VERSION ""

NS_ :

BS_:

BU_: RFA_BLEM TCU GWM _delete GENERIC TSTR

BO_ 1054 BrakeSysFeatures_3_FD2: 16 GWM
 SG_ SelDrvMdeChassis3_D_Rq : 61|5@0+ (1,0) [0|31] "SED"  GENERIC,_delete
 SG_ RbaBrk_D_Stat : 63|2@0+ (1,0) [0|3] "SED"  GENERIC,_delete
 SG_ SelDrvMdeChassis2_D_Rq : 45|5@0+ (1,0) [0|31] "SED"  GENERIC,_delete
 SG_ BrkBstrLoLampOn_B_Rq : 24|1@0+ (1,0) [0|1] "SED"  GENERIC,_delete
 SG_ TrailCtl_D_Stat : 55|3@0+ (1,0) [0|7] "SED"  GENERIC
 SG_ TrailCtlMsgTxt_D_Rq : 52|4@0+ (1,0) [0|15] "SED"  GENERIC
 SG_ BrkPadMsgTxt_D_Rq : 31|2@0+ (1,0) [0|3] "SED"  GENERIC,_delete
 SG_ BrkBstrVac_D_Stat : 18|2@0+ (1,0) [0|3] "SED"  GENERIC,_delete
 SG_ DrvSlipCtlOffLamp_D_Rq : 23|2@0+ (1,0) [0|3] "SED"  GENERIC,TCU,_delete
 SG_ DrvSlipCtlMdeMsg_D_Rq : 13|5@0+ (1,0) [0|31] "SED"  GENERIC,_delete
 SG_ HdcOn_B_Ind : 16|1@0+ (1,0) [0|1] "SED"  GENERIC
 SG_ AutoHoldMsgTxt_D_Rq : 4|4@0+ (1,0) [0|15] "SED"  GENERIC,_delete
 SG_ CtaBrk_D_Stat : 47|2@0+ (1,0) [0|3] "SED"  GENERIC,_delete
 SG_ SelDrvMdeAwd_D_Rq : 29|5@0+ (1,0) [0|31] "SED"  GENERIC
 SG_ AutoHoldSwMde_B_Ind : 0|1@0+ (1,0) [0|1] "SED"  GENERIC,_delete
 SG_ AutoHoldMde_D_Ind : 15|2@0+ (1,0) [0|3] "SED"  GENERIC,_delete
 SG_ BrkMdeInhbt_B_RqDsply : 8|1@0+ (1,0) [0|1] "SED"  GENERIC,_delete
 SG_ BrkLineLck_D_Stat : 21|3@0+ (1,0) [0|7] "SED"  GENERIC,_delete
 SG_ SelDrvMdeChassis_D_Rq : 39|5@0+ (1,0) [0|31] "SED"  GENERIC,_delete
 SG_ ApaBrk_D_Stat : 34|2@0+ (1,0) [0|3] "SED"  GENERIC,_delete,RFA_BLEM
 SG_ FrontDiffElckrOpen_B_Rq : 48|1@0+ (1,0) [0|1] "SED"  GENERIC,_delete
 SG_ OnePdlDrvDeny_B_Stat : 40|1@0+ (1,0) [0|1] "SED"  GENERIC,_delete
 SG_ BrkDrvMde_D_Stat : 7|3@0+ (1,0) [0|7] "SED"  GENERIC,_delete
 SG_ TrailOnePdlTqLm_B_Actl : 56|1@0+ (1,0) [0|1] "SED"  GENERIC,_delete

BO_ 931 Body_Info_9_FD2: 16 GWM
 SG_ VehOnSrc_D_Stat : 19|4@0+ (1,0) [0|15] "SED"  GENERIC,_delete,RFA_BLEM
 SG_ StrtrMtrCtlDStat_No_Cs : 31|8@0+ (1,0) [0|255] "unitless"  GENERIC,_delete
 SG_ EngStrtActv_B_Stat : 39|1@0+ (1,0) [0|1] "SED"  GENERIC,_delete
 SG_ EngStrt_B_Rq : 0|1@0+ (1,0) [0|1] "SED"  GENERIC,_delete
 SG_ DrvInCtl_B_Stat : 1|1@0+ (1,0) [0|1] "SED"  GENERIC,_delete
 SG_ PtWakeReas_D_Stat : 38|4@0+ (1,0) [0|15] "SED"  GENERIC,_delete
 SG_ CrnkInhbt_No_Cs : 15|8@0+ (1,0) [0|255] "unitless"  GENERIC,_delete
 SG_ CrnkInhbt_No_Cnt : 6|4@0+ (1,0) [0|15] "unitless"  GENERIC,_delete
 SG_ CrnkInhbt_B_Stat : 7|1@0+ (1,0) [0|1] "SED"  GENERIC,_delete
 SG_ AdvStrt_No_Stat : 23|4@0+ (1,0) [0|15] "unitless"  GENERIC,_delete
 SG_ IgnPreOffActv_B_Stat : 2|1@0+ (1,0) [0|1] "SED"  GENERIC,_delete

BO_ 130 EPAS_INFO_FD2: 16 GWM
 SG_ TrlrHitchLamp_D_Rqst : 24|1@0+ (1,0) [0|1] "SED"  GENERIC,_delete
 SG_ VehVTrlrAid_B_Rq : 25|1@0+ (1,0) [0|1] "SED"  GENERIC,_delete
 SG_ SteEffort_D_Stat : 52|3@0+ (1,0) [0|7] "SED"  GENERIC,_delete
 SG_ Veh_V_RqMxTrlrAid : 63|8@0+ (0.1,0) [0|25.5] "km/h"  GENERIC,_delete
 SG_ DrvSteActv_B_Stat : 10|1@0+ (1,0) [0|1] "SED"  GENERIC,_delete
 SG_ DrvSte_Tq_Actl : 47|8@0+ (0.0625,-8) [-8|7.8125] "Nm"  GENERIC,_delete
 SG_ SteMdule_D_Stat : 55|3@0+ (1,0) [0|7] "SED"  GENERIC,_delete
 SG_ SteMdule_U_Meas : 39|8@0+ (0.05,6) [6|18.7] "Volts"  GENERIC,_delete
 SG_ SteMdule_I_Est : 21|12@0+ (0.05,-64) [-64|140.7] "Amps"  GENERIC,_delete
 SG_ EPAS_Failure : 9|2@0+ (1,0) [0|3] "SED"  GENERIC,_delete
 SG_ SteeringColumnTorque : 7|8@0+ (0.0625,-8) [-8|7.8125] "Nm"  GENERIC,_delete,RFA_BLEM
 SG_ SAPPAngleControlStat6 : 15|1@0+ (1,0) [0|1] "SED"  GENERIC,_delete
 SG_ SAPPAngleControlStat5 : 14|1@0+ (1,0) [0|1] "SED"  GENERIC,_delete
 SG_ SAPPAngleControlStat4 : 13|1@0+ (1,0) [0|1] "SED"  GENERIC,_delete
 SG_ SAPPAngleControlStat3 : 12|1@0+ (1,0) [0|1] "SED"  GENERIC,_delete
 SG_ SAPPAngleControlStat2 : 11|1@0+ (1,0) [0|1] "SED"  GENERIC,_delete,RFA_BLEM
 SG_ SAPPAngleControlStat1 : 23|2@0+ (1,0) [0|3] "SED"  GENERIC,_delete,RFA_BLEM

BO_ 1046 BrakeSysFeatures_2_FD2: 16 GWM
 SG_ PrkBrkDynmc_D_Allw : 39|2@0+ (1,0) [0|3] "SED"  GENERIC,_delete
 SG_ BrkPrkBrkDynmc_B_Actl : 24|1@0+ (1,0) [0|1] "SED"  GENERIC,_delete
 SG_ ReserveTracCtlPtActv : 28|1@0+ (1,0) [0|1] "SED"  GENERIC,_delete
 SG_ HsaMde_D_Mem : 33|2@0+ (1,0) [0|3] "SED"  GENERIC,_delete
 SG_ BrkBstrVac_B_Rq : 27|1@0+ (1,0) [0|1] "Discrete"  GENERIC,_delete
 SG_ HdcMde_D_Actl : 31|3@0+ (1,0) [0|7] "SED"  GENERIC
 SG_ RearDiffLck_Tq2_RqMx : 51|12@0+ (4,0) [0|16376] "Nm"  GENERIC
 SG_ TRLR_SWAY_EVNT_IN_PROG : 25|1@0+ (1,0) [0|1] "SED"  GENERIC,_delete
 SG_ TRLR_SWAY_CONFIG_STAT : 26|1@0+ (1,0) [0|1] "SED"  GENERIC,_delete
 SG_ TCMode : 15|1@0+ (1,0) [0|1] "SED"  GENERIC,TCU,_delete,RFA_BLEM
 SG_ DrvSlipCtlLamp_D_Rq : 42|2@0+ (1,0) [0|3] "SED"  GENERIC,TCU,_delete
 SG_ Abs_B_Falt : 5|1@0+ (1,0) [0|1] "SED"  GENERIC,TCU,_delete
 SG_ DrvSlipCtlMde_D_Ind : 44|2@0+ (1,0) [0|3] "SED"  GENERIC,_delete
 SG_ DrvAntiLckLamp_D_Rq : 55|2@0+ (1,0) [0|3] "SED"  GENERIC,_delete
 SG_ BpedMove_No_Cnt : 3|4@0+ (1,0) [0|15] "unitless"  GENERIC,_delete
 SG_ StabCtlBrk_B_Avail : 4|1@0+ (1,0) [0|1] "SED"  GENERIC,_delete
 SG_ DrvHdcWarnInfo_D_Rq : 35|2@0+ (1,0) [0|3] "SED"  GENERIC
 SG_ DrvHdcMsg_D_Rq : 10|3@0+ (1,0) [0|7] "SED"  GENERIC
 SG_ DrvHdcLampInfo_D_Rq : 12|2@0+ (1,0) [0|3] "SED"  GENERIC
 SG_ BpedMove_D_Actl : 7|2@0+ (1,0) [0|3] "SED"  GENERIC,_delete
 SG_ ChimeBrk_B_Rq : 14|1@0+ (1,0) [0|1] "SED"  GENERIC,_delete
 SG_ BrkLamp_B_Rq : 13|1@0+ (1,0) [0|1] "SED"  GENERIC,_delete
 SG_ HILL_DESC_MC : 47|3@0+ (1,0) [0|7] "SED"  GENERIC
 SG_ BpedDiffLckTq_No_Cs : 23|8@0+ (1,0) [0|255] "unitless"  GENERIC,_delete
 SG_ RearDiffElckrOpen_B_Rq : 40|1@0+ (1,0) [0|1] "SED"  GENERIC

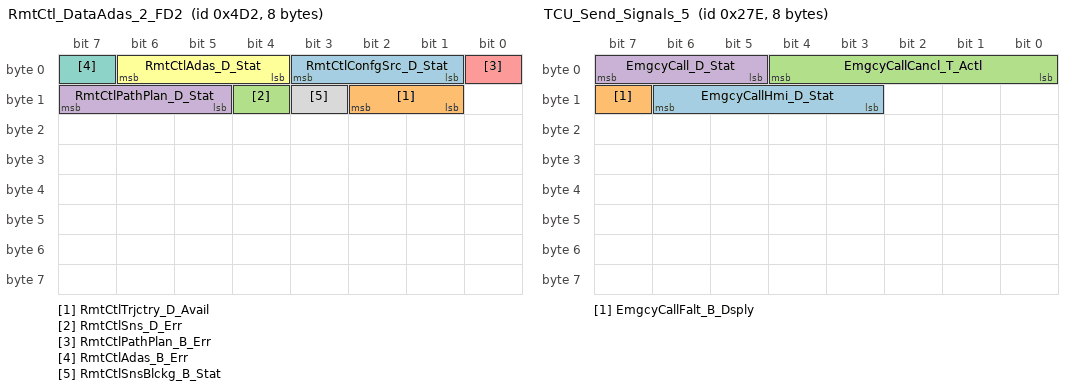
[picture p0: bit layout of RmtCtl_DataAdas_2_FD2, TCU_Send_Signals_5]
BO_ 1234 RmtCtl_DataAdas_2_FD2: 8 GWM
 SG_ RmtCtlConfgSrc_D_Stat : 3|3@0+ (1,0) [0|7] "SED"  GENERIC,_delete,RFA_BLEM
 SG_ RmtCtlTrjctry_D_Avail : 10|2@0+ (1,0) [0|3] "SED"  GENERIC,_delete,RFA_BLEM
 SG_ RmtCtlSns_D_Err : 12|1@0+ (1,0) [0|1] "SED"  GENERIC,_delete,RFA_BLEM
 SG_ RmtCtlPathPlan_D_Stat : 15|3@0+ (1,0) [0|7] "SED"  GENERIC,_delete,RFA_BLEM
 SG_ RmtCtlPathPlan_B_Err : 0|1@0+ (1,0) [0|1] "SED"  GENERIC,_delete,RFA_BLEM
 SG_ RmtCtlAdas_D_Stat : 6|3@0+ (1,0) [0|7] "SED"  GENERIC,_delete,RFA_BLEM
 SG_ RmtCtlAdas_B_Err : 7|1@0+ (1,0) [0|1] "SED"  GENERIC,_delete,RFA_BLEM
 SG_ RmtCtlSnsBlckg_B_Stat : 11|1@0+ (1,0) [0|1] "SED"  GENERIC,_delete,RFA_BLEM

BO_ 1233 RmtCtl_DataAdas_1_FD2: 8 GWM
 SG_ RmtCtlLeft_D_Avail : 3|2@0+ (1,0) [0|3] "SED"  GENERIC,_delete,RFA_BLEM
 SG_ RmtCtlFront_D_Avail : 5|2@0+ (1,0) [0|3] "SED"  GENERIC,_delete,RFA_BLEM
 SG_ FreeDrvRear_D_Avail : 27|2@0+ (1,0) [0|3] "SED"  GENERIC,_delete,RFA_BLEM
 SG_ FreeDrvFwd_D_Avail : 7|2@0+ (1,0) [0|3] "SED"  GENERIC,_delete,RFA_BLEM
 SG_ RmtCtlTrgDist_D_Stat : 63|8@0+ (0.1,0) [0|25.5] "meter"  GENERIC,_delete,RFA_BLEM
 SG_ RmtCtlSnsRrCrnr_D_Stat : 55|2@0+ (1,0) [0|3] "SED"  GENERIC,_delete,RFA_BLEM
 SG_ RmtCtlSnsRlCrnr_D_Stat : 49|2@0+ (1,0) [0|3] "SED"  GENERIC,_delete,RFA_BLEM
 SG_ RmtCtlSnsRear_D_Stat : 51|2@0+ (1,0) [0|3] "SED"  GENERIC,_delete,RFA_BLEM
 SG_ RmtCtlSnsFront_D_Stat : 53|2@0+ (1,0) [0|3] "SED"  GENERIC,_delete,RFA_BLEM
 SG_ RmtCtlSnsFrCrnr_D_Stat : 41|2@0+ (1,0) [0|3] "SED"  GENERIC,_delete,RFA_BLEM
 SG_ RmtCtlSnsFlCrnr_D_Stat : 43|2@0+ (1,0) [0|3] "SED"  GENERIC,_delete,RFA_BLEM
 SG_ RmtCtlSideSnsR4_D_Stat : 45|2@0+ (1,0) [0|3] "SED"  GENERIC,_delete,RFA_BLEM
 SG_ RmtCtlSideSnsR3_D_Stat : 47|2@0+ (1,0) [0|3] "SED"  GENERIC,_delete,RFA_BLEM
 SG_ RmtCtlSideSnsR2_D_Stat : 33|2@0+ (1,0) [0|3] "SED"  GENERIC,_delete,RFA_BLEM
 SG_ RmtCtlSideSnsR1_D_Stat : 35|2@0+ (1,0) [0|3] "SED"  GENERIC,_delete,RFA_BLEM
 SG_ RmtCtlSideSnsL4_D_Stat : 37|2@0+ (1,0) [0|3] "SED"  GENERIC,_delete,RFA_BLEM
 SG_ RmtCtlSideSnsL3_D_Stat : 39|2@0+ (1,0) [0|3] "SED"  GENERIC,_delete,RFA_BLEM
 SG_ RmtCtlSideSnsL2_D_Stat : 25|2@0+ (1,0) [0|3] "SED"  GENERIC,_delete,RFA_BLEM
 SG_ RmtCtlSideSnsL1_D_Stat : 17|2@0+ (1,0) [0|3] "SED"  GENERIC,_delete,RFA_BLEM
 SG_ RmtCtlRightOrnt_D_Avail : 20|3@0+ (1,0) [0|7] "SED"  GENERIC,_delete,RFA_BLEM
 SG_ RmtCtlRight_D_Avail : 31|2@0+ (1,0) [0|3] "SED"  GENERIC,_delete,RFA_BLEM
 SG_ RmtCtlRear_D_Avail : 29|2@0+ (1,0) [0|3] "SED"  GENERIC,_delete,RFA_BLEM
 SG_ RmtCtlPrkMde_D_Stat : 9|2@0+ (1,0) [0|3] "SED"  GENERIC,_delete,RFA_BLEM
 SG_ RmtCtlPrkInSlot_D_Stat : 23|3@0+ (1,0) [0|7] "SED"  GENERIC,_delete,RFA_BLEM
 SG_ RmtCtlObstcl_B_Stat : 10|1@0+ (1,0) [0|1] "SED"  GENERIC,_delete,RFA_BLEM
 SG_ RmtCtlNxtMoveDir_D_Stat : 12|2@0+ (1,0) [0|3] "SED"  GENERIC,_delete,RFA_BLEM
 SG_ RmtCtlMoveDir_D_Stat : 1|2@0+ (1,0) [0|3] "SED"  GENERIC,_delete,RFA_BLEM
 SG_ RmtCtlLeftOrnt_D_Avail : 15|3@0+ (1,0) [0|7] "SED"  GENERIC,_delete,RFA_BLEM

BO_ 125 BrakeSnData_4_FD2: 16 GWM
 SG_ VehRolComp_W_Actl : 51|12@0+ (0.03663,-75) [-75|74.92659] "degrees/sec"  GENERIC,_delete
 SG_ VehVertComp_A_Actl : 45|10@0+ (0.035,-17.9) [-17.9|17.835] "m/s^2"  GENERIC,_delete
 SG_ BrkTotTqRqArb_No_Cs : 23|8@0+ (1,0) [0|255] "unitless"  GENERIC,_delete
 SG_ BrkTotTqRqArb_No_Cnt : 31|4@0+ (1,0) [0|15] "unitless"  GENERIC,_delete
 SG_ BrkTot_Tq_RqArb : 4|13@0+ (4,0) [0|32756] "Nm"  GENERIC,_delete,TCU
 SG_ BrkTot_Tq_Actl : 27|13@0+ (4,0) [0|32756] "Nm"  GENERIC,_delete
 SG_ HsaStat_D_Actl : 7|3@0+ (1,0) [0|7] "SED"  GENERIC,_delete

BO_ 531 DesiredTorqBrk_FD2: 16 GWM
 SG_ VehStop_D_Stat : 28|2@0+ (1,0) [0|3] "SED"  GENERIC,_delete
 SG_ TracCtlPtActv_B_Actl : 31|1@0+ (1,0) [0|1] "SED"  GENERIC,_delete,TCU,RFA_BLEM
 SG_ LscmbbMntr_B_Err : 17|1@0+ (1,0) [0|1] "SED"  GENERIC,_delete
 SG_ LscmbbBrkDis_B_Actl : 19|1@0+ (1,0) [0|1] "SED"  GENERIC,_delete
 SG_ LscmbbDeny_B_ActlBrk : 18|1@0+ (1,0) [0|1] "SED"  GENERIC,_delete
 SG_ PrkBrkYwLamp_D_Rq : 38|2@0+ (1,0) [0|3] "SED"  GENERIC,_delete
 SG_ PrkBrkRedLamp_D_Rq : 30|2@0+ (1,0) [0|3] "SED"  GENERIC,_delete
 SG_ VehicleStationary : 39|1@0+ (1,0) [0|1] "SED"  GENERIC,_delete
 SG_ LscmbbBrkDecel_B_Actl : 20|1@0+ (1,0) [0|1] "SED"  GENERIC,_delete,TCU
 SG_ AbsActv_B_Actl : 45|1@0+ (1,0) [0|1] "SED"  GENERIC,_delete,TCU,RFA_BLEM
 SG_ StabCtlBrkActv_B_Actl : 23|1@0+ (1,0) [0|1] "SED"  GENERIC,_delete,TCU,RFA_BLEM
 SG_ CmbbBrkPrchg_B_Actl : 59|1@0+ (1,0) [0|1] "SED"  GENERIC,_delete
 SG_ CmbbBrkDecel_B_Actl : 58|1@0+ (1,0) [0|1] "SED"  GENERIC,_delete
 SG_ CmbbBaSensInc_B_Actl : 57|1@0+ (1,0) [0|1] "SED"  GENERIC,_delete
 SG_ AccBrkWarm_B_Actl : 63|1@0+ (1,0) [0|1] "SED"  GENERIC,_delete
 SG_ AccBrkTotTqMn_B_Actl : 62|1@0+ (1,0) [0|1] "SED"  GENERIC
 SG_ AccBrkPrchgActv_B_Actl : 61|1@0+ (1,0) [0|1] "SED"  GENERIC,_delete
 SG_ AccBrkDis_B_Actl : 44|1@0+ (1,0) [0|1] "SED"  GENERIC,_delete
 SG_ AccBrkDeny_B_Actl : 42|1@0+ (1,0) [0|1] "SED"  GENERIC,_delete
 SG_ AccBrkActv_B_Actl : 43|1@0+ (1,0) [0|1] "SED"  GENERIC,_delete
 SG_ PrplDrgCtlActv_B_Actl : 46|1@0+ (1,0) [0|1] "SED"  GENERIC,_delete
 SG_ PrplWhlTot_Tq_RqMx : 7|16@0+ (4,-131072) [-131072|131068] "Nm"  GENERIC,_delete
 SG_ LscmbbBaSensInc_B_Actl : 21|1@0+ (1,0) [0|1] "SED"  GENERIC,_delete
 SG_ CmbbBrkDis_B_Actl : 56|1@0+ (1,0) [0|1] "SED"  GENERIC,_delete
 SG_ CmbbDeny_B_ActlBrk : 60|1@0+ (1,0) [0|1] "SED"  GENERIC,_delete
 SG_ CcDis_B_Cmd : 47|1@0+ (1,0) [0|1] "SED"  GENERIC,_delete
 SG_ VehLongOvrGnd_A_Est : 41|10@0+ (0.035,-17.9) [-17.9|17.835] "m/s^2"  GENERIC,_delete
 SG_ LscmbBrkPrchg_B_Actl : 16|1@0+ (1,0) [0|1] "SED"  GENERIC,_delete,TCU
 SG_ AccStopActv_B_ActlBrk : 22|1@0+ (1,0) [0|1] "SED"  GENERIC
 SG_ AccDis_B_ActlEpb : 32|1@0+ (1,0) [0|1] "SED"  GENERIC,_delete
 SG_ PrkBrkMsgTxt_D_Rq : 36|4@0+ (1,0) [0|15] "SED"  GENERIC,_delete
 SG_ PrkBrkStatus : 26|3@0+ (1,0) [0|7] "SED"  GENERIC,TCU,_delete,RFA_BLEM

BO_ 1841 TesterPhysicalReqRFA: 64 TSTR
 SG_ TesterPhysicalReqRFA : 7|64@0+ (1,0) [0|1.84467E+019] "unitless"  GENERIC,RFA_BLEM

BO_ 638 TCU_Send_Signals_5: 8 TCU
 SG_ EmgcyCallHmi_D_Stat : 14|4@0+ (1,0) [0|15] "SED"  GENERIC,GWM
 SG_ EmgcyCallFalt_B_Dsply : 15|1@0+ (1,0) [0|1] "SED"  GENERIC,GWM
 SG_ EmgcyCallCancl_T_Actl : 4|5@0+ (1,0) [0|31] "second"  GENERIC,GWM
 SG_ EmgcyCall_D_Stat : 7|3@0+ (1,0) [0|7] "SED"  GENERIC,GWM

BO_ 1184 APIM_TCU_Word_Rx: 8 TCU
 SG_ APIM_TCU_Word_Rx : 7|64@0+ (1,0) [0|1.84467440737096E+019] "unitless"  GENERIC,GWM

BO_ 894 RemoteParkAssistStat_FD2: 16 GWM
 SG_ RmtCtlTrgtBody_D_Stat : 23|40@0+ (1,0) [0|1099511627775] "unitless"  GENERIC,_delete,RFA_BLEM
 SG_ RmtCtlTrgt_D_Rq : 11|2@0+ (1,0) [0|3] "SED"  GENERIC,_delete,RFA_BLEM
 SG_ RmtCtlRngSet_D_Stat : 13|2@0+ (1,0) [0|3] "SED"  GENERIC,_delete,RFA_BLEM
 SG_ RmtCtlKeySrch_D_Stat : 15|2@0+ (1,0) [0|3] "SED"  GENERIC,_delete,RFA_BLEM
 SG_ RmtCtlBody_D_Stat : 4|4@0+ (1,0) [0|15] "SED"  GENERIC,_delete,RFA_BLEM
 SG_ RmtCtl_D_RqBody : 7|3@0+ (1,0) [0|7] "SED"  GENERIC,_delete,RFA_BLEM

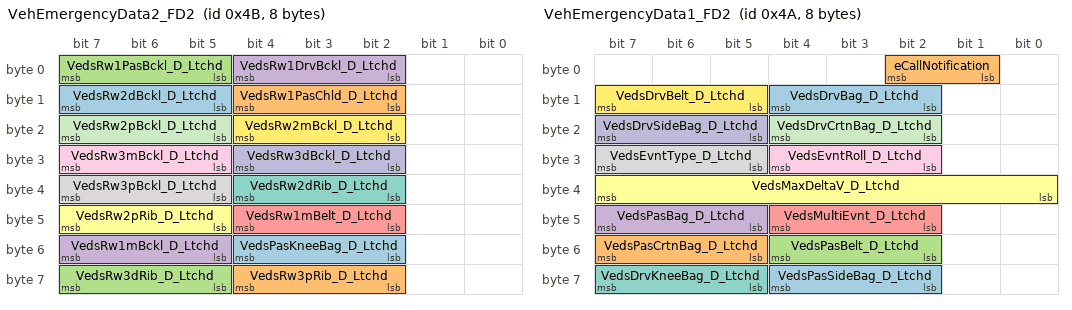
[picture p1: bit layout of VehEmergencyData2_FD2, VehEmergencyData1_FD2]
BO_ 75 VehEmergencyData2_FD2: 8 GWM
 SG_ VedsPasKneeBag_D_Ltchd : 52|3@0+ (1,0) [0|7] "SED"  GENERIC,TCU
 SG_ VedsRw3pRib_D_Ltchd : 60|3@0+ (1,0) [0|7] "SED"  GENERIC,TCU
 SG_ VedsRw3dRib_D_Ltchd : 63|3@0+ (1,0) [0|7] "SED"  GENERIC,TCU
 SG_ VedsRw1mBckl_D_Ltchd : 55|3@0+ (1,0) [0|7] "SED"  GENERIC,TCU
 SG_ VedsRw1mBelt_D_Ltchd : 44|3@0+ (1,0) [0|7] "SED"  GENERIC,TCU
 SG_ VedsRw2pRib_D_Ltchd : 47|3@0+ (1,0) [0|7] "SED"  GENERIC,TCU
 SG_ VedsRw2dRib_D_Ltchd : 36|3@0+ (1,0) [0|7] "SED"  GENERIC,TCU
 SG_ VedsRw3pBckl_D_Ltchd : 39|3@0+ (1,0) [0|7] "SED"  GENERIC,TCU
 SG_ VedsRw3mBckl_D_Ltchd : 31|3@0+ (1,0) [0|7] "SED"  GENERIC,TCU
 SG_ VedsRw3dBckl_D_Ltchd : 28|3@0+ (1,0) [0|7] "SED"  GENERIC,TCU
 SG_ VedsRw2pBckl_D_Ltchd : 23|3@0+ (1,0) [0|7] "SED"  GENERIC,TCU
 SG_ VedsRw2mBckl_D_Ltchd : 20|3@0+ (1,0) [0|7] "SED"  GENERIC,TCU
 SG_ VedsRw2dBckl_D_Ltchd : 15|3@0+ (1,0) [0|7] "SED"  GENERIC,TCU
 SG_ VedsRw1PasChld_D_Ltchd : 12|3@0+ (1,0) [0|7] "SED"  GENERIC,TCU
 SG_ VedsRw1PasBckl_D_Ltchd : 7|3@0+ (1,0) [0|7] "SED"  GENERIC,TCU
 SG_ VedsRw1DrvBckl_D_Ltchd : 4|3@0+ (1,0) [0|7] "SED"  GENERIC,TCU

BO_ 74 VehEmergencyData1_FD2: 8 GWM
 SG_ VedsPasSideBag_D_Ltchd : 60|3@0+ (1,0) [0|7] "SED"  GENERIC,TCU
 SG_ VedsPasCrtnBag_D_Ltchd : 55|3@0+ (1,0) [0|7] "SED"  GENERIC,TCU
 SG_ VedsPasBelt_D_Ltchd : 52|3@0+ (1,0) [0|7] "SED"  GENERIC,TCU
 SG_ VedsPasBag_D_Ltchd : 47|3@0+ (1,0) [0|7] "SED"  GENERIC,TCU
 SG_ VedsMultiEvnt_D_Ltchd : 44|3@0+ (1,0) [0|7] "SED"  GENERIC,TCU
 SG_ VedsMaxDeltaV_D_Ltchd : 39|8@0+ (1,0) [0|255] "kph"  GENERIC,TCU
 SG_ VedsDrvKneeBag_D_Ltchd : 63|3@0+ (1,0) [0|7] "SED"  GENERIC,TCU
 SG_ VedsEvntType_D_Ltchd : 31|3@0+ (1,0) [0|7] "SED"  GENERIC,TCU
 SG_ VedsEvntRoll_D_Ltchd : 28|3@0+ (1,0) [0|7] "SED"  GENERIC,TCU
 SG_ VedsDrvSideBag_D_Ltchd : 23|3@0+ (1,0) [0|7] "SED"  GENERIC,TCU
 SG_ VedsDrvCrtnBag_D_Ltchd : 20|3@0+ (1,0) [0|7] "SED"  GENERIC,TCU
 SG_ VedsDrvBelt_D_Ltchd : 15|3@0+ (1,0) [0|7] "SED"  GENERIC,TCU
 SG_ VedsDrvBag_D_Ltchd : 12|3@0+ (1,0) [0|7] "SED"  GENERIC,TCU
 SG_ eCallNotification : 2|2@0+ (1,0) [0|3] "SED"  GENERIC,TCU

BO_ 382 EngineData_Gas_FD2: 8 GWM
 SG_ DcacOut_E_Tot : 55|16@0+ (20,0) [0|1310700] "watt*hour"  GENERIC,_delete,TCU
 SG_ EngIdlShutDown_D2_Type : 26|2@0+ (1,0) [0|3] "SED"  GENERIC

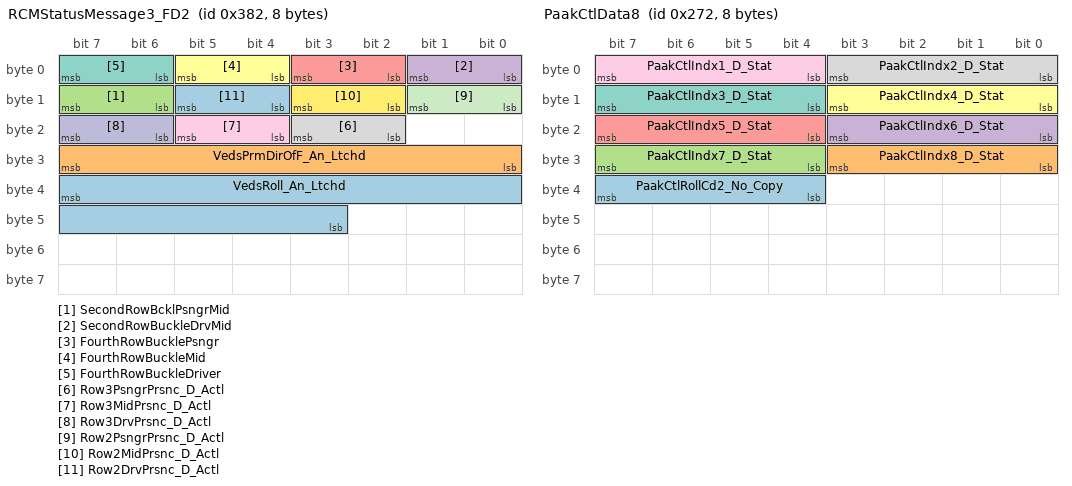
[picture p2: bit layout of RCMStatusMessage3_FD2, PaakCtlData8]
BO_ 898 RCMStatusMessage3_FD2: 8 GWM
 SG_ VedsRoll_An_Ltchd : 39|13@0+ (0.5,-2048) [-2047.5|2046.5] "degree"  GENERIC,_delete,TCU
 SG_ VedsPrmDirOfF_An_Ltchd : 31|8@0+ (2,-180) [-178|326] "degree"  GENERIC,_delete,TCU
 SG_ SecondRowBcklPsngrMid : 15|2@0+ (1,0) [0|3] "SED"  GENERIC
 SG_ SecondRowBuckleDrvMid : 1|2@0+ (1,0) [0|3] "SED"  GENERIC
 SG_ FourthRowBucklePsngr : 3|2@0+ (1,0) [0|3] "SED"  GENERIC
 SG_ FourthRowBuckleMid : 5|2@0+ (1,0) [0|3] "SED"  GENERIC
 SG_ FourthRowBuckleDriver : 7|2@0+ (1,0) [0|3] "SED"  GENERIC
 SG_ Row3PsngrPrsnc_D_Actl : 19|2@0+ (1,0) [0|3] "SED"  GENERIC
 SG_ Row3MidPrsnc_D_Actl : 21|2@0+ (1,0) [0|3] "SED"  GENERIC
 SG_ Row3DrvPrsnc_D_Actl : 23|2@0+ (1,0) [0|3] "SED"  GENERIC
 SG_ Row2PsngrPrsnc_D_Actl : 9|2@0+ (1,0) [0|3] "SED"  GENERIC
 SG_ Row2MidPrsnc_D_Actl : 11|2@0+ (1,0) [0|3] "SED"  GENERIC
 SG_ Row2DrvPrsnc_D_Actl : 13|2@0+ (1,0) [0|3] "SED"  GENERIC

BO_ 536 WheelBrakeTorque_FD2: 16 GWM
 SG_ PrkBrkAppl_D_Stat : 51|3@0+ (1,0) [0|7] "SED"  GENERIC
 SG_ BrkCtlSys_D_Stat : 55|4@0+ (1,0) [0|15] "SED"  GENERIC,_delete,TCU
 SG_ VehStab_D_Cnfm : 43|4@0+ (1,0) [0|15] "SED"  GENERIC
 SG_ BrkWhlFricTq_No_Cs : 39|8@0+ (1,0) [0|255] "Unitless"  GENERIC
 SG_ BrkWhlFricTq_No_Cnt : 47|4@0+ (1,0) [0|15] "Unitless"  GENERIC
 SG_ BrkWhlFricRr_Tq_Actl : 31|8@0+ (20,0) [0|5060] "Nm"  GENERIC
 SG_ BrkWhlFricRl_Tq_Actl : 23|8@0+ (20,0) [0|5060] "Nm"  GENERIC
 SG_ BrkWhlFricFr_Tq_Actl : 15|8@0+ (20,0) [0|5060] "Nm"  GENERIC
 SG_ BrkWhlFricFl_Tq_Actl : 7|8@0+ (20,0) [0|5060] "Nm"  GENERIC

BO_ 626 PaakCtlData8: 8 RFA_BLEM
 SG_ PaakCtlRollCd2_No_Copy : 39|4@0+ (1,0) [0|15] "unitless"  GENERIC,GWM
 SG_ PaakCtlIndx8_D_Stat : 27|4@0+ (1,0) [0|15] "SED"  GENERIC,GWM
 SG_ PaakCtlIndx7_D_Stat : 31|4@0+ (1,0) [0|15] "SED"  GENERIC,GWM
 SG_ PaakCtlIndx6_D_Stat : 19|4@0+ (1,0) [0|15] "SED"  GENERIC,GWM
 SG_ PaakCtlIndx5_D_Stat : 23|4@0+ (1,0) [0|15] "SED"  GENERIC,GWM
 SG_ PaakCtlIndx4_D_Stat : 11|4@0+ (1,0) [0|15] "SED"  GENERIC,GWM
 SG_ PaakCtlIndx3_D_Stat : 15|4@0+ (1,0) [0|15] "SED"  GENERIC,GWM
 SG_ PaakCtlIndx2_D_Stat : 3|4@0+ (1,0) [0|15] "SED"  GENERIC,GWM
 SG_ PaakCtlIndx1_D_Stat : 7|4@0+ (1,0) [0|15] "SED"  GENERIC,GWM

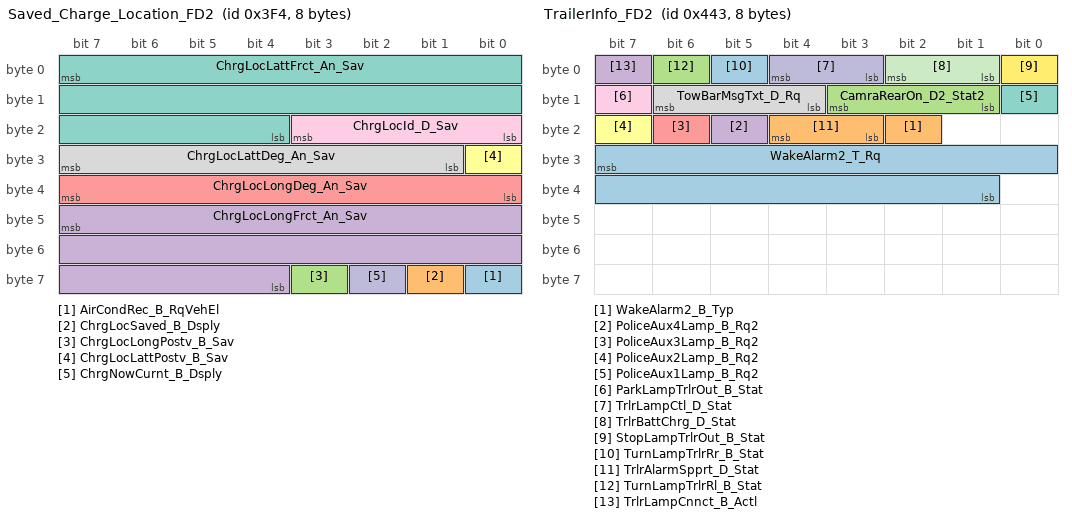
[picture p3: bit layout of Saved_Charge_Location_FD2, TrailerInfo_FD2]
BO_ 1012 Saved_Charge_Location_FD2: 8 GWM
 SG_ AirCondRec_B_RqVehEl : 56|1@0+ (1,0) [0|1] "SED"  GENERIC,_delete
 SG_ ChrgLocSaved_B_Dsply : 57|1@0+ (1,0) [0|1] "SED"  GENERIC,_delete
 SG_ ChrgLocLongPostv_B_Sav : 59|1@0+ (1,0) [0|1] "SED"  GENERIC,_delete
 SG_ ChrgLocLongFrct_An_Sav : 47|20@0+ (1E-006,0) [0|1.048575] "degrees"  GENERIC,_delete
 SG_ ChrgLocLongDeg_An_Sav : 39|8@0+ (1,0) [0|255] "degrees"  GENERIC,_delete
 SG_ ChrgLocLattPostv_B_Sav : 24|1@0+ (1,0) [0|1] "SED"  GENERIC,_delete
 SG_ ChrgLocLattFrct_An_Sav : 7|20@0+ (1E-006,0) [0|1.048575] "degrees"  GENERIC,_delete
 SG_ ChrgLocLattDeg_An_Sav : 31|7@0+ (1,0) [0|127] "unitless"  GENERIC,_delete
 SG_ ChrgLocId_D_Sav : 19|4@0+ (1,0) [0|15] "unitless"  GENERIC,_delete
 SG_ ChrgNowCurnt_B_Dsply : 58|1@0+ (1,0) [0|1] "SED"  GENERIC,_delete

BO_ 2612002008 PARSEDFuncGWM_ECG_FD2: 64 GWM
 SG_ PARSEDFuncGWM_ECG : 7|29@0+ (1,0) [0|536870911] "unitless"  GENERIC,RFA_BLEM,TCU

BO_ 2610953432 OTAFuncGWM_ECG_FD2: 64 GWM
 SG_ OTAFuncGWM_ECG : 7|29@0+ (1,0) [0|536870911] "unitless"  GENERIC,RFA_BLEM,TCU

BO_ 516 EngVehicleSpThrottle_FD2: 16 GWM
 SG_ EngAoutNActl_D_QF : 31|2@0+ (1,0) [0|3] "SED"  GENERIC,_delete
 SG_ EngAout3_N_Actl : 55|16@0+ (0.25,0) [0|16383.5] "RPM"  GENERIC,_delete
 SG_ ApedPos_Pc_ActlArb : 1|10@0+ (0.1,0) [0|102.3] "%"  GENERIC,_delete,RFA_BLEM
 SG_ ApedPosPcActl_D_Qf : 7|2@0+ (1,0) [0|3] "SED"  GENERIC,_delete
 SG_ EngAout_N_Actl : 28|13@0+ (2,0) [0|16382] "rpm"  GENERIC,_delete
 SG_ ApedPosPcActl_No_Cnt : 5|4@0+ (1,0) [0|15] "unitless"  GENERIC,_delete
 SG_ ApedPosPcActl_No_Cs : 47|8@0+ (1,0) [0|255] "unitless"  GENERIC,_delete
 SG_ ApedPos_PcRate_ActlArb : 23|8@0+ (0.04,-5) [-5|5.12] "%/ms"  GENERIC,_delete

BO_ 1091 TrailerInfo_FD2: 8 GWM
 SG_ WakeAlarm2_T_Rq : 31|15@0+ (1,0) [0|32767] "minute"  GENERIC,_delete
 SG_ WakeAlarm2_B_Typ : 18|1@0+ (1,0) [0|1] "SED"  GENERIC,_delete
 SG_ CamraRearOn_D2_Stat2 : 11|3@0+ (1,0) [0|7] "SED"  GENERIC,_delete
 SG_ PoliceAux4Lamp_B_Rq2 : 21|1@0+ (1,0) [0|1] "SED"  GENERIC,_delete
 SG_ PoliceAux3Lamp_B_Rq2 : 22|1@0+ (1,0) [0|1] "SED"  GENERIC,_delete
 SG_ PoliceAux2Lamp_B_Rq2 : 23|1@0+ (1,0) [0|1] "SED"  GENERIC,_delete
 SG_ PoliceAux1Lamp_B_Rq2 : 8|1@0+ (1,0) [0|1] "SED"  GENERIC,_delete
 SG_ TowBarMsgTxt_D_Rq : 14|3@0+ (1,0) [0|7] "SED"  GENERIC,_delete
 SG_ ParkLampTrlrOut_B_Stat : 15|1@0+ (1,0) [0|1] "SED"  GENERIC,_delete
 SG_ TrlrLampCtl_D_Stat : 4|2@0+ (1,0) [0|3] "SED"  GENERIC
 SG_ TrlrBattChrg_D_Stat : 2|2@0+ (1,0) [0|3] "SED"  GENERIC,_delete
 SG_ StopLampTrlrOut_B_Stat : 0|1@0+ (1,0) [0|1] "SED"  GENERIC,_delete
 SG_ TurnLampTrlrRr_B_Stat : 5|1@0+ (1,0) [0|1] "SED"  GENERIC,_delete
 SG_ TrlrAlarmSpprt_D_Stat : 20|2@0+ (1,0) [0|3] "SED"  GENERIC,_delete
 SG_ TurnLampTrlrRl_B_Stat : 6|1@0+ (1,0) [0|1] "SED"  GENERIC,_delete
 SG_ TrlrLampCnnct_B_Actl : 7|1@0+ (1,0) [0|1] "SED"  GENERIC,_delete,RFA_BLEM

BO_ 359 VehicleOperatingModes_FD2: 16 GWM
 SG_ PrplWhlRgenMn_Tq_Actl : 25|13@0+ (4,-16380) [-16380|16380] "Nm"  GENERIC,_delete
 SG_ ElPw_D_StatStrtStop : 31|4@0+ (1,0) [0|15] "SED"  GENERIC,_delete
 SG_ TrnAin_Tq_Actl : 42|11@0+ (1,-500) [-500|1547] "Nm"  GENERIC,_delete
 SG_ PrplWhlTot2_Tq_Actl : 15|16@0+ (4,-131072) [-131072|131060] "Nm"  GENERIC,_delete
 SG_ LscmbbDeny_B_ActlPrpl : 27|1@0+ (1,0) [0|1] "SED"  GENERIC,_delete
 SG_ LscmbbEngTqMn_B_Actl : 26|1@0+ (1,0) [0|1] "SED"  GENERIC,_delete
 SG_ PwPckTq_D_Stat : 5|2@0+ (1,0) [0|3] "SED"  GENERIC,_delete,RFA_BLEM
 SG_ Eng_D_Stat : 7|2@0+ (1,0) [0|3] "SED"  GENERIC,_delete
 SG_ PlgActvArb_B_Actl : 0|1@0+ (1,0) [0|1] "SED"  GENERIC,_delete
 SG_ ElPw_D_Stat : 3|3@0+ (1,0) [0|7] "SED"  GENERIC,_delete
 SG_ TrnAinTq_D_Qf : 44|2@0+ (1,0) [0|3] "SED"  GENERIC,_delete

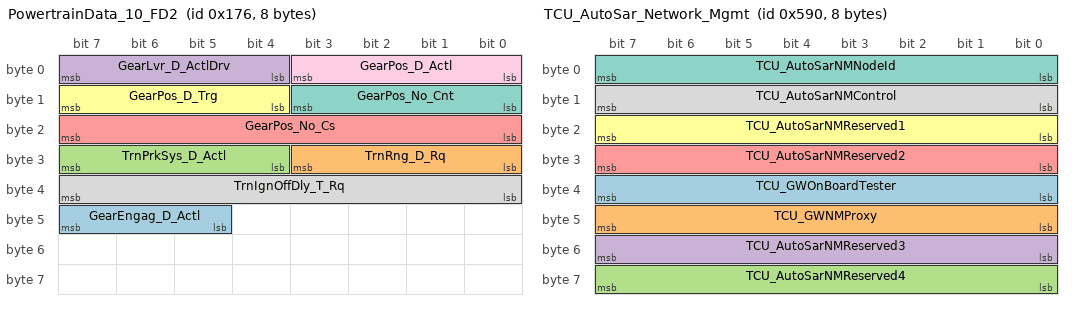
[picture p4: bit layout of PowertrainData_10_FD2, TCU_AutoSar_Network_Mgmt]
BO_ 374 PowertrainData_10_FD2: 8 GWM
 SG_ GearEngag_D_Actl : 47|3@0+ (1,0) [0|7] "SED"  GENERIC,_delete
 SG_ TrnRng_D_Rq : 27|4@0+ (1,0) [0|15] "SED"  GENERIC,TCU,_delete
 SG_ TrnPrkSys_D_Actl : 31|4@0+ (1,0) [0|15] "SED"  GENERIC,_delete,RFA_BLEM
 SG_ GearLvr_D_ActlDrv : 7|4@0+ (1,0) [0|15] "SED"  GENERIC,_delete,RFA_BLEM
 SG_ GearPos_No_Cs : 23|8@0+ (1,0) [0|255] "unitless"  GENERIC,_delete,RFA_BLEM
 SG_ GearPos_D_Trg : 15|4@0+ (1,0) [0|15] "SED"  GENERIC,_delete,RFA_BLEM
 SG_ GearPos_No_Cnt : 11|4@0+ (1,0) [0|15] "unitless"  GENERIC,_delete,RFA_BLEM
 SG_ TrnIgnOffDly_T_Rq : 39|8@0+ (4,0) [0|1020] "ms"  GENERIC,_delete
 SG_ GearPos_D_Actl : 3|4@0+ (1,0) [0|15] "SED"  GENERIC,_delete,RFA_BLEM

BO_ 702 ECG_RFA_BLEM_Word_Tx: 8 GWM
 SG_ ECG_RFA_BLEM_Word_Tx : 7|64@0+ (1,0) [0|1.84467440737096E+019] "unitless"  GENERIC,_delete,RFA_BLEM

BO_ 1876 TesterPhysicalReqTCU: 64 TSTR
 SG_ TesterPhysicalReqTCU : 7|64@0+ (1,0) [0|1.84467E+019] "unitless"  GENERIC,TCU

BO_ 1884 TesterPhysicalResTCU: 64 TCU
 SG_ TesterPhysicalResTCU : 7|64@0+ (1,0) [0|1.84467E+019] "unitless"  GENERIC,TSTR

BO_ 1424 TCU_AutoSar_Network_Mgmt: 8 TCU
 SG_ TCU_GWOnBoardTester : 39|8@0+ (1,0) [0|255] "unitless"  GENERIC
 SG_ TCU_GWNMProxy : 47|8@0+ (1,0) [0|255] "unitless"  GENERIC
 SG_ TCU_AutoSarNMReserved4 : 63|8@0+ (1,0) [0|255] "unitless"  GENERIC
 SG_ TCU_AutoSarNMReserved3 : 55|8@0+ (1,0) [0|255] "unitless"  GENERIC
 SG_ TCU_AutoSarNMReserved2 : 31|8@0+ (1,0) [0|255] "unitless"  GENERIC
 SG_ TCU_AutoSarNMReserved1 : 23|8@0+ (1,0) [0|255] "unitless"  GENERIC
 SG_ TCU_AutoSarNMNodeId : 7|8@0+ (1,0) [0|255] "unitless"  GENERIC
 SG_ TCU_AutoSarNMControl : 15|8@0+ (1,0) [0|255] "unitless"  GENERIC

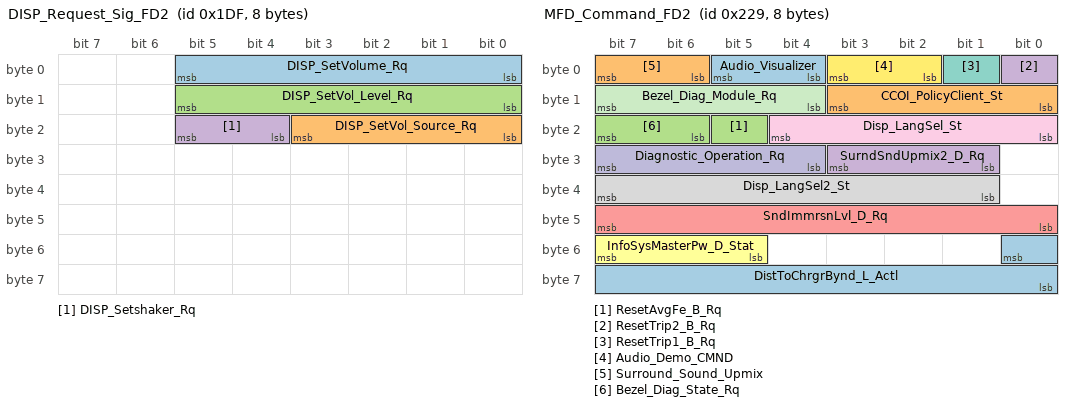
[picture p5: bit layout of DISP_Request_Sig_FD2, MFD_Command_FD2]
BO_ 479 DISP_Request_Sig_FD2: 8 GWM
 SG_ DISP_SetVolume_Rq : 5|6@0+ (1,-30) [-30|33] "steps"  GENERIC,TCU
 SG_ DISP_SetVol_Source_Rq : 19|4@0+ (1,0) [0|15] "SED"  _delete,GENERIC
 SG_ DISP_SetVol_Level_Rq : 13|6@0+ (1,0) [0|63] "unitless"  _delete,GENERIC
 SG_ DISP_Setshaker_Rq : 21|2@0+ (1,0) [0|3] "SED"  _delete,GENERIC

BO_ 765 Mc_Send_Signals_2_FD2: 8 GWM
 SG_ BalrSwtch_D_Stat : 57|2@0+ (1,0) [0|3] "SED"  GENERIC,_delete
 SG_ BalrMde_D_Rq : 59|2@0+ (1,0) [0|3] "SED"  GENERIC,_delete
 SG_ RstrnOnPsngr_D_RqMnu : 63|4@0+ (1,0) [0|15] "SED"  GENERIC,_delete
 SG_ WaitToStartLamp_D_Falt : 50|2@0+ (1,0) [0|3] "SED"  GENERIC,_delete
 SG_ EsaOn_B_Rq : 15|1@0+ (1,0) [0|1] "SED"  GENERIC,_delete
 SG_ BttOn_B_Rq : 26|1@0+ (1,0) [0|1] "SED"  GENERIC,_delete
 SG_ Btt_L_Actl : 39|7@0+ (0.1,0) [0|12.5] "meter"  GENERIC,_delete
 SG_ RearDiffLck_D_RqArb : 25|2@0+ (1,0) [0|3] "SED"  GENERIC,_delete
 SG_ AwdMde_D_RqArb : 47|3@0+ (1,0) [0|7] "SED"  GENERIC,_delete
 SG_ SelDrvMdeTxtReset_B_Rq : 40|1@0+ (1,0) [0|1] "SED"  GENERIC,_delete
 SG_ AutoTowAllw_D_RqMnu : 52|2@0+ (1,0) [0|3] "SED"  GENERIC,_delete
 SG_ DrvInputRequired_B_Rq : 32|1@0+ (1,0) [0|1] "SED"  GENERIC,_delete
 SG_ SelDrvMdeDsply_B_Avail : 41|1@0+ (1,0) [0|1] "SED"  GENERIC,_delete
 SG_ EngExhMdeQuiet_D_Rq : 17|2@0+ (1,0) [0|3] "SED"  GENERIC,_delete
 SG_ AirSusp_D_RqDrv : 31|2@0+ (1,0) [0|3] "SED"  GENERIC,_delete
 SG_ Mc_VehUntTrpCoUsrSel_St : 23|1@0+ (1,0) [0|1] "SED"  GENERIC,_delete
 SG_ Mc_VehUnitTempUsrSel_St : 22|1@0+ (1,0) [0|1] "SED"  GENERIC,_delete
 SG_ Mc_VehDayNightUsrSel_St : 14|3@0+ (1,0) [0|7] "SED"  GENERIC,_delete
 SG_ Mc_VehTimeFrmtUsrSel_St : 1|2@0+ (1,0) [0|3] "SED"  GENERIC,_delete
 SG_ Mc_VehThemeUsrSel_St : 11|4@0+ (1,0) [0|15] "SED"  GENERIC,_delete
 SG_ Mc_VehLangUsrSel_St : 7|6@0+ (1,0) [0|63] "SED"  GENERIC,TCU
 SG_ AwdRnge_D_ActlIpc : 29|3@0+ (1,0) [0|7] "SED"  GENERIC
 SG_ AwdDrvMde_D_Rq : 44|3@0+ (1,0) [0|7] "SED"  GENERIC,_delete
 SG_ EngExhMdeQuiet_D2_Rq : 55|3@0+ (1,0) [0|7] "SED"  GENERIC,_delete
 SG_ BrkLineLck_D_Rq : 19|2@0+ (1,0) [0|3] "SED"  GENERIC,_delete
 SG_ EdmSailMde_B_RqDrv : 48|1@0+ (1,0) [0|1] "SED"  GENERIC,_delete
 SG_ Running_Board_Cmd : 21|2@0+ (1,0) [0|3] "SED"  GENERIC,_delete

BO_ 739 HMI_Send_Signals_7_FD2: 8 GWM
 SG_ SpeedChngChime_D_Rq : 49|2@0+ (1,0) [0|3] "SED"  GENERIC
 SG_ LostPKChirp_D_RqMnu : 42|2@0+ (1,0) [0|3] "SED"  GENERIC
 SG_ VgfSet_D_Stat : 25|2@0+ (1,0) [0|3] "SED"  GENERIC
 SG_ OnbTrgtSocOvrrd_D_Rq : 14|2@0+ (1,0) [0|3] "SED"  GENERIC
 SG_ OnbTrgtSocOvrrd_Pc_Rq : 63|7@0+ (1,0) [0|127] "percent"  GENERIC
 SG_ BptDly_T_RqMnu : 55|6@0+ (0.5,0) [0|30.5] "minute"  GENERIC
 SG_ BptMnSoc_L_RqMnu : 39|13@0+ (0.1,0) [0|818.9] "kilometer"  GENERIC
 SG_ BptStrtStop_D_RqMnu : 4|2@0+ (1,0) [0|3] "SED"  GENERIC
 SG_ BptMde_D_RqMnu : 7|3@0+ (1,0) [0|7] "SED"  GENERIC
 SG_ VehHornOccAlrt_D_Stat : 27|2@0+ (1,0) [0|3] "SED"  GENERIC
 SG_ SeatOccRear_D_Stat : 29|2@0+ (1,0) [0|3] "SED"  GENERIC
 SG_ BabySeatInUse_D_Stat : 31|2@0+ (1,0) [0|3] "SED"  GENERIC
 SG_ SeatOccChime_B_RqCancl : 16|1@0+ (1,0) [0|1] "SED"  GENERIC
 SG_ EngExhMdeHrStrt_D_Rq : 12|5@0+ (1,0) [0|31] "SED"  GENERIC
 SG_ EngExhMdeHrEnd_D_Rq : 23|5@0+ (1,0) [0|31] "SED"  GENERIC
 SG_ EngExhMdeHrEnbl_D_Rq : 18|2@0+ (1,0) [0|3] "SED"  GENERIC
 SG_ Partial_Amp_Shutdown : 15|1@0+ (1,0) [0|1] "SED"  GENERIC
 SG_ HMI_HMIMode_St : 2|3@0+ (1,0) [0|7] "SED"  GENERIC,TCU

BO_ 553 MFD_Command_FD2: 8 GWM
 SG_ DistToChrgrBynd_L_Actl : 48|9@0+ (1,0) [0|509] "kilometer"  GENERIC
 SG_ CCOI_PolicyClient_St : 11|4@0+ (1,0) [0|15] "SED"  GENERIC
 SG_ ResetAvgFe_B_Rq : 21|1@0+ (1,0) [0|1] "SED"  GENERIC
 SG_ ResetTrip2_B_Rq : 0|1@0+ (1,0) [0|1] "SED"  GENERIC
 SG_ SndImmrsnLvl_D_Rq : 47|8@0+ (1,0) [0|255] "SED"  GENERIC
 SG_ InfoSysMasterPw_D_Stat : 55|3@0+ (1,0) [0|7] "SED"  GENERIC
 SG_ ResetTrip1_B_Rq : 1|1@0+ (1,0) [0|1] "SED"  GENERIC
 SG_ Disp_LangSel2_St : 39|7@0+ (1,0) [0|127] "SED"  GENERIC,TCU
 SG_ Disp_LangSel_St : 20|5@0+ (1,0) [0|31] "SED"  GENERIC,TCU
 SG_ Diagnostic_Operation_Rq : 31|4@0+ (1,0) [0|15] "SED"  GENERIC
 SG_ Bezel_Diag_Module_Rq : 15|4@0+ (1,0) [0|15] "SED"  GENERIC
 SG_ Audio_Demo_CMND : 3|2@0+ (1,0) [0|3] "SED"  GENERIC
 SG_ Audio_Visualizer : 5|2@0+ (1,0) [0|3] "SED"  GENERIC
 SG_ Surround_Sound_Upmix : 7|2@0+ (1,0) [0|3] "SED"  GENERIC
 SG_ Bezel_Diag_State_Rq : 23|2@0+ (1,0) [0|3] "SED"  GENERIC
 SG_ SurndSndUpmix2_D_Rq : 27|3@0+ (1,0) [0|7] "SED"  GENERIC

BO_ 1072 Cluster_Info1_FD2: 8 GWM
 SG_ PtDrvMde_D_Rq : 61|4@0+ (1,0) [0|15] "SED"  GENERIC,_delete
 SG_ DrvSlipCtlMde_D_Rq : 33|2@0+ (1,0) [0|3] "SED"  GENERIC,_delete
 SG_ EngIdlShutDown_B_RqDrv : 3|1@0+ (1,0) [0|1] "SED"  GENERIC,_delete
 SG_ DrvPerfMde_D_Rq : 49|2@0+ (1,0) [0|3] "SED"  GENERIC,_delete
 SG_ HsaMde_D_Rq : 54|2@0+ (1,0) [0|3] "SED"  GENERIC,_delete
 SG_ StopStrtDrvMde_D_RqMnu : 47|2@0+ (1,0) [0|3] "SED"  GENERIC,_delete
 SG_ NtrlTowMdeEnbl_B_RqDrv : 1|1@0+ (1,0) [0|1] "SED"  GENERIC
 SG_ LscmbbStat_B_Actl : 2|1@0+ (1,0) [0|1] "SED"  GENERIC,_delete
 SG_ BulbChkActv_B_Stat : 55|1@0+ (1,0) [0|1] "SED"  GENERIC,_delete
 SG_ ParkDetect_Stat : 52|1@0+ (1,0) [0|1] "SED"  GENERIC
 SG_ ReducedGuard_D_Rq : 51|2@0+ (1,0) [0|3] "SED"  GENERIC,_delete
 SG_ FrostWarn_D_Stat : 45|2@0+ (1,0) [0|3] "SED"  GENERIC,_delete
 SG_ TrlrBrkMde_D_Rq : 57|1@0+ (1,0) [0|1] "SED"  GENERIC,_delete
 SG_ TRLR_SWAY_CONFIG_CMD : 56|1@0+ (1,0) [0|1] "SED"  GENERIC,_delete
 SG_ TRAILER_BRAKE_CONFIG : 37|1@0+ (1,0) [0|1] "SED"  GENERIC,_delete
 SG_ Power_Liftgate_Mode_Cmd : 39|1@0+ (1,0) [0|1] "SED"  GENERIC,_delete
 SG_ AccEnbl_B_RqDrv : 35|1@0+ (1,0) [0|1] "SED"  GENERIC,_delete
 SG_ OdometerMasterValue : 15|24@0+ (1,0) [0|16777214] "km"  GENERIC,RFA_BLEM,TCU
 SG_ EngOilLife_B_RqReset : 43|1@0+ (1,0) [0|1] "SED"  GENERIC,_delete
 SG_ MetricActvTe_B_Actl : 38|1@0+ (1,0) [0|1] "SED"  GENERIC,_delete
 SG_ AccDeny_B_RqIpc : 7|1@0+ (1,0) [0|1] "SED"  GENERIC,_delete
 SG_ ePRNDL_MODE : 0|1@0+ (1,0) [0|1] "SED"  GENERIC,_delete
 SG_ PrkLckCtlEnbl_D_RqIpc : 63|2@0+ (1,0) [0|3] "SED"  GENERIC,_delete
 SG_ HaDsplyCpblty_B_Stat : 42|1@0+ (1,0) [0|1] "SED"  GENERIC,_delete
 SG_ DrvSlipCtlMde_B_Rq2 : 34|1@0+ (1,0) [0|1] "SED"  GENERIC,_delete
 SG_ MetricActv_B_Actl : 6|1@0+ (1,0) [0|1] "SED"  GENERIC
 SG_ KeyTypeChngMykey_D_Rq : 41|2@0+ (1,0) [0|3] "SED"  GENERIC,_delete
 SG_ ManRgen_D_Rq : 5|2@0+ (1,0) [0|3] "SED"  GENERIC,_delete
 SG_ Fda_B_Stat : 36|1@0+ (1,0) [0|1] "SED"  GENERIC,_delete

BO_ 534 WheelData_FD2: 16 GWM
 SG_ BrkObdData_No_Actl : 63|8@0+ (1,0) [0|255] "unitless"  GENERIC,_delete
 SG_ BrkObdIndex_No_Actl : 53|6@0+ (1,0) [0|63] "unitless"  GENERIC,_delete
 SG_ WhlRotatRr_No_Cnt : 23|8@0+ (1,0) [0|255] "unitless"  GENERIC,_delete
 SG_ WhlDirRr_D_Actl : 33|2@0+ (1,0) [0|3] "SED"  GENERIC,_delete
 SG_ WhlDirRl_D_Actl : 39|2@0+ (1,0) [0|3] "SED"  GENERIC,_delete
 SG_ WhlDirFr_D_Actl : 37|2@0+ (1,0) [0|3] "SED"  GENERIC
 SG_ WhlDirFl_D_Actl : 35|2@0+ (1,0) [0|3] "SED"  GENERIC,TCU
 SG_ WhlRotatRl_No_Cnt : 31|8@0+ (1,0) [0|255] "unitless"  GENERIC,_delete
 SG_ WhlRotatFr_No_Cnt : 7|8@0+ (1,0) [0|255] "unitless"  GENERIC,_delete
 SG_ WhlRotatFl_No_Cnt : 15|8@0+ (1,0) [0|255] "unitless"  GENERIC,_delete

BO_ 76 RCMStatusMessage2_FD2: 8 GWM
 SG_ AirbagDrv_D_Actv : 63|2@0+ (1,0) [0|3] "SED"  GENERIC,_delete
 SG_ RCMStatusMsg2_No_Cs : 55|8@0+ (1,0) [0|255] "unitless"  GENERIC,_delete
 SG_ RstrnPsngrOn_D_Stat : 39|4@0+ (1,0) [0|15] "SED"  GENERIC,_delete
 SG_ PsngrFmidDetct_D_Actl : 26|2@0+ (1,0) [0|3] "SED"  GENERIC,TCU
 SG_ FirstRowBuckleMid : 28|2@0+ (1,0) [0|3] "SED"  GENERIC,TCU
 SG_ ThirdRowBucklePsngr : 17|2@0+ (1,0) [0|3] "SED"  GENERIC,TCU,_delete
 SG_ ThirdRowBuckleMid : 19|2@0+ (1,0) [0|3] "SED"  GENERIC,TCU,_delete
 SG_ ThirdRowBuckleDriver : 21|2@0+ (1,0) [0|3] "SED"  GENERIC,TCU,_delete
 SG_ SecondRowBucklePsngr : 23|2@0+ (1,0) [0|3] "SED"  GENERIC,TCU
 SG_ SecondRowBuckleMid : 9|2@0+ (1,0) [0|3] "SED"  GENERIC,TCU
 SG_ SecondRowBuckleDriver : 11|2@0+ (1,0) [0|3] "SED"  GENERIC,TCU
 SG_ FirstRowBuckleDriver : 15|2@0+ (1,0) [0|3] "SED"  GENERIC,TCU
 SG_ RILReq : 7|2@0+ (1,0) [0|3] "SED"  GENERIC,_delete
 SG_ FirstRowBucklePsngr : 13|2@0+ (1,0) [0|3] "SED"  GENERIC,TCU
 SG_ RstrnImpactEvntStatus : 3|3@0+ (1,0) [0|7] "SED"  GENERIC,TCU
 SG_ PsngrFrntDetct_D_Actl : 5|2@0+ (1,0) [0|3] "SED"  GENERIC,_delete,TCU
 SG_ EDRTriggerEvntSync : 29|1@0+ (1,0) [0|1] "SED"  GENERIC,TCU
 SG_ PassRstrnInd_Req : 31|2@0+ (1,0) [0|3] "SED"  GENERIC,_delete
 SG_ FirstRowBuckle_No_Cs : 47|8@0+ (1,0) [0|255] "unitless"  GENERIC,TCU,_delete
 SG_ RCMStatusMsg2_No_Cnt : 35|4@0+ (1,0) [0|15] "unitless"  GENERIC,_delete

BO_ 694 RFA_BLEM_ECG_Word_Tx: 8 RFA_BLEM
 SG_ RFA_BLEM_ECG_Word_Tx : 7|64@0+ (1,0) [0|1.84467440737096E+019] "unitless"  GENERIC,GWM

BO_ 1745 TesterPhysicalReqUCIM: 64 TSTR
 SG_ TesterPhysicalReqUCIM : 7|64@0+ (1,0) [0|1.84467E+019] "unitless"  GENERIC

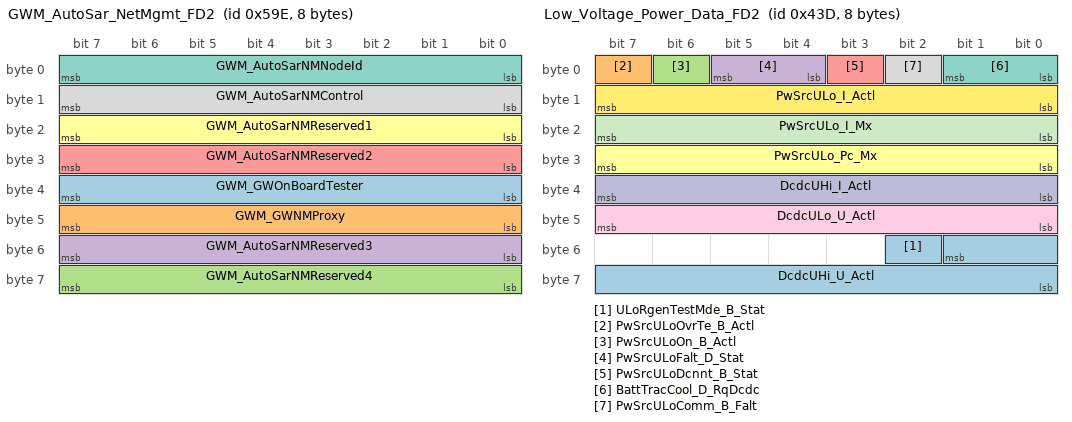
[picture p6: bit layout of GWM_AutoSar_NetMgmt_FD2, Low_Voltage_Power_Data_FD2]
BO_ 1438 GWM_AutoSar_NetMgmt_FD2: 8 GWM
 SG_ GWM_GWOnBoardTester : 39|8@0+ (1,0) [0|255] "unitless"  GENERIC,RFA_BLEM,TCU
 SG_ GWM_GWNMProxy : 47|8@0+ (1,0) [0|255] "unitless"  GENERIC,RFA_BLEM,TCU
 SG_ GWM_AutoSarNMReserved4 : 63|8@0+ (1,0) [0|255] "unitless"  GENERIC,RFA_BLEM,TCU
 SG_ GWM_AutoSarNMReserved3 : 55|8@0+ (1,0) [0|255] "unitless"  GENERIC,RFA_BLEM,TCU
 SG_ GWM_AutoSarNMReserved2 : 31|8@0+ (1,0) [0|255] "unitless"  GENERIC,RFA_BLEM,TCU
 SG_ GWM_AutoSarNMReserved1 : 23|8@0+ (1,0) [0|255] "unitless"  GENERIC,RFA_BLEM,TCU
 SG_ GWM_AutoSarNMNodeId : 7|8@0+ (1,0) [0|255] "unitless"  GENERIC,RFA_BLEM,TCU
 SG_ GWM_AutoSarNMControl : 15|8@0+ (1,0) [0|255] "unitless"  GENERIC,RFA_BLEM,TCU

BO_ 1814 TesterPhysicalReqGWM_FD2: 64 TSTR
 SG_ TesterPhysicalReqGWM_F2 : 7|64@0+ (1,0) [0|1.84467E+019] "unitless"  GENERIC,GWM

BO_ 1822 TesterPhysicalResGWM_FD2: 64 GWM
 SG_ TesterPhysicalResGWM_F2 : 7|64@0+ (1,0) [0|1.84467E+019] "unitless"  GENERIC,TSTR

BO_ 1085 Low_Voltage_Power_Data_FD2: 8 GWM
 SG_ ULoRgenTestMde_B_Stat : 50|1@0+ (1,0) [0|1] "SED"  GENERIC
 SG_ PwSrcULoOvrTe_B_Actl : 7|1@0+ (1,0) [0|1] "SED"  GENERIC
 SG_ PwSrcULoOn_B_Actl : 6|1@0+ (1,0) [0|1] "SED"  GENERIC,_delete
 SG_ PwSrcULoFalt_D_Stat : 5|2@0+ (1,0) [0|3] "SED"  GENERIC,TCU
 SG_ PwSrcULoDcnnt_B_Stat : 3|1@0+ (1,0) [0|1] "SED"  GENERIC
 SG_ PwSrcULo_Pc_Mx : 31|8@0+ (0.4,0) [0|101.6] "%"  GENERIC
 SG_ BattTracCool_D_RqDcdc : 1|2@0+ (1,0) [0|3] "SED"  _delete,GENERIC
 SG_ PwSrcULoComm_B_Falt : 2|1@0+ (1,0) [0|1] "SED"  GENERIC
 SG_ DcdcULo_U_Actl : 47|8@0+ (0.1,0) [0|25.4] "Volts"  GENERIC,_delete
 SG_ DcdcUHi_I_Actl : 39|8@0+ (0.1,0) [0|25.4] "Amps"  GENERIC
 SG_ PwSrcULo_I_Mx : 23|8@0+ (1,0) [0|254] "ampere"  GENERIC
 SG_ PwSrcULo_I_Actl : 15|8@0+ (1,0) [0|254] "ampere"  GENERIC
 SG_ DcdcUHi_U_Actl : 49|10@0+ (0.5,0) [0|510.5] "V"  GENERIC,_delete

BO_ 514 EngVehicleSpThrottle2_FD2: 16 GWM
 SG_ StrtrMtrDlyStrt_B_Stat : 39|1@0+ (1,0) [0|1] "SED"  GENERIC,_delete
 SG_ VehVTrlrAid_B_Avail : 23|1@0+ (1,0) [0|1] "SED"  GENERIC
 SG_ StrtrMtrCtlMsgTxt_D_Rq : 7|3@0+ (1,0) [0|7] "SED"  GENERIC,_delete
 SG_ VehVActlEng_No_Cs : 15|8@0+ (1,0) [0|255] "unitless"  GENERIC,_delete
 SG_ VehVActlEng_No_Cnt : 22|4@0+ (1,0) [0|15] "unitless"  GENERIC,_delete
 SG_ Veh_V_RqCcSet : 32|9@0+ (0.5,0) [0|255.5] "kph"  GENERIC,_delete
 SG_ VehVActlEng_D_Qf : 38|2@0+ (1,0) [0|3] "SED"  GENERIC,TCU
 SG_ Veh_V_ActlEng : 55|16@0+ (0.01,0) [0|655.35] "kph"  GENERIC,RFA_BLEM,TCU
 SG_ EngAout_Tq_VacLimSpcN : 18|11@0+ (1,-500) [-500|1547] "Nm"  GENERIC,_delete
 SG_ EngCylSync_No_Ctr : 36|4@0+ (1,0) [0|15] "unitless"  GENERIC,_delete
 SG_ GearRvrse_D_Actl : 4|3@0+ (1,0) [0|7] "SED"  GENERIC,TCU
 SG_ StrtrMtrCtlMsgTxt_D2_Rq : 1|2@0+ (1,0) [0|3] "SED"  GENERIC,_delete

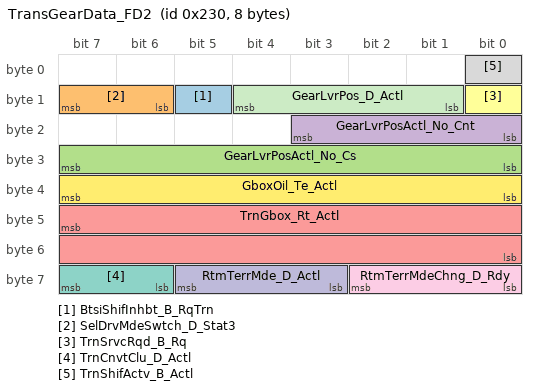
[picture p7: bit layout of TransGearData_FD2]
BO_ 560 TransGearData_FD2: 8 GWM
 SG_ BtsiShifInhbt_B_RqTrn : 13|1@0+ (1,0) [0|1] "SED"  GENERIC
 SG_ SelDrvMdeSwtch_D_Stat3 : 15|2@0+ (1,0) [0|3] "SED"  GENERIC,_delete
 SG_ GearLvrPosActl_No_Cs : 31|8@0+ (1,0) [0|255] "unitless"  GENERIC,_delete
 SG_ GearLvrPosActl_No_Cnt : 19|4@0+ (1,0) [0|15] "unitless"  GENERIC,_delete
 SG_ TrnGbox_Rt_Actl : 47|16@0+ (0.001,0) [0|65.533] "unitless"  GENERIC
 SG_ TrnSrvcRqd_B_Rq : 8|1@0+ (1,0) [0|1] "SED"  GENERIC
 SG_ TrnCnvtClu_D_Actl : 63|2@0+ (1,0) [0|3] "SED"  GENERIC
 SG_ TrnShifActv_B_Actl : 0|1@0+ (1,0) [0|1] "SED"  GENERIC
 SG_ RtmTerrMdeChng_D_Rdy : 58|3@0+ (1,0) [0|7] "SED"  GENERIC,_delete
 SG_ RtmTerrMde_D_Actl : 61|3@0+ (1,0) [0|7] "SED"  GENERIC,_delete
 SG_ GearLvrPos_D_Actl : 12|4@0+ (1,0) [0|15] "SED"  GENERIC,TCU,RFA_BLEM
 SG_ GboxOil_Te_Actl : 39|8@0+ (1,-60) [-60|193] "degC"  GENERIC

BO_ 817 Locking_Systems_2_FD2: 16 GWM
 SG_ ChildLckMde_B_Stat : 56|1@0+ (1,0) [0|1] "SED"  GENERIC,_delete
 SG_ VehLckInd_D_Rq : 58|2@0+ (1,0) [0|3] "SED"  GENERIC,_delete
 SG_ DrTgateOpen_B_Rq : 59|1@0+ (1,0) [0|1] "SED"  GENERIC,_delete
 SG_ DrTgateExtSwMde_B_Stat : 32|1@0+ (1,0) [0|1] "SED"  GENERIC,_delete
 SG_ Remote_Device_Feedback : 50|3@0+ (1,0) [0|7] "SED"  GENERIC,_delete
 SG_ Veh_Lock_Requestor : 55|5@0+ (1,0) [0|31] "SED"  GENERIC,TCU,_delete,RFA_BLEM
 SG_ R_Pwr_Sliding_Dr_Rqst : 36|1@0+ (1,0) [0|1] "SED"  GENERIC,_delete
 SG_ Power_Liftgate_Rqst : 0|1@0+ (1,0) [0|1] "SED"  GENERIC,_delete
 SG_ Veh_Lock_EvNum : 47|8@0+ (1,0) [0|255] "unitless"  GENERIC,_delete,RFA_BLEM
 SG_ Power_Decklid_Rqst : 1|1@0+ (1,0) [0|1] "SED"  GENERIC,_delete
 SG_ L_Pwr_Sliding_Dr_Rqst : 3|1@0+ (1,0) [0|1] "SED"  GENERIC,_delete
 SG_ Keyfob_Pad_Msg_Count : 15|8@0+ (1,0) [0|255] "Counts"  GENERIC,_delete
 SG_ Veh_Lock_Sub_Id : 63|4@0+ (1,0) [0|15] "SED"  GENERIC,_delete
 SG_ Veh_Lock_Status : 34|2@0+ (1,0) [0|3] "SED"  GENERIC,TCU,_delete,RFA_BLEM
 SG_ WindowLockout_B_Stat : 35|1@0+ (1,0) [0|1] "SED"  GENERIC,_delete
 SG_ RollCodeUnlock : 23|16@0+ (1,0) [0|65535] "unitless"  GENERIC,_delete
 SG_ Lockmsgtxt_D_Rq : 39|3@0+ (1,0) [0|7] "SED"  GENERIC,_delete
 SG_ FobComm_D_Stat : 5|2@0+ (1,0) [0|3] "SED"  GENERIC,_delete
 SG_ LockInhibit : 2|1@0+ (1,0) [0|1] "SED"  GENERIC,_delete

BO_ 1084 Battery_Mgmt_3_FD2: 16 GWM
 SG_ BattULoChrg_URate_RqMx : 63|6@0+ (0.1,0) [0|6.3] "volts/second"  GENERIC,_delete
 SG_ BattULoChrg_U_RqMx : 55|6@0+ (0.1,10.6) [10.6|16.9] "volt"  GENERIC,_delete
 SG_ BattULoChrg_U_RqMn : 45|6@0+ (0.1,10.6) [10.6|16.9] "volt"  GENERIC,_delete
 SG_ BattULoState_D_Qlty : 47|2@0+ (1,0) [0|3] "SED"  GENERIC,_delete
 SG_ BSFault : 7|1@0+ (1,0) [0|1] "SED"  GENERIC,_delete
 SG_ BattULo2_Te_Actl : 30|7@0+ (1,-40) [-40|86] "degC"  GENERIC
 SG_ BSBattSOC : 22|7@0+ (1,0) [0|127] "%"  GENERIC,_delete,RFA_BLEM
 SG_ BSBattQDeltaRideAh : 6|15@0+ (0.0078125,-100) [-100|155.9921875] "ampere*hour"  GENERIC,_delete
 SG_ BSBattQCapAh : 38|7@0+ (1,0) [0|127] "ampere*hour"  GENERIC,_delete

BO_ 1068 Battery_Mgmt_2_FD2: 16 GWM
 SG_ EngStrtInhbt_B_RqBatt : 2|1@0+ (1,0) [0|1] "SED"  GENERIC,_delete
 SG_ BattULoChrg_D_Rq : 7|2@0+ (1,0) [0|3] "SED"  GENERIC,_delete
 SG_ PwSysULoFalt_D_Stat : 12|4@0+ (1,0) [0|15] "SED"  GENERIC,_delete
 SG_ Shed_T_Eng_Off_B : 8|1@0+ (1,0) [0|1] "SED"  GENERIC,_delete
 SG_ Shed_Feature_Group_ID : 20|5@0+ (1,0) [0|31] "SED"  GENERIC,_delete
 SG_ Shed_Drain_Eng_Off_B : 0|1@0+ (1,0) [0|1] "SED"  GENERIC,_delete
 SG_ Shed_Level_Req : 23|3@0+ (1,0) [0|7] "SED"  GENERIC,_delete
 SG_ BattULoSrvc_T_Actl : 39|12@0+ (1,0) [0|4095] "day"  GENERIC,_delete
 SG_ ULoRgenTestMde_B_Rq : 31|1@0+ (1,0) [0|1] "SED"  GENERIC,_delete
 SG_ ChargeMode : 15|3@0+ (1,0) [0|7] "SED"  GENERIC,_delete
 SG_ IdleSpeedIncrease_El : 3|1@0+ (1,0) [0|1] "SED"  GENERIC,_delete
 SG_ Batt_Lo_SoC_B : 5|1@0+ (1,0) [0|1] "SED"  GENERIC,_delete,RFA_BLEM
 SG_ PeriodicElLoad_B_Stat : 1|1@0+ (1,0) [0|1] "SED"  GENERIC,_delete
 SG_ Batt_Crit_SoC_B : 4|1@0+ (1,0) [0|1] "SED"  GENERIC,_delete

BO_ 1144 MHT_EV_Wakeup_FD2: 16 GWM
 SG_ AwdLckMde_D_Stat : 59|3@0+ (1,0) [0|7] "SED"  GENERIC,_delete
 SG_ BattTracCool_B_Actl : 60|1@0+ (1,0) [0|1] "SED"  GENERIC,_delete
 SG_ BattChrgInhbt_D2_Rq : 63|3@0+ (1,0) [0|7] "SED"  GENERIC,_delete
 SG_ BattChrgTrgtSoC_D_Rq : 35|3@0+ (1,0) [0|7] "Percent"  GENERIC,_delete
 SG_ CabnEvapSovFront_B_Rq : 38|1@0+ (1,0) [0|1] "SED"  GENERIC,_delete
 SG_ HeatCoreSovRear_B_Rq : 36|1@0+ (1,0) [0|1] "SED"  GENERIC,_delete
 SG_ BattChlrSov_B_Rq : 39|1@0+ (1,0) [0|1] "SED"  GENERIC,_delete
 SG_ CabnEvapSovRear_B_Rq : 37|1@0+ (1,0) [0|1] "SED"  GENERIC,_delete
 SG_ BrkAppl_D_RqPt : 25|2@0+ (1,0) [0|3] "SED"  GENERIC,_delete
 SG_ BattClntVlvOvrrd_D_Rq : 31|2@0+ (1,0) [0|3] "SED"  GENERIC,_delete
 SG_ BattTracChillerOn_B_Rq : 27|1@0+ (1,0) [0|1] "SED"  GENERIC,_delete
 SG_ BattTracChiller_D_Stat : 29|2@0+ (1,0) [0|3] "SED"  GENERIC,_delete
 SG_ HtrnDcdcDis_B_Rq : 26|1@0+ (1,0) [0|1] "SED"  GENERIC,_delete
 SG_ HtrnCnnctPwr_B_Stat : 16|1@0+ (1,0) [0|1] "SED"  GENERIC,_delete
 SG_ PtcHtr_D_Stat : 18|2@0+ (1,0) [0|3] "SED"  GENERIC,_delete
 SG_ WakeAlarm0_B_Typ : 21|1@0+ (1,0) [0|1] "SED"  GENERIC,_delete
 SG_ WakeAlarm0_T_Rq : 7|15@0+ (1,0) [0|32767] "minute"  GENERIC,_delete
 SG_ HtrnClntFlw_D_Rq : 20|2@0+ (1,0) [0|3] "SED"  GENERIC,_delete
 SG_ BattTracDrvSustn_B_Rq : 8|1@0+ (1,0) [0|1] "SED"  GENERIC,_delete
 SG_ CabinDrvSustn_B_Rq : 23|1@0+ (1,0) [0|1] "SED"  GENERIC,_delete
 SG_ ChrgNowEvnt_B_Stat : 22|1@0+ (1,0) [0|1] "SED"  GENERIC,_delete
 SG_ PreCondBatt_B_Actl : 32|1@0+ (1,0) [0|1] "SED"  GENERIC,_delete
 SG_ BattTracClntVlv_B_Rq : 47|1@0+ (1,0) [0|1] "SED"  GENERIC,_delete
 SG_ ULoBattTrnsfrSustn_B_Rq : 43|1@0+ (1,0) [0|1] "SED"  GENERIC,_delete
 SG_ ULoBattTransfer_D_Stat : 46|3@0+ (1,0) [0|7] "SED"  GENERIC,_delete
 SG_ BattTracClimtDis_B_Stat : 42|1@0+ (1,0) [0|1] "SED"  GENERIC,_delete
 SG_ FstChrgCmplt_T_Est : 41|10@0+ (1,0) [0|1023] "minute"  GENERIC,TCU,_delete

BO_ 2015 TesterFunctionalReq_FD2: 64 TSTR
 SG_ TesterFunctionalReq : 7|64@0+ (1,0) [0|1.84467E+019] "unitless"  GENERIC,RFA_BLEM,TCU,GWM

BO_ 1034 GGCC_Config_Mgmt_ID_1_FD2: 16 GWM
 SG_ VehicleGGCCData : 7|64@0+ (1,0) [0|1.84467E+019] "mixed"  GENERIC,RFA_BLEM,TCU

BO_ 1200 ABS_BrkBst_Data_FD2: 16 GWM
 SG_ BrkRearPCorrltn_B_Stat : 35|1@0+ (1,0) [0|1] "SED"  GENERIC,_delete
 SG_ HsaTrnAout_Tq_Rq : 23|16@0+ (4,-131072) [-131072|131060] "Nm"  GENERIC,_delete
 SG_ BrkBstrVac_P_Actl : 7|7@0+ (8,0) [0|1008] "millibar"  GENERIC,_delete
 SG_ YawStabilityIndex : 0|9@0+ (1,-256) [-256|255] "%"  GENERIC,_delete
 SG_ BrkTot_Tq_RqDrv : 47|13@0+ (4,0) [0|32760] "Nm"  GENERIC,_delete,TCU,RFA_BLEM
 SG_ BrkTotTqRqDrv_No_Cnt : 39|4@0+ (1,0) [0|15] "unitless"  GENERIC,_delete,RFA_BLEM
 SG_ BrkTotTqRqDrv_No_Cs : 63|8@0+ (1,0) [0|255] "unitless"  GENERIC,_delete,RFA_BLEM
 SG_ HsaStat_D_Dsply : 50|3@0+ (1,0) [0|7] "SED"  GENERIC,_delete
 SG_ BrkHold_D_Stat : 34|3@0+ (1,0) [0|7] "SED"  GENERIC,_delete,RFA_BLEM

CM_ SG_ 931 CrnkInhbt_No_Cs "Signal not transmitted on gas and HEV variants.";
CM_ SG_ 931 CrnkInhbt_No_Cnt "Signal not transmitted on gas and HEV variants.";
CM_ BO_ 130 "drecker 10/23/09 Need SAPP in sync w/Strg Torque for proper PAM interpretation, else fault msg's displayed FP@20ms IPC needs EPAS_Failure for msg to driver.  Not map w/Lane Assist FP@30s FP), save bandwidth if feature not on vehicle ";
CM_ SG_ 130 VehVTrlrAid_B_Rq "VR session start- req. limit blower speed no more than X volts.  CC restriction on time msg. will be honored.Double Event msg1st event to request limit, 2nd event to release limit, No msg. CC Grammar v7.xls";
CM_ SG_ 130 SteMdule_U_Meas "DCR 1745  to update Tx from GWM to EP100ms. SteMdule_I_Est & SteMdule_U_Meas are used by BMS system & filtered. The filter uses standard periodic rate & changing to EP would adversely affect the filter.(jweinfur)";
CM_ SG_ 130 SteMdule_I_Est "DCR 1745  to update Tx from GWM to EP100ms. SteMdule_I_Est & SteMdule_U_Meas are used by BMS system & filtered. The filter uses standard periodic rate & changing to EP would adversely affect the filter.(jweinfur)";
CM_ SG_ 1046 TCMode "Signal data set to 0x0 for ABS only vehicle option content";
CM_ SG_ 1046 DrvAntiLckLamp_D_Rq "update value table v8.34, not align w/GSDB, need etracker.  ABS & IPC implemented as updated.";
CM_ SG_ 1046 BpedMove_D_Actl "CCMGenSigTimeoutTime=1000";
CM_ BO_ 531 "When PBM is present use 0x41B for PrkMsgTxt_D_Rq, PrkBrkRedLamp_D_Rq, PrkBrkYwLamp_D_Rq source signals otherwise ABS will source from 0x213.";
CM_ SG_ 531 VehLongOvrGnd_A_Est "CCMGenSigTimeoutTime=1000";
CM_ BO_ 1184 "TP message";
CM_ BO_ 74 "Reserve eCallNotification message";
CM_ BO_ 382 "ECM, PCM Gas Only msg";
CM_ SG_ 516 EngAout3_N_Actl "Signal not transmitted on gas and diesel variants.";
CM_ SG_ 516 ApedPos_Pc_ActlArb "ABSGenSigTimeoutTime=1000";
CM_ SG_ 516 ApedPosPcActl_No_Cnt "Signal not transmitted on gas and diesel variants.";
CM_ SG_ 516 ApedPosPcActl_No_Cs "Signal not transmitted on gas and diesel variants.";
CM_ SG_ 1091 PoliceAux4Lamp_B_Rq2 "Signal not transmitted on programs that do not have AWD.";
CM_ SG_ 1091 PoliceAux3Lamp_B_Rq2 "Signal not transmitted on programs that do not have AWD.";
CM_ SG_ 1091 PoliceAux2Lamp_B_Rq2 "Signal not transmitted on programs that do not have AWD.";
CM_ SG_ 1091 PoliceAux1Lamp_B_Rq2 "Signal not transmitted on programs that do not have AWD.";
CM_ SG_ 359 TrnAin_Tq_Actl "Signal not transmitted on HEV variances.";
CM_ SG_ 359 PlgActvArb_B_Actl "Only supported on PHEV programs.  PlgActvArb_B_Actl HPCM will Tx on Powersplit PHEV’s,  On MHT PHEVs the PCM_HEV will Tx and HPCM will Rx. 
";
CM_ SG_ 359 TrnAinTq_D_Qf "Signal not transmitted on HEV variances.";
CM_ BO_ 374 "Programs w/o HS1 0x172 will need HS1 0x176 for GearPos_D_Actl.  Future MY Programs that choose c/o still require HS1 0x172. ";
CM_ SG_ 374 TrnRng_D_Rq "Powersplit HEVs with HF45, HPCM will Tx  this message.  For all other programs it will be Tx by PCM or TCM. ";
CM_ SG_ 374 TrnPrkSys_D_Actl "Powersplit HEVs with HF45, HPCM will Tx  this message.  For all other programs it will be Tx by PCM or TCM. ";
CM_ SG_ 374 GearLvr_D_ActlDrv "Powersplit HEVs with HF45, HPCM will Tx  this message.  For all other programs it will be Tx by PCM or TCM. ";
CM_ SG_ 374 GearPos_No_Cs "Powersplit HEVs with HF45, HPCM will Tx  this message.  For all other programs it will be Tx by PCM or TCM. ";
CM_ SG_ 374 GearPos_D_Trg "Powersplit HEVs with HF45, HPCM will Tx  this message.  For all other programs it will be Tx by PCM or TCM. ";
CM_ SG_ 374 GearPos_No_Cnt "Powersplit HEVs with HF45, HPCM will Tx  this message.  For all other programs it will be Tx by PCM or TCM. ";
CM_ SG_ 374 GearPos_D_Actl "Powersplit HEVs with HF45, HPCM will Tx  this message.  For all other programs it will be Tx by PCM or TCM. ";
CM_ SG_ 702 ECG_RFA_BLEM_Word_Tx "Tx by HS3 APIM";
CM_ SG_ 479 DISP_SetVol_Source_Rq "Object.VolumeControl.MFD_SetVol_Source.Rq

SetVol_Source.Rq";
CM_ SG_ 479 DISP_SetVol_Level_Rq "Object.VolumeControl.MFD_SetVol_Level.Rq 

0x0 Inactive/NoChange
0x1 No Volume
0x2 Vol_Step1
0x3 Vol_Step2
0x4 Vol_Step3
Cont.
0x1F Vol_Step30

Object.VolumeControl.SetPointVolume

Object.VolumeControl.SetVol_Level.Rq";
CM_ SG_ 479 DISP_Setshaker_Rq "Object.AudioSettings.SetShaker.Rq
";
CM_ SG_ 765 Mc_VehUntTrpCoUsrSel_St "Object.VehicleSettings.Disp_Miles_Kilometers.Rq";
CM_ SG_ 765 Mc_VehUnitTempUsrSel_St "Object.VehicleSettings.Disp_Temperature.Rq";
CM_ SG_ 765 Mc_VehDayNightUsrSel_St "Object.BodyInterface.Settings.VehicleDayNightUserSelection
Object.BodyInterface.Status.AMDayNightSensitivity";
CM_ SG_ 765 Mc_VehTimeFrmtUsrSel_St "Object.BodyInterface.Settings.VehicleTimeFormatUserSelection";
CM_ SG_ 765 Mc_VehThemeUsrSel_St "Object.BodyInterface.Settings.VehicleThemeUserSelection";
CM_ SG_ 765 Mc_VehLangUsrSel_St "Object.BodyInterface.Settings.VehicleLanguageUserSelection
Object Vehicle Settings.Disp_LangSel
";
CM_ BO_ 739 "FCDIM Tx";
CM_ SG_ 739 Partial_Amp_Shutdown "Method Partial_Amp_Shutdown";
CM_ SG_ 739 HMI_HMIMode_St "Object ACU System Master.HMIMode
OR
Object NAV System Master.HMIMode

Refer Method HMIAudioMode in the SPSS";
CM_ BO_ 553 "FCDIM, APIM Tx";
CM_ SG_ 553 SndImmrsnLvl_D_Rq "ImmersionLevel_D_Rq";
CM_ SG_ 553 Disp_LangSel2_St "Reference GSDB for encoding: 009522/B;2-ZZ_LangSel";
CM_ SG_ 553 Disp_LangSel_St "Object.VehicleSettings.Disp_LangSel.St.Language";
CM_ SG_ 553 Diagnostic_Operation_Rq "Object:BezelDiagnostics.MFD_Bezel_Diagnostic.St";
CM_ SG_ 553 Bezel_Diag_Module_Rq "Object:BezelDiagnostics.MFD_Bezel_Diagnostic.St";
CM_ SG_ 553 Audio_Demo_CMND "Object. AudioSettings.Audio Demo_CMND";
CM_ SG_ 553 Audio_Visualizer "Object.AudioSettings.Audio_Visualizer
";
CM_ SG_ 553 Surround_Sound_Upmix "Object.AudioSettings.Surround_Sound_Upmix

";
CM_ SG_ 553 Bezel_Diag_State_Rq "Object:BezelDiagnostics.MFD_Bezel_Diagnostic.Rq";
CM_ SG_ 553 SurndSndUpmix2_D_Rq "Object:Surround_Sound_Upmix2_Rq";
CM_ SG_ 1072 MetricActv_B_Actl "0 =Inactive(English), 1=Active(Metric)";
CM_ SG_ 534 BrkObdData_No_Actl "Signal not transmitted on gas, diesel and HEV.  Only supported on PHEV.";
CM_ SG_ 534 BrkObdIndex_No_Actl "Signal not transmitted on gas, diesel and HEV.  Only supported on PHEV.";
CM_ SG_ 534 WhlRotatRr_No_Cnt "DCR 1833 to update Tx from GWM to EP100ms. Wheel Count signals are used by complex algorithm to determine Tire Pressure by Location & can't change from 20msec. (jweinfur)";
CM_ SG_ 534 WhlRotatRl_No_Cnt "DCR 1833 to update Tx from GWM to EP100ms. Wheel Count signals are used by complex algorithm to determine Tire Pressure by Location & can't change from 20msec. (jweinfur)";
CM_ SG_ 534 WhlRotatFr_No_Cnt "DCR 1833 to update Tx from GWM to EP100ms. Wheel Count signals are used by complex algorithm to determine Tire Pressure by Location & can't change from 20msec. (jweinfur)";
CM_ SG_ 534 WhlRotatFl_No_Cnt "DCR 1833 to update Tx from GWM to EP100ms. Wheel Count signals are used by complex algorithm to determine Tire Pressure by Location & can't change from 20msec. (jweinfur)";
CM_ SG_ 1085 ULoRgenTestMde_B_Stat "Signal not transmitted on HEV variants.";
CM_ SG_ 1085 BattTracCool_D_RqDcdc "Signal not transmitted on gas and diesel variants.";
CM_ SG_ 1085 PwSrcULoComm_B_Falt "Signal not transmitted on HEV variants.";
CM_ SG_ 1085 DcdcULo_U_Actl "Signal not transmitted on gas and diesel variants.";
CM_ SG_ 1085 DcdcUHi_I_Actl "Signal not transmitted on gas and diesel variants.";
CM_ SG_ 1085 DcdcUHi_U_Actl "Signal not transmitted on gas and diesel variants.";
CM_ SG_ 514 EngAout_Tq_VacLimSpcN "Signal not transmitted on gas and diesel variances.";
CM_ SG_ 514 EngCylSync_No_Ctr "Signal not transmitted on gas and diesel variances.";
CM_ SG_ 514 GearRvrse_D_Actl "Do not implement GearRvrse_D_Actl  until eTracker 8804151 is approved, 11/24/09";
CM_ BO_ 560 "MHT (U611/625) the HPCM will Rx 0x230 from the PCM_HEV
Powersplit FWD HEV’s (Cx482/3 430) the HPCM will Tx 0x230";
CM_ SG_ 560 SelDrvMdeSwtch_D_Stat3 "ECM_HEV does not support or Transmit signal.";
CM_ SG_ 560 GearLvrPosActl_No_Cs "Signal not transmitted on Gas & HEV variants. MHT(U611/625) HPCM Rx 0x230 from PCM_HEV. Powersplit FWD HEV’s(Cx482/3 430) HPCM Tx 0x230.";
CM_ SG_ 560 GearLvrPosActl_No_Cnt "Signal not transmitted on Gas & HEV variants. MHT(U611/625) HPCM Rx 0x230 from PCM_HEV. Powersplit FWD HEV’s(Cx482/3 430) HPCM Tx 0x230.";
CM_ SG_ 560 TrnGbox_Rt_Actl "Signal not transmitted on Gas & HEV variants. MHT(U611/625) HPCM Rx 0x230 from PCM_HEV. Powersplit FWD HEV’s(Cx482/3 430) HPCM Tx 0x230.";
CM_ SG_ 560 TrnSrvcRqd_B_Rq "Signal not transmitted on Diesel & HEV variants. MHT(U611/625) HPCM Rx 0x230 from PCM_HEV. Powersplit FWD HEV’s(Cx482/3 430) HPCM Tx 0x230.";
CM_ SG_ 560 TrnCnvtClu_D_Actl "Signal not transmitted on Gas & HEV variants. MHT(U611/625) HPCM Rx 0x230 from PCM_HEV. Powersplit FWD HEV’s(Cx482/3 430) HPCM Tx 0x230.";
CM_ SG_ 560 TrnShifActv_B_Actl "Signal not transmitted on HEV variants. MHT(U611/625) HPCM Rx 0x230 from PCM_HEV. Powersplit FWD HEV’s(Cx482/3 430) HPCM Tx 0x230.";
CM_ SG_ 560 GboxOil_Te_Actl "Signal not transmitted on HEV variants. MHT(U611/625) HPCM Rx 0x230 from PCM_HEV. Powersplit FWD HEV’s(Cx482/3 430) HPCM Tx 0x230.";
CM_ BO_ 2015 "OBDII Request ($7DF) messages are for FNOS 1.0.1 only.
Diagnostic Functional Addressing ($7DF) and Dual Rate Periodic messages are for FNOS I3 only.";
CM_ SG_ 1034 VehicleGGCCData "RCMGenSigTimeout=6000";
CM_ SG_ 1200 BrkTot_Tq_RqDrv "DCR 1836 to update Tx from GWM to EP100ms rejected due MPS6 TCM requires BrkTot_Tq_RqDrv at 20ms (bshu1).";
BA_DEF_ BO_  "VFrameFormat" ENUM  "StandardCAN","ExtendedCAN","reserved","reserved","reserved","reserved","reserved","reserved","reserved","reserved","reserved","reserved","reserved","reserved","StandardCAN_FD","ExtendedCAN_FD";
BA_DEF_ BO_  "FrameRouting" STRING ;
BA_DEF_ BO_  "NetworkInitialization" ENUM  "No","Yes";
BA_DEF_ BO_  "GenMsgStartDelayTime" INT 0 10000;
BA_DEF_ BO_  "GenMsgNrOfRepetition" INT 0 100;
BA_DEF_ BO_  "GenMsgDelayTime" INT 0 1000;
BA_DEF_ BO_  "GenMsgCycleTime" INT 0 100000;
BA_DEF_ BO_  "GenMsgSendType" ENUM  "FixedPeriodic","Event","EnabledPeriodic","NotUsed","NotUsed","EventPeriodic","NotUsed","NotUsed","NoMsgSendType";
BA_DEF_ SG_  "U_P702_MY2024_Tx" ENUM  "No","Yes";
BA_DEF_ SG_  "U_V710_MY2023_Tx" ENUM  "No","Yes";
BA_DEF_ SG_  "U_CDX74X_MY2024_Tx" ENUM  "No","Yes";
BA_DEF_ SG_  "U_CDX707_MY2023_Tx" ENUM  "No","Yes";
BA_DEF_ SG_  "U_P708_MY2023_Tx" ENUM  "No","Yes";
BA_DEF_ SG_  "U_V713AV_MY2022_Tx" ENUM  "No","Yes";
BA_DEF_ SG_  "U_V713N_MY2022_Tx" ENUM  "No","Yes";
BA_DEF_ SG_  "ECGUsedTxSignal" ENUM  "No","Yes";
BA_DEF_ SG_  "U_P702_MY2024_Rx" ENUM  "No","Yes";
BA_DEF_ SG_  "U_V710_MY2023_Rx" ENUM  "No","Yes";
BA_DEF_ SG_  "U_CDX74X_MY2024_Rx" ENUM  "No","Yes";
BA_DEF_ SG_  "U_CDX707_MY2023_Rx" ENUM  "No","Yes";
BA_DEF_ SG_  "U_P708_MY2023_Rx" ENUM  "No","Yes";
BA_DEF_ SG_  "U_V713AV_MY2022_Rx" ENUM  "No","Yes";
BA_DEF_ SG_  "U_V713N_MY2022_Rx" ENUM  "No","Yes";
BA_DEF_ SG_  "ECGUsedRxSignal" ENUM  "No","Yes";
BA_DEF_ SG_  "UsedOnPgmDBC" ENUM  "No","Yes";
BA_DEF_ SG_  "ContentDependant" ENUM  "No","Yes";
BA_DEF_ SG_  "GenSigStartValue" HEX 0 268435455;
BA_DEF_ SG_  "MetaData" ENUM  "No","Yes";
BA_DEF_ SG_  "WakeupSignal" ENUM  "No","Yes";
BA_DEF_ SG_  "GenSigInactiveValue" INT 0 100000;
BA_DEF_ SG_  "GenSigSendType" ENUM  "Cyclic","OnWrite","vector_leerstring","OnChange","vector_leerstring","IfActive","vector_leerstring","NoSigSendType";
BA_DEF_ BO_  "TpTxIndex" INT 0 536870911;
BA_DEF_ BO_  "OvtpPushApplication" ENUM  "FALSE","TRUE";
BA_DEF_ BO_  "SCP_FreshnessValueLength" INT 0 512;
BA_DEF_ BO_  "SCP_DataId" INT 0 17663;
BA_DEF_ BO_  "SCP_FreshnessValueTxLength" INT 0 512;
BA_DEF_ BO_  "SCP_AuthInfoTxLength" INT 0 512;
BA_DEF_ BO_  "SC_Message" ENUM  "No","Yes";
BA_DEF_ BO_  "GenMsgRoutingTimeoutTime" INT 0 5000;
BA_DEF_ BO_  "NmAsrMessage" ENUM  "No","Yes";
BA_DEF_ BO_  "DiagState" ENUM  "No","Yes";
BA_DEF_ BO_  "DiagRequest" ENUM  "No","Yes";
BA_DEF_ BO_  "DiagResponse" ENUM  "No","Yes";
BA_DEF_ BO_  "GenMsgILSupport" ENUM  "No","Yes";
BA_DEF_REL_ BU_SG_REL_  "SC_Verification" ENUM  "No","Yes";
BA_DEF_DEF_  "VFrameFormat" "ExtendedCAN_FD";
BA_DEF_DEF_  "FrameRouting" "";
BA_DEF_DEF_  "NetworkInitialization" "Yes";
BA_DEF_DEF_  "GenMsgStartDelayTime" 0;
BA_DEF_DEF_  "GenMsgNrOfRepetition" 1;
BA_DEF_DEF_  "GenMsgDelayTime" 20;
BA_DEF_DEF_  "GenMsgCycleTime" 0;
BA_DEF_DEF_  "GenMsgSendType" "NoMsgSendType";
BA_DEF_DEF_  "U_P702_MY2024_Tx" "No";
BA_DEF_DEF_  "U_V710_MY2023_Tx" "No";
BA_DEF_DEF_  "U_CDX74X_MY2024_Tx" "No";
BA_DEF_DEF_  "U_CDX707_MY2023_Tx" "No";
BA_DEF_DEF_  "U_P708_MY2023_Tx" "No";
BA_DEF_DEF_  "U_V713AV_MY2022_Tx" "No";
BA_DEF_DEF_  "U_V713N_MY2022_Tx" "No";
BA_DEF_DEF_  "ECGUsedTxSignal" "No";
BA_DEF_DEF_  "U_P702_MY2024_Rx" "No";
BA_DEF_DEF_  "U_V710_MY2023_Rx" "No";
BA_DEF_DEF_  "U_CDX74X_MY2024_Rx" "No";
BA_DEF_DEF_  "U_CDX707_MY2023_Rx" "No";
BA_DEF_DEF_  "U_P708_MY2023_Rx" "No";
BA_DEF_DEF_  "U_V713AV_MY2022_Rx" "No";
BA_DEF_DEF_  "U_V713N_MY2022_Rx" "No";
BA_DEF_DEF_  "ECGUsedRxSignal" "No";
BA_DEF_DEF_  "UsedOnPgmDBC" "Yes";
BA_DEF_DEF_  "ContentDependant" "No";
BA_DEF_DEF_  "GenSigStartValue" 0;
BA_DEF_DEF_  "MetaData" "No";
BA_DEF_DEF_  "WakeupSignal" "No";
BA_DEF_DEF_  "GenSigInactiveValue" 0;
BA_DEF_DEF_  "GenSigSendType" "NoSigSendType";
BA_DEF_DEF_  "TpTxIndex" 0;
BA_DEF_DEF_  "OvtpPushApplication" "FALSE";
BA_DEF_DEF_  "SCP_FreshnessValueLength" 64;
BA_DEF_DEF_  "SCP_DataId" 0;
BA_DEF_DEF_  "SCP_FreshnessValueTxLength" 11;
BA_DEF_DEF_  "SCP_AuthInfoTxLength" 53;
BA_DEF_DEF_  "SC_Message" "No";
BA_DEF_DEF_  "GenMsgRoutingTimeoutTime" 0;
BA_DEF_DEF_  "NmAsrMessage" "No";
BA_DEF_DEF_  "DiagState" "No";
BA_DEF_DEF_  "DiagRequest" "No";
BA_DEF_DEF_  "DiagResponse" "No";
BA_DEF_DEF_  "GenMsgILSupport" "Yes";
BA_DEF_DEF_REL_ "SC_Verification" "No";
BA_ "FrameRouting" BO_ 1054 "FD1_CAN,0x41E;";
BA_ "VFrameFormat" BO_ 1054 14;
BA_ "SC_Message" BO_ 931 1;
BA_ "SCP_DataId" BO_ 931 5027;
BA_ "FrameRouting" BO_ 931 "FD1_CAN,0x3A3;";
BA_ "VFrameFormat" BO_ 931 14;
BA_ "SC_Message" BO_ 130 1;
BA_ "SCP_DataId" BO_ 130 4226;
BA_ "FrameRouting" BO_ 130 "FD3_CAN,0x82";
BA_ "VFrameFormat" BO_ 130 14;
BA_ "SC_Message" BO_ 1046 1;
BA_ "SCP_DataId" BO_ 1046 5142;
BA_ "FrameRouting" BO_ 1046 "FD1_CAN,0x416;";
BA_ "VFrameFormat" BO_ 1046 14;
BA_ "FrameRouting" BO_ 1234 "FD3_CAN,0x4D2";
BA_ "VFrameFormat" BO_ 1234 14;
BA_ "FrameRouting" BO_ 1233 "FD3_CAN,0x4D1";
BA_ "VFrameFormat" BO_ 1233 14;
BA_ "SC_Message" BO_ 125 1;
BA_ "SCP_DataId" BO_ 125 4221;
BA_ "FrameRouting" BO_ 125 "FD1_CAN,0x7D;";
BA_ "VFrameFormat" BO_ 125 14;
BA_ "SC_Message" BO_ 531 1;
BA_ "SCP_DataId" BO_ 531 4627;
BA_ "FrameRouting" BO_ 531 "FD1_CAN,0x213;";
BA_ "VFrameFormat" BO_ 531 14;
BA_ "GenMsgILSupport" BO_ 1841 0;
BA_ "DiagRequest" BO_ 1841 1;
BA_ "GenMsgSendType" BO_ 1841 1;
BA_ "GenMsgDelayTime" BO_ 1841 0;
BA_ "NetworkInitialization" BO_ 1841 0;
BA_ "VFrameFormat" BO_ 1841 14;
BA_ "GenMsgSendType" BO_ 638 5;
BA_ "GenMsgCycleTime" BO_ 638 1000;
BA_ "VFrameFormat" BO_ 638 14;
BA_ "TpTxIndex" BO_ 1184 20;
BA_ "VFrameFormat" BO_ 1184 14;
BA_ "SC_Message" BO_ 894 1;
BA_ "SCP_DataId" BO_ 894 9086;
BA_ "FrameRouting" BO_ 894 "FD1_CAN,0x37E;";
BA_ "VFrameFormat" BO_ 894 14;
BA_ "FrameRouting" BO_ 75 "HS2_CAN,0x4B;FD1_CAN,0x4B";
BA_ "VFrameFormat" BO_ 75 14;
BA_ "FrameRouting" BO_ 74 "HS2_CAN,0x4A;FD1_CAN,0x4A";
BA_ "VFrameFormat" BO_ 74 14;
BA_ "FrameRouting" BO_ 382 "FD1_CAN,0x17E;";
BA_ "VFrameFormat" BO_ 382 14;
BA_ "FrameRouting" BO_ 898 "HS2_CAN,0x382;FD1_CAN,0x382";
BA_ "VFrameFormat" BO_ 898 14;
BA_ "SC_Message" BO_ 536 1;
BA_ "SCP_DataId" BO_ 536 4632;
BA_ "FrameRouting" BO_ 536 "FD1_CAN,0x218;";
BA_ "VFrameFormat" BO_ 536 14;
BA_ "GenMsgSendType" BO_ 626 5;
BA_ "GenMsgCycleTime" BO_ 626 200;
BA_ "VFrameFormat" BO_ 626 14;
BA_ "FrameRouting" BO_ 1012 "FD1_CAN,0x3F4;";
BA_ "VFrameFormat" BO_ 1012 14;
BA_ "TpTxIndex" BO_ 2612002008 464518360;
BA_ "GenMsgSendType" BO_ 2612002008 1;
BA_ "GenMsgDelayTime" BO_ 2612002008 0;
BA_ "NetworkInitialization" BO_ 2612002008 0;
BA_ "TpTxIndex" BO_ 2610953432 463469784;
BA_ "GenMsgSendType" BO_ 2610953432 1;
BA_ "GenMsgDelayTime" BO_ 2610953432 0;
BA_ "NetworkInitialization" BO_ 2610953432 0;
BA_ "SC_Message" BO_ 516 1;
BA_ "SCP_DataId" BO_ 516 4612;
BA_ "FrameRouting" BO_ 516 "FD1_CAN,0x204;";
BA_ "VFrameFormat" BO_ 516 14;
BA_ "FrameRouting" BO_ 1091 "HS3_CAN,0x443;";
BA_ "VFrameFormat" BO_ 1091 14;
BA_ "SC_Message" BO_ 359 1;
BA_ "SCP_DataId" BO_ 359 4455;
BA_ "FrameRouting" BO_ 359 "FD1_CAN,0x167;";
BA_ "VFrameFormat" BO_ 359 14;
BA_ "FrameRouting" BO_ 374 "FD1_CAN,0x176;";
BA_ "VFrameFormat" BO_ 374 14;
BA_ "TpTxIndex" BO_ 702 54;
BA_ "VFrameFormat" BO_ 702 14;
BA_ "GenMsgILSupport" BO_ 1876 0;
BA_ "DiagRequest" BO_ 1876 1;
BA_ "GenMsgSendType" BO_ 1876 1;
BA_ "GenMsgDelayTime" BO_ 1876 0;
BA_ "NetworkInitialization" BO_ 1876 0;
BA_ "VFrameFormat" BO_ 1876 14;
BA_ "GenMsgILSupport" BO_ 1884 0;
BA_ "DiagResponse" BO_ 1884 1;
BA_ "GenMsgSendType" BO_ 1884 1;
BA_ "GenMsgDelayTime" BO_ 1884 0;
BA_ "NetworkInitialization" BO_ 1884 0;
BA_ "VFrameFormat" BO_ 1884 14;
BA_ "GenMsgILSupport" BO_ 1424 0;
BA_ "NmAsrMessage" BO_ 1424 1;
BA_ "GenMsgSendType" BO_ 1424 0;
BA_ "GenMsgCycleTime" BO_ 1424 1000;
BA_ "NetworkInitialization" BO_ 1424 0;
BA_ "VFrameFormat" BO_ 1424 14;
BA_ "FrameRouting" BO_ 479 "HS3_CAN,0x1DF;";
BA_ "VFrameFormat" BO_ 479 14;
BA_ "FrameRouting" BO_ 765 "HS3_CAN,0x2FD;";
BA_ "VFrameFormat" BO_ 765 14;
BA_ "FrameRouting" BO_ 739 "HS3_CAN,0x2E3;";
BA_ "VFrameFormat" BO_ 739 14;
BA_ "FrameRouting" BO_ 553 "HS3_CAN,0x229;";
BA_ "VFrameFormat" BO_ 553 14;
BA_ "FrameRouting" BO_ 1072 "HS3_CAN,0x430;";
BA_ "VFrameFormat" BO_ 1072 14;
BA_ "SC_Message" BO_ 534 1;
BA_ "SCP_DataId" BO_ 534 4630;
BA_ "FrameRouting" BO_ 534 "FD1_CAN,0x216;";
BA_ "VFrameFormat" BO_ 534 14;
BA_ "FrameRouting" BO_ 76 "HS2_CAN,0x4C";
BA_ "VFrameFormat" BO_ 76 14;
BA_ "TpTxIndex" BO_ 694 54;
BA_ "VFrameFormat" BO_ 694 14;
BA_ "GenMsgILSupport" BO_ 1745 0;
BA_ "DiagRequest" BO_ 1745 1;
BA_ "GenMsgSendType" BO_ 1745 1;
BA_ "GenMsgDelayTime" BO_ 1745 0;
BA_ "NetworkInitialization" BO_ 1745 0;
BA_ "VFrameFormat" BO_ 1745 14;
BA_ "GenMsgILSupport" BO_ 1438 0;
BA_ "NmAsrMessage" BO_ 1438 1;
BA_ "GenMsgSendType" BO_ 1438 0;
BA_ "GenMsgCycleTime" BO_ 1438 1000;
BA_ "NetworkInitialization" BO_ 1438 0;
BA_ "VFrameFormat" BO_ 1438 14;
BA_ "GenMsgILSupport" BO_ 1814 0;
BA_ "DiagRequest" BO_ 1814 1;
BA_ "GenMsgSendType" BO_ 1814 1;
BA_ "GenMsgDelayTime" BO_ 1814 0;
BA_ "NetworkInitialization" BO_ 1814 0;
BA_ "VFrameFormat" BO_ 1814 14;
BA_ "GenMsgILSupport" BO_ 1822 0;
BA_ "DiagResponse" BO_ 1822 1;
BA_ "GenMsgSendType" BO_ 1822 1;
BA_ "GenMsgDelayTime" BO_ 1822 0;
BA_ "NetworkInitialization" BO_ 1822 0;
BA_ "VFrameFormat" BO_ 1822 14;
BA_ "FrameRouting" BO_ 1085 "HS2_CAN,0x43D;FD1_CAN,0x43D";
BA_ "VFrameFormat" BO_ 1085 14;
BA_ "SC_Message" BO_ 514 1;
BA_ "SCP_DataId" BO_ 514 4610;
BA_ "FrameRouting" BO_ 514 "FD1_CAN,0x202;";
BA_ "VFrameFormat" BO_ 514 14;
BA_ "FrameRouting" BO_ 560 "FD1_CAN,0x230;";
BA_ "VFrameFormat" BO_ 560 14;
BA_ "SC_Message" BO_ 817 1;
BA_ "SCP_DataId" BO_ 817 9009;
BA_ "FrameRouting" BO_ 817 "FD1_CAN,0x331;";
BA_ "VFrameFormat" BO_ 817 14;
BA_ "SC_Message" BO_ 1084 1;
BA_ "SCP_DataId" BO_ 1084 13372;
BA_ "FrameRouting" BO_ 1084 "FD1_CAN,0x43C;";
BA_ "VFrameFormat" BO_ 1084 14;
BA_ "SC_Message" BO_ 1068 1;
BA_ "SCP_DataId" BO_ 1068 5164;
BA_ "FrameRouting" BO_ 1068 "FD1_CAN,0x42C;";
BA_ "VFrameFormat" BO_ 1068 14;
BA_ "SC_Message" BO_ 1144 1;
BA_ "SCP_DataId" BO_ 1144 5240;
BA_ "FrameRouting" BO_ 1144 "FD1_CAN,0x478;";
BA_ "VFrameFormat" BO_ 1144 14;
BA_ "GenMsgILSupport" BO_ 2015 0;
BA_ "DiagState" BO_ 2015 1;
BA_ "GenMsgSendType" BO_ 2015 1;
BA_ "GenMsgDelayTime" BO_ 2015 0;
BA_ "NetworkInitialization" BO_ 2015 0;
BA_ "VFrameFormat" BO_ 2015 14;
BA_ "SC_Message" BO_ 1034 1;
BA_ "SCP_DataId" BO_ 1034 5130;
BA_ "FrameRouting" BO_ 1034 "FD1_CAN,0x40A;";
BA_ "VFrameFormat" BO_ 1034 14;
BA_ "SC_Message" BO_ 1200 1;
BA_ "SCP_DataId" BO_ 1200 5296;
BA_ "FrameRouting" BO_ 1200 "FD1_CAN,0x4B0;";
BA_ "VFrameFormat" BO_ 1200 14;
BA_ "U_P708_MY2023_Rx" SG_ 1054 DrvSlipCtlOffLamp_D_Rq 1;
BA_ "U_CDX74X_MY2024_Rx" SG_ 1054 DrvSlipCtlOffLamp_D_Rq 1;
BA_ "GenSigStartValue" SG_ 1054 SelDrvMdeAwd_D_Rq 31;
BA_ "WakeupSignal" SG_ 1054 BrkMdeInhbt_B_RqDsply 1;
BA_ "GenSigStartValue" SG_ 1054 BrkLineLck_D_Stat 4;
BA_ "MetaData" SG_ 931 StrtrMtrCtlDStat_No_Cs 1;
BA_ "MetaData" SG_ 931 CrnkInhbt_No_Cs 1;
BA_ "MetaData" SG_ 931 CrnkInhbt_No_Cnt 1;
BA_ "GenSigStartValue" SG_ 931 CrnkInhbt_B_Stat 1;
BA_ "GenSigStartValue" SG_ 130 Veh_V_RqMxTrlrAid 255;
BA_ "GenSigStartValue" SG_ 130 SteMdule_U_Meas 255;
BA_ "GenSigStartValue" SG_ 130 SteMdule_I_Est 4095;
BA_ "GenSigStartValue" SG_ 130 SteeringColumnTorque 254;
BA_ "GenSigStartValue" SG_ 1046 HsaMde_D_Mem 1;
BA_ "GenSigStartValue" SG_ 1046 RearDiffLck_Tq2_RqMx 4094;
BA_ "U_P708_MY2023_Rx" SG_ 1046 TCMode 1;
BA_ "U_CDX74X_MY2024_Rx" SG_ 1046 TCMode 1;
BA_ "U_P708_MY2023_Rx" SG_ 1046 Abs_B_Falt 1;
BA_ "U_CDX74X_MY2024_Rx" SG_ 1046 Abs_B_Falt 1;
BA_ "MetaData" SG_ 1046 BpedMove_No_Cnt 1;
BA_ "GenSigStartValue" SG_ 1046 StabCtlBrk_B_Avail 1;
BA_ "GenSigStartValue" SG_ 1046 BpedMove_D_Actl 3;
BA_ "MetaData" SG_ 1046 BpedDiffLckTq_No_Cs 1;
BA_ "GenSigStartValue" SG_ 1234 RmtCtlConfgSrc_D_Stat 1;
BA_ "GenSigStartValue" SG_ 125 VehRolComp_W_Actl 4094;
BA_ "GenSigStartValue" SG_ 125 VehVertComp_A_Actl 1022;
BA_ "MetaData" SG_ 125 BrkTotTqRqArb_No_Cs 1;
BA_ "MetaData" SG_ 125 BrkTotTqRqArb_No_Cnt 1;
BA_ "U_V713AV_MY2022_Rx" SG_ 125 BrkTot_Tq_RqArb 1;
BA_ "U_P708_MY2023_Rx" SG_ 125 BrkTot_Tq_RqArb 1;
BA_ "U_CDX74X_MY2024_Rx" SG_ 125 BrkTot_Tq_RqArb 1;
BA_ "U_V710_MY2023_Rx" SG_ 125 BrkTot_Tq_RqArb 1;
BA_ "GenSigStartValue" SG_ 531 VehStop_D_Stat 2;
BA_ "U_V713AV_MY2022_Rx" SG_ 531 TracCtlPtActv_B_Actl 1;
BA_ "WakeupSignal" SG_ 531 PrkBrkYwLamp_D_Rq 1;
BA_ "WakeupSignal" SG_ 531 PrkBrkRedLamp_D_Rq 1;
BA_ "U_P708_MY2023_Rx" SG_ 531 LscmbbBrkDecel_B_Actl 1;
BA_ "U_CDX74X_MY2024_Rx" SG_ 531 LscmbbBrkDecel_B_Actl 1;
BA_ "U_V713AV_MY2022_Rx" SG_ 531 AbsActv_B_Actl 1;
BA_ "U_P708_MY2023_Rx" SG_ 531 AbsActv_B_Actl 1;
BA_ "U_CDX74X_MY2024_Rx" SG_ 531 AbsActv_B_Actl 1;
BA_ "U_V710_MY2023_Rx" SG_ 531 AbsActv_B_Actl 1;
BA_ "U_P708_MY2023_Rx" SG_ 531 StabCtlBrkActv_B_Actl 1;
BA_ "U_CDX74X_MY2024_Rx" SG_ 531 StabCtlBrkActv_B_Actl 1;
BA_ "U_P708_MY2023_Rx" SG_ 531 LscmbBrkPrchg_B_Actl 1;
BA_ "U_CDX74X_MY2024_Rx" SG_ 531 LscmbBrkPrchg_B_Actl 1;
BA_ "WakeupSignal" SG_ 531 PrkBrkMsgTxt_D_Rq 1;
BA_ "GenSigStartValue" SG_ 531 PrkBrkStatus 7;
BA_ "U_P708_MY2023_Rx" SG_ 531 PrkBrkStatus 1;
BA_ "U_CDX74X_MY2024_Rx" SG_ 531 PrkBrkStatus 1;
BA_ "GenSigSendType" SG_ 1841 TesterPhysicalReqRFA 3;
BA_ "GenSigSendType" SG_ 638 EmgcyCallHmi_D_Stat 3;
BA_ "U_V713AV_MY2022_Tx" SG_ 638 EmgcyCallHmi_D_Stat 1;
BA_ "U_P708_MY2023_Tx" SG_ 638 EmgcyCallHmi_D_Stat 1;
BA_ "U_CDX74X_MY2024_Tx" SG_ 638 EmgcyCallHmi_D_Stat 1;
BA_ "U_V710_MY2023_Tx" SG_ 638 EmgcyCallHmi_D_Stat 1;
BA_ "GenSigSendType" SG_ 638 EmgcyCallFalt_B_Dsply 3;
BA_ "U_V713AV_MY2022_Tx" SG_ 638 EmgcyCallFalt_B_Dsply 1;
BA_ "U_P708_MY2023_Tx" SG_ 638 EmgcyCallFalt_B_Dsply 1;
BA_ "U_CDX74X_MY2024_Tx" SG_ 638 EmgcyCallFalt_B_Dsply 1;
BA_ "U_V710_MY2023_Tx" SG_ 638 EmgcyCallFalt_B_Dsply 1;
BA_ "U_V713AV_MY2022_Tx" SG_ 638 EmgcyCallCancl_T_Actl 1;
BA_ "U_P708_MY2023_Tx" SG_ 638 EmgcyCallCancl_T_Actl 1;
BA_ "U_CDX74X_MY2024_Tx" SG_ 638 EmgcyCallCancl_T_Actl 1;
BA_ "U_V710_MY2023_Tx" SG_ 638 EmgcyCallCancl_T_Actl 1;
BA_ "GenSigSendType" SG_ 638 EmgcyCall_D_Stat 3;
BA_ "U_V713AV_MY2022_Tx" SG_ 638 EmgcyCall_D_Stat 1;
BA_ "U_P708_MY2023_Tx" SG_ 638 EmgcyCall_D_Stat 1;
BA_ "U_CDX74X_MY2024_Tx" SG_ 638 EmgcyCall_D_Stat 1;
BA_ "U_V710_MY2023_Tx" SG_ 638 EmgcyCall_D_Stat 1;
BA_ "U_V713N_MY2022_Tx" SG_ 1184 APIM_TCU_Word_Rx 1;
BA_ "U_V713AV_MY2022_Tx" SG_ 1184 APIM_TCU_Word_Rx 1;
BA_ "U_P708_MY2023_Tx" SG_ 1184 APIM_TCU_Word_Rx 1;
BA_ "U_CDX74X_MY2024_Tx" SG_ 1184 APIM_TCU_Word_Rx 1;
BA_ "U_V710_MY2023_Tx" SG_ 1184 APIM_TCU_Word_Rx 1;
BA_ "U_V713AV_MY2022_Rx" SG_ 894 RmtCtlTrgtBody_D_Stat 1;
BA_ "U_V713AV_MY2022_Rx" SG_ 894 RmtCtlTrgt_D_Rq 1;
BA_ "U_V713AV_MY2022_Rx" SG_ 894 RmtCtlRngSet_D_Stat 1;
BA_ "U_V713AV_MY2022_Rx" SG_ 894 RmtCtlKeySrch_D_Stat 1;
BA_ "U_V713AV_MY2022_Rx" SG_ 894 RmtCtlBody_D_Stat 1;
BA_ "U_V713AV_MY2022_Rx" SG_ 894 RmtCtl_D_RqBody 1;
BA_ "U_V713AV_MY2022_Rx" SG_ 75 VedsPasKneeBag_D_Ltchd 1;
BA_ "U_P708_MY2023_Rx" SG_ 75 VedsPasKneeBag_D_Ltchd 1;
BA_ "U_CDX74X_MY2024_Rx" SG_ 75 VedsPasKneeBag_D_Ltchd 1;
BA_ "U_V710_MY2023_Rx" SG_ 75 VedsPasKneeBag_D_Ltchd 1;
BA_ "U_V713AV_MY2022_Rx" SG_ 75 VedsRw3pRib_D_Ltchd 1;
BA_ "U_P708_MY2023_Rx" SG_ 75 VedsRw3pRib_D_Ltchd 1;
BA_ "U_CDX74X_MY2024_Rx" SG_ 75 VedsRw3pRib_D_Ltchd 1;
BA_ "U_V710_MY2023_Rx" SG_ 75 VedsRw3pRib_D_Ltchd 1;
BA_ "U_V713AV_MY2022_Rx" SG_ 75 VedsRw3dRib_D_Ltchd 1;
BA_ "U_P708_MY2023_Rx" SG_ 75 VedsRw3dRib_D_Ltchd 1;
BA_ "U_CDX74X_MY2024_Rx" SG_ 75 VedsRw3dRib_D_Ltchd 1;
BA_ "U_V710_MY2023_Rx" SG_ 75 VedsRw3dRib_D_Ltchd 1;
BA_ "U_V713AV_MY2022_Rx" SG_ 75 VedsRw1mBckl_D_Ltchd 1;
BA_ "U_P708_MY2023_Rx" SG_ 75 VedsRw1mBckl_D_Ltchd 1;
BA_ "U_CDX74X_MY2024_Rx" SG_ 75 VedsRw1mBckl_D_Ltchd 1;
BA_ "U_V710_MY2023_Rx" SG_ 75 VedsRw1mBckl_D_Ltchd 1;
BA_ "U_V713AV_MY2022_Rx" SG_ 75 VedsRw1mBelt_D_Ltchd 1;
BA_ "U_P708_MY2023_Rx" SG_ 75 VedsRw1mBelt_D_Ltchd 1;
BA_ "U_CDX74X_MY2024_Rx" SG_ 75 VedsRw1mBelt_D_Ltchd 1;
BA_ "U_V710_MY2023_Rx" SG_ 75 VedsRw1mBelt_D_Ltchd 1;
BA_ "U_V713AV_MY2022_Rx" SG_ 75 VedsRw2pRib_D_Ltchd 1;
BA_ "U_P708_MY2023_Rx" SG_ 75 VedsRw2pRib_D_Ltchd 1;
BA_ "U_CDX74X_MY2024_Rx" SG_ 75 VedsRw2pRib_D_Ltchd 1;
BA_ "U_V710_MY2023_Rx" SG_ 75 VedsRw2pRib_D_Ltchd 1;
BA_ "U_V713AV_MY2022_Rx" SG_ 75 VedsRw2dRib_D_Ltchd 1;
BA_ "U_P708_MY2023_Rx" SG_ 75 VedsRw2dRib_D_Ltchd 1;
BA_ "U_CDX74X_MY2024_Rx" SG_ 75 VedsRw2dRib_D_Ltchd 1;
BA_ "U_V710_MY2023_Rx" SG_ 75 VedsRw2dRib_D_Ltchd 1;
BA_ "U_V713AV_MY2022_Rx" SG_ 75 VedsRw3pBckl_D_Ltchd 1;
BA_ "U_P708_MY2023_Rx" SG_ 75 VedsRw3pBckl_D_Ltchd 1;
BA_ "U_CDX74X_MY2024_Rx" SG_ 75 VedsRw3pBckl_D_Ltchd 1;
BA_ "U_V710_MY2023_Rx" SG_ 75 VedsRw3pBckl_D_Ltchd 1;
BA_ "U_V713AV_MY2022_Rx" SG_ 75 VedsRw3mBckl_D_Ltchd 1;
BA_ "U_P708_MY2023_Rx" SG_ 75 VedsRw3mBckl_D_Ltchd 1;
BA_ "U_CDX74X_MY2024_Rx" SG_ 75 VedsRw3mBckl_D_Ltchd 1;
BA_ "U_V710_MY2023_Rx" SG_ 75 VedsRw3mBckl_D_Ltchd 1;
BA_ "U_V713AV_MY2022_Rx" SG_ 75 VedsRw3dBckl_D_Ltchd 1;
BA_ "U_P708_MY2023_Rx" SG_ 75 VedsRw3dBckl_D_Ltchd 1;
BA_ "U_CDX74X_MY2024_Rx" SG_ 75 VedsRw3dBckl_D_Ltchd 1;
BA_ "U_V710_MY2023_Rx" SG_ 75 VedsRw3dBckl_D_Ltchd 1;
BA_ "U_V713AV_MY2022_Rx" SG_ 75 VedsRw2pBckl_D_Ltchd 1;
BA_ "U_P708_MY2023_Rx" SG_ 75 VedsRw2pBckl_D_Ltchd 1;
BA_ "U_CDX74X_MY2024_Rx" SG_ 75 VedsRw2pBckl_D_Ltchd 1;
BA_ "U_V710_MY2023_Rx" SG_ 75 VedsRw2pBckl_D_Ltchd 1;
BA_ "U_V713AV_MY2022_Rx" SG_ 75 VedsRw2mBckl_D_Ltchd 1;
BA_ "U_P708_MY2023_Rx" SG_ 75 VedsRw2mBckl_D_Ltchd 1;
BA_ "U_CDX74X_MY2024_Rx" SG_ 75 VedsRw2mBckl_D_Ltchd 1;
BA_ "U_V710_MY2023_Rx" SG_ 75 VedsRw2mBckl_D_Ltchd 1;
BA_ "U_V713AV_MY2022_Rx" SG_ 75 VedsRw2dBckl_D_Ltchd 1;
BA_ "U_P708_MY2023_Rx" SG_ 75 VedsRw2dBckl_D_Ltchd 1;
BA_ "U_CDX74X_MY2024_Rx" SG_ 75 VedsRw2dBckl_D_Ltchd 1;
BA_ "U_V710_MY2023_Rx" SG_ 75 VedsRw2dBckl_D_Ltchd 1;
BA_ "U_V713AV_MY2022_Rx" SG_ 75 VedsRw1PasChld_D_Ltchd 1;
BA_ "U_P708_MY2023_Rx" SG_ 75 VedsRw1PasChld_D_Ltchd 1;
BA_ "U_CDX74X_MY2024_Rx" SG_ 75 VedsRw1PasChld_D_Ltchd 1;
BA_ "U_V710_MY2023_Rx" SG_ 75 VedsRw1PasChld_D_Ltchd 1;
BA_ "U_V713AV_MY2022_Rx" SG_ 75 VedsRw1PasBckl_D_Ltchd 1;
BA_ "U_P708_MY2023_Rx" SG_ 75 VedsRw1PasBckl_D_Ltchd 1;
BA_ "U_CDX74X_MY2024_Rx" SG_ 75 VedsRw1PasBckl_D_Ltchd 1;
BA_ "U_V710_MY2023_Rx" SG_ 75 VedsRw1PasBckl_D_Ltchd 1;
BA_ "U_V713AV_MY2022_Rx" SG_ 75 VedsRw1DrvBckl_D_Ltchd 1;
BA_ "U_P708_MY2023_Rx" SG_ 75 VedsRw1DrvBckl_D_Ltchd 1;
BA_ "U_CDX74X_MY2024_Rx" SG_ 75 VedsRw1DrvBckl_D_Ltchd 1;
BA_ "U_V710_MY2023_Rx" SG_ 75 VedsRw1DrvBckl_D_Ltchd 1;
BA_ "U_V713AV_MY2022_Rx" SG_ 74 VedsPasSideBag_D_Ltchd 1;
BA_ "U_P708_MY2023_Rx" SG_ 74 VedsPasSideBag_D_Ltchd 1;
BA_ "U_CDX74X_MY2024_Rx" SG_ 74 VedsPasSideBag_D_Ltchd 1;
BA_ "U_V710_MY2023_Rx" SG_ 74 VedsPasSideBag_D_Ltchd 1;
BA_ "U_V713AV_MY2022_Rx" SG_ 74 VedsPasCrtnBag_D_Ltchd 1;
BA_ "U_P708_MY2023_Rx" SG_ 74 VedsPasCrtnBag_D_Ltchd 1;
BA_ "U_CDX74X_MY2024_Rx" SG_ 74 VedsPasCrtnBag_D_Ltchd 1;
BA_ "U_V710_MY2023_Rx" SG_ 74 VedsPasCrtnBag_D_Ltchd 1;
BA_ "U_V713AV_MY2022_Rx" SG_ 74 VedsPasBelt_D_Ltchd 1;
BA_ "U_P708_MY2023_Rx" SG_ 74 VedsPasBelt_D_Ltchd 1;
BA_ "U_CDX74X_MY2024_Rx" SG_ 74 VedsPasBelt_D_Ltchd 1;
BA_ "U_V710_MY2023_Rx" SG_ 74 VedsPasBelt_D_Ltchd 1;
BA_ "U_V713AV_MY2022_Rx" SG_ 74 VedsPasBag_D_Ltchd 1;
BA_ "U_P708_MY2023_Rx" SG_ 74 VedsPasBag_D_Ltchd 1;
BA_ "U_CDX74X_MY2024_Rx" SG_ 74 VedsPasBag_D_Ltchd 1;
BA_ "U_V710_MY2023_Rx" SG_ 74 VedsPasBag_D_Ltchd 1;
BA_ "U_V713AV_MY2022_Rx" SG_ 74 VedsMultiEvnt_D_Ltchd 1;
BA_ "U_P708_MY2023_Rx" SG_ 74 VedsMultiEvnt_D_Ltchd 1;
BA_ "U_CDX74X_MY2024_Rx" SG_ 74 VedsMultiEvnt_D_Ltchd 1;
BA_ "U_V710_MY2023_Rx" SG_ 74 VedsMultiEvnt_D_Ltchd 1;
BA_ "U_V713AV_MY2022_Rx" SG_ 74 VedsMaxDeltaV_D_Ltchd 1;
BA_ "U_P708_MY2023_Rx" SG_ 74 VedsMaxDeltaV_D_Ltchd 1;
BA_ "U_CDX74X_MY2024_Rx" SG_ 74 VedsMaxDeltaV_D_Ltchd 1;
BA_ "U_V710_MY2023_Rx" SG_ 74 VedsMaxDeltaV_D_Ltchd 1;
BA_ "U_V713AV_MY2022_Rx" SG_ 74 VedsDrvKneeBag_D_Ltchd 1;
BA_ "U_P708_MY2023_Rx" SG_ 74 VedsDrvKneeBag_D_Ltchd 1;
BA_ "U_CDX74X_MY2024_Rx" SG_ 74 VedsDrvKneeBag_D_Ltchd 1;
BA_ "U_V710_MY2023_Rx" SG_ 74 VedsDrvKneeBag_D_Ltchd 1;
BA_ "U_V713AV_MY2022_Rx" SG_ 74 VedsEvntType_D_Ltchd 1;
BA_ "U_P708_MY2023_Rx" SG_ 74 VedsEvntType_D_Ltchd 1;
BA_ "U_CDX74X_MY2024_Rx" SG_ 74 VedsEvntType_D_Ltchd 1;
BA_ "U_V710_MY2023_Rx" SG_ 74 VedsEvntType_D_Ltchd 1;
BA_ "U_V713AV_MY2022_Rx" SG_ 74 VedsEvntRoll_D_Ltchd 1;
BA_ "U_P708_MY2023_Rx" SG_ 74 VedsEvntRoll_D_Ltchd 1;
BA_ "U_CDX74X_MY2024_Rx" SG_ 74 VedsEvntRoll_D_Ltchd 1;
BA_ "U_V710_MY2023_Rx" SG_ 74 VedsEvntRoll_D_Ltchd 1;
BA_ "U_V713AV_MY2022_Rx" SG_ 74 VedsDrvSideBag_D_Ltchd 1;
BA_ "U_P708_MY2023_Rx" SG_ 74 VedsDrvSideBag_D_Ltchd 1;
BA_ "U_CDX74X_MY2024_Rx" SG_ 74 VedsDrvSideBag_D_Ltchd 1;
BA_ "U_V710_MY2023_Rx" SG_ 74 VedsDrvSideBag_D_Ltchd 1;
BA_ "U_V713AV_MY2022_Rx" SG_ 74 VedsDrvCrtnBag_D_Ltchd 1;
BA_ "U_P708_MY2023_Rx" SG_ 74 VedsDrvCrtnBag_D_Ltchd 1;
BA_ "U_CDX74X_MY2024_Rx" SG_ 74 VedsDrvCrtnBag_D_Ltchd 1;
BA_ "U_V710_MY2023_Rx" SG_ 74 VedsDrvCrtnBag_D_Ltchd 1;
BA_ "U_V713AV_MY2022_Rx" SG_ 74 VedsDrvBelt_D_Ltchd 1;
BA_ "U_P708_MY2023_Rx" SG_ 74 VedsDrvBelt_D_Ltchd 1;
BA_ "U_CDX74X_MY2024_Rx" SG_ 74 VedsDrvBelt_D_Ltchd 1;
BA_ "U_V710_MY2023_Rx" SG_ 74 VedsDrvBelt_D_Ltchd 1;
BA_ "U_V713AV_MY2022_Rx" SG_ 74 VedsDrvBag_D_Ltchd 1;
BA_ "U_P708_MY2023_Rx" SG_ 74 VedsDrvBag_D_Ltchd 1;
BA_ "U_CDX74X_MY2024_Rx" SG_ 74 VedsDrvBag_D_Ltchd 1;
BA_ "U_V710_MY2023_Rx" SG_ 74 VedsDrvBag_D_Ltchd 1;
BA_ "GenSigStartValue" SG_ 74 eCallNotification 1;
BA_ "U_V713AV_MY2022_Rx" SG_ 74 eCallNotification 1;
BA_ "U_P708_MY2023_Rx" SG_ 74 eCallNotification 1;
BA_ "U_CDX74X_MY2024_Rx" SG_ 74 eCallNotification 1;
BA_ "U_V710_MY2023_Rx" SG_ 74 eCallNotification 1;
BA_ "GenSigStartValue" SG_ 898 VedsRoll_An_Ltchd 4096;
BA_ "U_P708_MY2023_Rx" SG_ 898 VedsRoll_An_Ltchd 1;
BA_ "U_CDX74X_MY2024_Rx" SG_ 898 VedsRoll_An_Ltchd 1;
BA_ "GenSigStartValue" SG_ 898 VedsPrmDirOfF_An_Ltchd 90;
BA_ "U_P708_MY2023_Rx" SG_ 898 VedsPrmDirOfF_An_Ltchd 1;
BA_ "U_CDX74X_MY2024_Rx" SG_ 898 VedsPrmDirOfF_An_Ltchd 1;
BA_ "GenSigStartValue" SG_ 898 SecondRowBcklPsngrMid 3;
BA_ "GenSigStartValue" SG_ 898 SecondRowBuckleDrvMid 3;
BA_ "GenSigStartValue" SG_ 898 FourthRowBucklePsngr 3;
BA_ "GenSigStartValue" SG_ 898 FourthRowBuckleMid 3;
BA_ "GenSigStartValue" SG_ 898 FourthRowBuckleDriver 3;
BA_ "GenSigStartValue" SG_ 898 Row3PsngrPrsnc_D_Actl 3;
BA_ "GenSigStartValue" SG_ 898 Row3MidPrsnc_D_Actl 3;
BA_ "GenSigStartValue" SG_ 898 Row3DrvPrsnc_D_Actl 3;
BA_ "GenSigStartValue" SG_ 898 Row2PsngrPrsnc_D_Actl 3;
BA_ "GenSigStartValue" SG_ 898 Row2MidPrsnc_D_Actl 3;
BA_ "GenSigStartValue" SG_ 898 Row2DrvPrsnc_D_Actl 3;
BA_ "U_P708_MY2023_Rx" SG_ 536 BrkCtlSys_D_Stat 1;
BA_ "U_CDX74X_MY2024_Rx" SG_ 536 BrkCtlSys_D_Stat 1;
BA_ "GenSigStartValue" SG_ 536 VehStab_D_Cnfm 14;
BA_ "MetaData" SG_ 536 BrkWhlFricTq_No_Cs 1;
BA_ "MetaData" SG_ 536 BrkWhlFricTq_No_Cnt 1;
BA_ "GenSigStartValue" SG_ 536 BrkWhlFricRr_Tq_Actl 254;
BA_ "GenSigStartValue" SG_ 536 BrkWhlFricRl_Tq_Actl 254;
BA_ "GenSigStartValue" SG_ 536 BrkWhlFricFr_Tq_Actl 254;
BA_ "GenSigStartValue" SG_ 536 BrkWhlFricFl_Tq_Actl 254;
BA_ "WakeupSignal" SG_ 626 PaakCtlRollCd2_No_Copy 1;
BA_ "GenSigSendType" SG_ 626 PaakCtlRollCd2_No_Copy 3;
BA_ "U_V713AV_MY2022_Tx" SG_ 626 PaakCtlRollCd2_No_Copy 1;
BA_ "WakeupSignal" SG_ 626 PaakCtlIndx8_D_Stat 1;
BA_ "GenSigSendType" SG_ 626 PaakCtlIndx8_D_Stat 3;
BA_ "U_V713AV_MY2022_Tx" SG_ 626 PaakCtlIndx8_D_Stat 1;
BA_ "WakeupSignal" SG_ 626 PaakCtlIndx7_D_Stat 1;
BA_ "GenSigSendType" SG_ 626 PaakCtlIndx7_D_Stat 3;
BA_ "U_V713AV_MY2022_Tx" SG_ 626 PaakCtlIndx7_D_Stat 1;
BA_ "WakeupSignal" SG_ 626 PaakCtlIndx6_D_Stat 1;
BA_ "GenSigSendType" SG_ 626 PaakCtlIndx6_D_Stat 3;
BA_ "U_V713AV_MY2022_Tx" SG_ 626 PaakCtlIndx6_D_Stat 1;
BA_ "WakeupSignal" SG_ 626 PaakCtlIndx5_D_Stat 1;
BA_ "GenSigSendType" SG_ 626 PaakCtlIndx5_D_Stat 3;
BA_ "U_V713AV_MY2022_Tx" SG_ 626 PaakCtlIndx5_D_Stat 1;
BA_ "WakeupSignal" SG_ 626 PaakCtlIndx4_D_Stat 1;
BA_ "GenSigSendType" SG_ 626 PaakCtlIndx4_D_Stat 3;
BA_ "U_V713AV_MY2022_Tx" SG_ 626 PaakCtlIndx4_D_Stat 1;
BA_ "WakeupSignal" SG_ 626 PaakCtlIndx3_D_Stat 1;
BA_ "GenSigSendType" SG_ 626 PaakCtlIndx3_D_Stat 3;
BA_ "U_V713AV_MY2022_Tx" SG_ 626 PaakCtlIndx3_D_Stat 1;
BA_ "WakeupSignal" SG_ 626 PaakCtlIndx2_D_Stat 1;
BA_ "GenSigSendType" SG_ 626 PaakCtlIndx2_D_Stat 3;
BA_ "U_V713AV_MY2022_Tx" SG_ 626 PaakCtlIndx2_D_Stat 1;
BA_ "WakeupSignal" SG_ 626 PaakCtlIndx1_D_Stat 1;
BA_ "GenSigSendType" SG_ 626 PaakCtlIndx1_D_Stat 3;
BA_ "U_V713AV_MY2022_Tx" SG_ 626 PaakCtlIndx1_D_Stat 1;
BA_ "GenSigStartValue" SG_ 1012 ChrgLocLongFrct_An_Sav 1048575;
BA_ "GenSigStartValue" SG_ 1012 ChrgLocLattFrct_An_Sav 1048575;
BA_ "GenSigSendType" SG_ 2612002008 PARSEDFuncGWM_ECG 3;
BA_ "ECGUsedTxSignal" SG_ 2612002008 PARSEDFuncGWM_ECG 1;
BA_ "U_V713N_MY2022_Tx" SG_ 2612002008 PARSEDFuncGWM_ECG 1;
BA_ "U_V713AV_MY2022_Tx" SG_ 2612002008 PARSEDFuncGWM_ECG 1;
BA_ "U_P708_MY2023_Tx" SG_ 2612002008 PARSEDFuncGWM_ECG 1;
BA_ "U_CDX74X_MY2024_Tx" SG_ 2612002008 PARSEDFuncGWM_ECG 1;
BA_ "U_V710_MY2023_Tx" SG_ 2612002008 PARSEDFuncGWM_ECG 1;
BA_ "GenSigSendType" SG_ 2610953432 OTAFuncGWM_ECG 3;
BA_ "ECGUsedTxSignal" SG_ 2610953432 OTAFuncGWM_ECG 1;
BA_ "U_V713N_MY2022_Tx" SG_ 2610953432 OTAFuncGWM_ECG 1;
BA_ "U_V713AV_MY2022_Tx" SG_ 2610953432 OTAFuncGWM_ECG 1;
BA_ "U_P708_MY2023_Tx" SG_ 2610953432 OTAFuncGWM_ECG 1;
BA_ "U_CDX74X_MY2024_Tx" SG_ 2610953432 OTAFuncGWM_ECG 1;
BA_ "U_V710_MY2023_Tx" SG_ 2610953432 OTAFuncGWM_ECG 1;
BA_ "MetaData" SG_ 516 EngAoutNActl_D_QF 1;
BA_ "GenSigStartValue" SG_ 516 EngAoutNActl_D_QF 1;
BA_ "U_V713AV_MY2022_Rx" SG_ 516 ApedPos_Pc_ActlArb 1;
BA_ "MetaData" SG_ 516 ApedPosPcActl_D_Qf 1;
BA_ "GenSigStartValue" SG_ 516 ApedPosPcActl_D_Qf 1;
BA_ "MetaData" SG_ 516 ApedPosPcActl_No_Cnt 1;
BA_ "MetaData" SG_ 516 ApedPosPcActl_No_Cs 1;
BA_ "GenSigStartValue" SG_ 1091 WakeAlarm2_T_Rq 32767;
BA_ "U_V713AV_MY2022_Rx" SG_ 1091 TrlrLampCnnct_B_Actl 1;
BA_ "U_V713AV_MY2022_Rx" SG_ 359 PwPckTq_D_Stat 1;
BA_ "GenSigStartValue" SG_ 359 PlgActvArb_B_Actl 1;
BA_ "MetaData" SG_ 359 TrnAinTq_D_Qf 1;
BA_ "GenSigStartValue" SG_ 374 TrnRng_D_Rq 14;
BA_ "MetaData" SG_ 374 GearPos_No_Cs 1;
BA_ "GenSigStartValue" SG_ 374 GearPos_D_Trg 15;
BA_ "U_V713AV_MY2022_Rx" SG_ 374 GearPos_D_Trg 1;
BA_ "MetaData" SG_ 374 GearPos_No_Cnt 1;
BA_ "GenSigStartValue" SG_ 374 GearPos_D_Actl 15;
BA_ "U_V713AV_MY2022_Rx" SG_ 702 ECG_RFA_BLEM_Word_Tx 1;
BA_ "ECGUsedTxSignal" SG_ 702 ECG_RFA_BLEM_Word_Tx 1;
BA_ "U_V713N_MY2022_Tx" SG_ 702 ECG_RFA_BLEM_Word_Tx 1;
BA_ "U_V713AV_MY2022_Tx" SG_ 702 ECG_RFA_BLEM_Word_Tx 1;
BA_ "U_CDX74X_MY2024_Tx" SG_ 702 ECG_RFA_BLEM_Word_Tx 1;
BA_ "GenSigSendType" SG_ 1876 TesterPhysicalReqTCU 3;
BA_ "U_V713N_MY2022_Rx" SG_ 1876 TesterPhysicalReqTCU 1;
BA_ "U_V713AV_MY2022_Rx" SG_ 1876 TesterPhysicalReqTCU 1;
BA_ "U_P708_MY2023_Rx" SG_ 1876 TesterPhysicalReqTCU 1;
BA_ "U_CDX74X_MY2024_Rx" SG_ 1876 TesterPhysicalReqTCU 1;
BA_ "U_V710_MY2023_Rx" SG_ 1876 TesterPhysicalReqTCU 1;
BA_ "GenSigSendType" SG_ 1884 TesterPhysicalResTCU 3;
BA_ "U_V713N_MY2022_Tx" SG_ 1884 TesterPhysicalResTCU 1;
BA_ "U_V713AV_MY2022_Tx" SG_ 1884 TesterPhysicalResTCU 1;
BA_ "U_P708_MY2023_Tx" SG_ 1884 TesterPhysicalResTCU 1;
BA_ "U_CDX74X_MY2024_Tx" SG_ 1884 TesterPhysicalResTCU 1;
BA_ "U_V710_MY2023_Tx" SG_ 1884 TesterPhysicalResTCU 1;
BA_ "GenSigStartValue" SG_ 1424 TCU_GWOnBoardTester 255;
BA_ "U_V713N_MY2022_Tx" SG_ 1424 TCU_GWOnBoardTester 1;
BA_ "U_V713AV_MY2022_Tx" SG_ 1424 TCU_GWOnBoardTester 1;
BA_ "U_P708_MY2023_Tx" SG_ 1424 TCU_GWOnBoardTester 1;
BA_ "U_CDX74X_MY2024_Tx" SG_ 1424 TCU_GWOnBoardTester 1;
BA_ "U_V710_MY2023_Tx" SG_ 1424 TCU_GWOnBoardTester 1;
BA_ "GenSigStartValue" SG_ 1424 TCU_GWNMProxy 255;
BA_ "U_V713N_MY2022_Tx" SG_ 1424 TCU_GWNMProxy 1;
BA_ "U_V713AV_MY2022_Tx" SG_ 1424 TCU_GWNMProxy 1;
BA_ "U_P708_MY2023_Tx" SG_ 1424 TCU_GWNMProxy 1;
BA_ "U_CDX74X_MY2024_Tx" SG_ 1424 TCU_GWNMProxy 1;
BA_ "U_V710_MY2023_Tx" SG_ 1424 TCU_GWNMProxy 1;
BA_ "GenSigStartValue" SG_ 1424 TCU_AutoSarNMReserved4 255;
BA_ "U_V713N_MY2022_Tx" SG_ 1424 TCU_AutoSarNMReserved4 1;
BA_ "U_V713AV_MY2022_Tx" SG_ 1424 TCU_AutoSarNMReserved4 1;
BA_ "U_P708_MY2023_Tx" SG_ 1424 TCU_AutoSarNMReserved4 1;
BA_ "U_CDX74X_MY2024_Tx" SG_ 1424 TCU_AutoSarNMReserved4 1;
BA_ "U_V710_MY2023_Tx" SG_ 1424 TCU_AutoSarNMReserved4 1;
BA_ "GenSigStartValue" SG_ 1424 TCU_AutoSarNMReserved3 255;
BA_ "U_V713N_MY2022_Tx" SG_ 1424 TCU_AutoSarNMReserved3 1;
BA_ "U_V713AV_MY2022_Tx" SG_ 1424 TCU_AutoSarNMReserved3 1;
BA_ "U_P708_MY2023_Tx" SG_ 1424 TCU_AutoSarNMReserved3 1;
BA_ "U_CDX74X_MY2024_Tx" SG_ 1424 TCU_AutoSarNMReserved3 1;
BA_ "U_V710_MY2023_Tx" SG_ 1424 TCU_AutoSarNMReserved3 1;
BA_ "GenSigStartValue" SG_ 1424 TCU_AutoSarNMReserved2 255;
BA_ "U_V713N_MY2022_Tx" SG_ 1424 TCU_AutoSarNMReserved2 1;
BA_ "U_V713AV_MY2022_Tx" SG_ 1424 TCU_AutoSarNMReserved2 1;
BA_ "U_P708_MY2023_Tx" SG_ 1424 TCU_AutoSarNMReserved2 1;
BA_ "U_CDX74X_MY2024_Tx" SG_ 1424 TCU_AutoSarNMReserved2 1;
BA_ "U_V710_MY2023_Tx" SG_ 1424 TCU_AutoSarNMReserved2 1;
BA_ "GenSigStartValue" SG_ 1424 TCU_AutoSarNMReserved1 255;
BA_ "U_V713N_MY2022_Tx" SG_ 1424 TCU_AutoSarNMReserved1 1;
BA_ "U_V713AV_MY2022_Tx" SG_ 1424 TCU_AutoSarNMReserved1 1;
BA_ "U_P708_MY2023_Tx" SG_ 1424 TCU_AutoSarNMReserved1 1;
BA_ "U_CDX74X_MY2024_Tx" SG_ 1424 TCU_AutoSarNMReserved1 1;
BA_ "U_V710_MY2023_Tx" SG_ 1424 TCU_AutoSarNMReserved1 1;
BA_ "GenSigStartValue" SG_ 1424 TCU_AutoSarNMNodeId 144;
BA_ "U_V713N_MY2022_Tx" SG_ 1424 TCU_AutoSarNMNodeId 1;
BA_ "U_V713AV_MY2022_Tx" SG_ 1424 TCU_AutoSarNMNodeId 1;
BA_ "U_P708_MY2023_Tx" SG_ 1424 TCU_AutoSarNMNodeId 1;
BA_ "U_CDX74X_MY2024_Tx" SG_ 1424 TCU_AutoSarNMNodeId 1;
BA_ "U_V710_MY2023_Tx" SG_ 1424 TCU_AutoSarNMNodeId 1;
BA_ "U_V713N_MY2022_Tx" SG_ 1424 TCU_AutoSarNMControl 1;
BA_ "U_V713AV_MY2022_Tx" SG_ 1424 TCU_AutoSarNMControl 1;
BA_ "U_P708_MY2023_Tx" SG_ 1424 TCU_AutoSarNMControl 1;
BA_ "U_CDX74X_MY2024_Tx" SG_ 1424 TCU_AutoSarNMControl 1;
BA_ "U_V710_MY2023_Tx" SG_ 1424 TCU_AutoSarNMControl 1;
BA_ "GenSigStartValue" SG_ 479 DISP_SetVolume_Rq 30;
BA_ "U_V713AV_MY2022_Rx" SG_ 479 DISP_SetVolume_Rq 1;
BA_ "U_P708_MY2023_Rx" SG_ 479 DISP_SetVolume_Rq 1;
BA_ "U_CDX74X_MY2024_Rx" SG_ 479 DISP_SetVolume_Rq 1;
BA_ "U_V710_MY2023_Rx" SG_ 479 DISP_SetVolume_Rq 1;
BA_ "GenSigStartValue" SG_ 765 BalrSwtch_D_Stat 1;
BA_ "GenSigStartValue" SG_ 765 WaitToStartLamp_D_Falt 1;
BA_ "GenSigStartValue" SG_ 765 EsaOn_B_Rq 1;
BA_ "GenSigStartValue" SG_ 765 Btt_L_Actl 126;
BA_ "GenSigStartValue" SG_ 765 RearDiffLck_D_RqArb 3;
BA_ "GenSigStartValue" SG_ 765 AwdMde_D_RqArb 5;
BA_ "WakeupSignal" SG_ 765 DrvInputRequired_B_Rq 1;
BA_ "GenSigStartValue" SG_ 765 EngExhMdeQuiet_D_Rq 2;
BA_ "U_V713N_MY2022_Rx" SG_ 765 Mc_VehLangUsrSel_St 1;
BA_ "U_V713AV_MY2022_Rx" SG_ 765 Mc_VehLangUsrSel_St 1;
BA_ "U_P708_MY2023_Rx" SG_ 765 Mc_VehLangUsrSel_St 1;
BA_ "U_CDX74X_MY2024_Rx" SG_ 765 Mc_VehLangUsrSel_St 1;
BA_ "U_V710_MY2023_Rx" SG_ 765 Mc_VehLangUsrSel_St 1;
BA_ "GenSigStartValue" SG_ 765 AwdRnge_D_ActlIpc 7;
BA_ "GenSigSendType" SG_ 739 SpeedChngChime_D_Rq 3;
BA_ "GenSigSendType" SG_ 739 LostPKChirp_D_RqMnu 3;
BA_ "ECGUsedRxSignal" SG_ 739 VgfSet_D_Stat 1;
BA_ "GenSigSendType" SG_ 739 VgfSet_D_Stat 3;
BA_ "GenSigStartValue" SG_ 739 OnbTrgtSocOvrrd_Pc_Rq 100;
BA_ "GenSigStartValue" SG_ 739 BptDly_T_RqMnu 62;
BA_ "GenSigStartValue" SG_ 739 BptMnSoc_L_RqMnu 8190;
BA_ "WakeupSignal" SG_ 739 HMI_HMIMode_St 1;
BA_ "U_V713N_MY2022_Rx" SG_ 739 HMI_HMIMode_St 1;
BA_ "U_V713AV_MY2022_Rx" SG_ 739 HMI_HMIMode_St 1;
BA_ "U_P708_MY2023_Rx" SG_ 739 HMI_HMIMode_St 1;
BA_ "U_CDX74X_MY2024_Rx" SG_ 739 HMI_HMIMode_St 1;
BA_ "U_V710_MY2023_Rx" SG_ 739 HMI_HMIMode_St 1;
BA_ "GenSigStartValue" SG_ 553 DistToChrgrBynd_L_Actl 510;
BA_ "U_V713N_MY2022_Rx" SG_ 553 Disp_LangSel2_St 1;
BA_ "U_V713AV_MY2022_Rx" SG_ 553 Disp_LangSel2_St 1;
BA_ "U_P708_MY2023_Rx" SG_ 553 Disp_LangSel2_St 1;
BA_ "U_CDX74X_MY2024_Rx" SG_ 553 Disp_LangSel2_St 1;
BA_ "U_V710_MY2023_Rx" SG_ 553 Disp_LangSel2_St 1;
BA_ "U_V713N_MY2022_Rx" SG_ 553 Disp_LangSel_St 1;
BA_ "U_V713AV_MY2022_Rx" SG_ 553 Disp_LangSel_St 1;
BA_ "U_P708_MY2023_Rx" SG_ 553 Disp_LangSel_St 1;
BA_ "U_CDX74X_MY2024_Rx" SG_ 553 Disp_LangSel_St 1;
BA_ "U_V710_MY2023_Rx" SG_ 553 Disp_LangSel_St 1;
BA_ "GenSigStartValue" SG_ 1072 HsaMde_D_Rq 1;
BA_ "WakeupSignal" SG_ 1072 Power_Liftgate_Mode_Cmd 1;
BA_ "GenSigStartValue" SG_ 1072 AccEnbl_B_RqDrv 1;
BA_ "U_V713N_MY2022_Rx" SG_ 1072 OdometerMasterValue 1;
BA_ "U_V713AV_MY2022_Rx" SG_ 1072 OdometerMasterValue 1;
BA_ "U_P708_MY2023_Rx" SG_ 1072 OdometerMasterValue 1;
BA_ "U_CDX74X_MY2024_Rx" SG_ 1072 OdometerMasterValue 1;
BA_ "U_V710_MY2023_Rx" SG_ 1072 OdometerMasterValue 1;
BA_ "WakeupSignal" SG_ 1072 ePRNDL_MODE 1;
BA_ "MetaData" SG_ 534 WhlRotatRr_No_Cnt 1;
BA_ "U_V713AV_MY2022_Rx" SG_ 534 WhlDirFl_D_Actl 1;
BA_ "U_P708_MY2023_Rx" SG_ 534 WhlDirFl_D_Actl 1;
BA_ "U_CDX74X_MY2024_Rx" SG_ 534 WhlDirFl_D_Actl 1;
BA_ "MetaData" SG_ 534 WhlRotatRl_No_Cnt 1;
BA_ "MetaData" SG_ 534 WhlRotatFr_No_Cnt 1;
BA_ "MetaData" SG_ 534 WhlRotatFl_No_Cnt 1;
BA_ "GenSigStartValue" SG_ 76 PsngrFmidDetct_D_Actl 3;
BA_ "U_P708_MY2023_Rx" SG_ 76 PsngrFmidDetct_D_Actl 1;
BA_ "U_CDX74X_MY2024_Rx" SG_ 76 PsngrFmidDetct_D_Actl 1;
BA_ "U_V710_MY2023_Rx" SG_ 76 PsngrFmidDetct_D_Actl 1;
BA_ "GenSigStartValue" SG_ 76 FirstRowBuckleMid 3;
BA_ "U_P708_MY2023_Rx" SG_ 76 FirstRowBuckleMid 1;
BA_ "U_CDX74X_MY2024_Rx" SG_ 76 FirstRowBuckleMid 1;
BA_ "U_V710_MY2023_Rx" SG_ 76 FirstRowBuckleMid 1;
BA_ "GenSigStartValue" SG_ 76 ThirdRowBucklePsngr 3;
BA_ "U_CDX74X_MY2024_Rx" SG_ 76 ThirdRowBucklePsngr 1;
BA_ "U_V710_MY2023_Rx" SG_ 76 ThirdRowBucklePsngr 1;
BA_ "GenSigStartValue" SG_ 76 ThirdRowBuckleMid 3;
BA_ "U_CDX74X_MY2024_Rx" SG_ 76 ThirdRowBuckleMid 1;
BA_ "U_V710_MY2023_Rx" SG_ 76 ThirdRowBuckleMid 1;
BA_ "GenSigStartValue" SG_ 76 ThirdRowBuckleDriver 3;
BA_ "U_CDX74X_MY2024_Rx" SG_ 76 ThirdRowBuckleDriver 1;
BA_ "U_V710_MY2023_Rx" SG_ 76 ThirdRowBuckleDriver 1;
BA_ "GenSigStartValue" SG_ 76 SecondRowBucklePsngr 3;
BA_ "U_P708_MY2023_Rx" SG_ 76 SecondRowBucklePsngr 1;
BA_ "U_CDX74X_MY2024_Rx" SG_ 76 SecondRowBucklePsngr 1;
BA_ "U_V710_MY2023_Rx" SG_ 76 SecondRowBucklePsngr 1;
BA_ "GenSigStartValue" SG_ 76 SecondRowBuckleMid 3;
BA_ "U_P708_MY2023_Rx" SG_ 76 SecondRowBuckleMid 1;
BA_ "U_CDX74X_MY2024_Rx" SG_ 76 SecondRowBuckleMid 1;
BA_ "U_V710_MY2023_Rx" SG_ 76 SecondRowBuckleMid 1;
BA_ "GenSigStartValue" SG_ 76 SecondRowBuckleDriver 3;
BA_ "U_P708_MY2023_Rx" SG_ 76 SecondRowBuckleDriver 1;
BA_ "U_CDX74X_MY2024_Rx" SG_ 76 SecondRowBuckleDriver 1;
BA_ "U_V710_MY2023_Rx" SG_ 76 SecondRowBuckleDriver 1;
BA_ "GenSigStartValue" SG_ 76 FirstRowBuckleDriver 3;
BA_ "U_P708_MY2023_Rx" SG_ 76 FirstRowBuckleDriver 1;
BA_ "U_CDX74X_MY2024_Rx" SG_ 76 FirstRowBuckleDriver 1;
BA_ "U_V710_MY2023_Rx" SG_ 76 FirstRowBuckleDriver 1;
BA_ "GenSigStartValue" SG_ 76 FirstRowBucklePsngr 3;
BA_ "U_P708_MY2023_Rx" SG_ 76 FirstRowBucklePsngr 1;
BA_ "U_CDX74X_MY2024_Rx" SG_ 76 FirstRowBucklePsngr 1;
BA_ "U_V710_MY2023_Rx" SG_ 76 FirstRowBucklePsngr 1;
BA_ "WakeupSignal" SG_ 76 RstrnImpactEvntStatus 1;
BA_ "U_V713AV_MY2022_Rx" SG_ 76 RstrnImpactEvntStatus 1;
BA_ "U_P708_MY2023_Rx" SG_ 76 RstrnImpactEvntStatus 1;
BA_ "U_CDX74X_MY2024_Rx" SG_ 76 RstrnImpactEvntStatus 1;
BA_ "U_V710_MY2023_Rx" SG_ 76 RstrnImpactEvntStatus 1;
BA_ "GenSigStartValue" SG_ 76 PsngrFrntDetct_D_Actl 3;
BA_ "U_P708_MY2023_Rx" SG_ 76 PsngrFrntDetct_D_Actl 1;
BA_ "U_CDX74X_MY2024_Rx" SG_ 76 PsngrFrntDetct_D_Actl 1;
BA_ "U_V710_MY2023_Rx" SG_ 76 PsngrFrntDetct_D_Actl 1;
BA_ "U_V713AV_MY2022_Rx" SG_ 76 EDRTriggerEvntSync 1;
BA_ "U_P708_MY2023_Rx" SG_ 76 EDRTriggerEvntSync 1;
BA_ "U_CDX74X_MY2024_Rx" SG_ 76 EDRTriggerEvntSync 1;
BA_ "U_V710_MY2023_Rx" SG_ 76 EDRTriggerEvntSync 1;
BA_ "GenSigStartValue" SG_ 76 PassRstrnInd_Req 3;
BA_ "MetaData" SG_ 76 FirstRowBuckle_No_Cs 1;
BA_ "MetaData" SG_ 76 RCMStatusMsg2_No_Cnt 1;
BA_ "ECGUsedRxSignal" SG_ 694 RFA_BLEM_ECG_Word_Tx 1;
BA_ "U_V713N_MY2022_Rx" SG_ 694 RFA_BLEM_ECG_Word_Tx 1;
BA_ "U_V713AV_MY2022_Rx" SG_ 694 RFA_BLEM_ECG_Word_Tx 1;
BA_ "U_CDX74X_MY2024_Rx" SG_ 694 RFA_BLEM_ECG_Word_Tx 1;
BA_ "U_V713AV_MY2022_Tx" SG_ 694 RFA_BLEM_ECG_Word_Tx 1;
BA_ "GenSigSendType" SG_ 1745 TesterPhysicalReqUCIM 3;
BA_ "GenSigStartValue" SG_ 1438 GWM_GWOnBoardTester 255;
BA_ "U_V713N_MY2022_Rx" SG_ 1438 GWM_GWOnBoardTester 1;
BA_ "U_V713AV_MY2022_Rx" SG_ 1438 GWM_GWOnBoardTester 1;
BA_ "U_P708_MY2023_Rx" SG_ 1438 GWM_GWOnBoardTester 1;
BA_ "U_CDX74X_MY2024_Rx" SG_ 1438 GWM_GWOnBoardTester 1;
BA_ "U_V710_MY2023_Rx" SG_ 1438 GWM_GWOnBoardTester 1;
BA_ "ECGUsedTxSignal" SG_ 1438 GWM_GWOnBoardTester 1;
BA_ "U_V713N_MY2022_Tx" SG_ 1438 GWM_GWOnBoardTester 1;
BA_ "U_V713AV_MY2022_Tx" SG_ 1438 GWM_GWOnBoardTester 1;
BA_ "U_P708_MY2023_Tx" SG_ 1438 GWM_GWOnBoardTester 1;
BA_ "U_CDX74X_MY2024_Tx" SG_ 1438 GWM_GWOnBoardTester 1;
BA_ "U_V710_MY2023_Tx" SG_ 1438 GWM_GWOnBoardTester 1;
BA_ "GenSigStartValue" SG_ 1438 GWM_GWNMProxy 255;
BA_ "U_V713N_MY2022_Rx" SG_ 1438 GWM_GWNMProxy 1;
BA_ "U_V713AV_MY2022_Rx" SG_ 1438 GWM_GWNMProxy 1;
BA_ "U_P708_MY2023_Rx" SG_ 1438 GWM_GWNMProxy 1;
BA_ "U_CDX74X_MY2024_Rx" SG_ 1438 GWM_GWNMProxy 1;
BA_ "U_V710_MY2023_Rx" SG_ 1438 GWM_GWNMProxy 1;
BA_ "ECGUsedTxSignal" SG_ 1438 GWM_GWNMProxy 1;
BA_ "U_V713N_MY2022_Tx" SG_ 1438 GWM_GWNMProxy 1;
BA_ "U_V713AV_MY2022_Tx" SG_ 1438 GWM_GWNMProxy 1;
BA_ "U_P708_MY2023_Tx" SG_ 1438 GWM_GWNMProxy 1;
BA_ "U_CDX74X_MY2024_Tx" SG_ 1438 GWM_GWNMProxy 1;
BA_ "U_V710_MY2023_Tx" SG_ 1438 GWM_GWNMProxy 1;
BA_ "GenSigStartValue" SG_ 1438 GWM_AutoSarNMReserved4 255;
BA_ "U_V713N_MY2022_Rx" SG_ 1438 GWM_AutoSarNMReserved4 1;
BA_ "U_V713AV_MY2022_Rx" SG_ 1438 GWM_AutoSarNMReserved4 1;
BA_ "U_P708_MY2023_Rx" SG_ 1438 GWM_AutoSarNMReserved4 1;
BA_ "U_CDX74X_MY2024_Rx" SG_ 1438 GWM_AutoSarNMReserved4 1;
BA_ "U_V710_MY2023_Rx" SG_ 1438 GWM_AutoSarNMReserved4 1;
BA_ "ECGUsedTxSignal" SG_ 1438 GWM_AutoSarNMReserved4 1;
BA_ "U_V713N_MY2022_Tx" SG_ 1438 GWM_AutoSarNMReserved4 1;
BA_ "U_V713AV_MY2022_Tx" SG_ 1438 GWM_AutoSarNMReserved4 1;
BA_ "U_P708_MY2023_Tx" SG_ 1438 GWM_AutoSarNMReserved4 1;
BA_ "U_CDX74X_MY2024_Tx" SG_ 1438 GWM_AutoSarNMReserved4 1;
BA_ "U_V710_MY2023_Tx" SG_ 1438 GWM_AutoSarNMReserved4 1;
BA_ "GenSigStartValue" SG_ 1438 GWM_AutoSarNMReserved3 255;
BA_ "U_V713N_MY2022_Rx" SG_ 1438 GWM_AutoSarNMReserved3 1;
BA_ "U_V713AV_MY2022_Rx" SG_ 1438 GWM_AutoSarNMReserved3 1;
BA_ "U_P708_MY2023_Rx" SG_ 1438 GWM_AutoSarNMReserved3 1;
BA_ "U_CDX74X_MY2024_Rx" SG_ 1438 GWM_AutoSarNMReserved3 1;
BA_ "U_V710_MY2023_Rx" SG_ 1438 GWM_AutoSarNMReserved3 1;
BA_ "ECGUsedTxSignal" SG_ 1438 GWM_AutoSarNMReserved3 1;
BA_ "U_V713N_MY2022_Tx" SG_ 1438 GWM_AutoSarNMReserved3 1;
BA_ "U_V713AV_MY2022_Tx" SG_ 1438 GWM_AutoSarNMReserved3 1;
BA_ "U_P708_MY2023_Tx" SG_ 1438 GWM_AutoSarNMReserved3 1;
BA_ "U_CDX74X_MY2024_Tx" SG_ 1438 GWM_AutoSarNMReserved3 1;
BA_ "U_V710_MY2023_Tx" SG_ 1438 GWM_AutoSarNMReserved3 1;
BA_ "GenSigStartValue" SG_ 1438 GWM_AutoSarNMReserved2 255;
BA_ "U_V713N_MY2022_Rx" SG_ 1438 GWM_AutoSarNMReserved2 1;
BA_ "U_V713AV_MY2022_Rx" SG_ 1438 GWM_AutoSarNMReserved2 1;
BA_ "U_P708_MY2023_Rx" SG_ 1438 GWM_AutoSarNMReserved2 1;
BA_ "U_CDX74X_MY2024_Rx" SG_ 1438 GWM_AutoSarNMReserved2 1;
BA_ "U_V710_MY2023_Rx" SG_ 1438 GWM_AutoSarNMReserved2 1;
BA_ "ECGUsedTxSignal" SG_ 1438 GWM_AutoSarNMReserved2 1;
BA_ "U_V713N_MY2022_Tx" SG_ 1438 GWM_AutoSarNMReserved2 1;
BA_ "U_V713AV_MY2022_Tx" SG_ 1438 GWM_AutoSarNMReserved2 1;
BA_ "U_P708_MY2023_Tx" SG_ 1438 GWM_AutoSarNMReserved2 1;
BA_ "U_CDX74X_MY2024_Tx" SG_ 1438 GWM_AutoSarNMReserved2 1;
BA_ "U_V710_MY2023_Tx" SG_ 1438 GWM_AutoSarNMReserved2 1;
BA_ "GenSigStartValue" SG_ 1438 GWM_AutoSarNMReserved1 255;
BA_ "U_V713N_MY2022_Rx" SG_ 1438 GWM_AutoSarNMReserved1 1;
BA_ "U_V713AV_MY2022_Rx" SG_ 1438 GWM_AutoSarNMReserved1 1;
BA_ "U_P708_MY2023_Rx" SG_ 1438 GWM_AutoSarNMReserved1 1;
BA_ "U_CDX74X_MY2024_Rx" SG_ 1438 GWM_AutoSarNMReserved1 1;
BA_ "U_V710_MY2023_Rx" SG_ 1438 GWM_AutoSarNMReserved1 1;
BA_ "ECGUsedTxSignal" SG_ 1438 GWM_AutoSarNMReserved1 1;
BA_ "U_V713N_MY2022_Tx" SG_ 1438 GWM_AutoSarNMReserved1 1;
BA_ "U_V713AV_MY2022_Tx" SG_ 1438 GWM_AutoSarNMReserved1 1;
BA_ "U_P708_MY2023_Tx" SG_ 1438 GWM_AutoSarNMReserved1 1;
BA_ "U_CDX74X_MY2024_Tx" SG_ 1438 GWM_AutoSarNMReserved1 1;
BA_ "U_V710_MY2023_Tx" SG_ 1438 GWM_AutoSarNMReserved1 1;
BA_ "GenSigStartValue" SG_ 1438 GWM_AutoSarNMNodeId 158;
BA_ "U_V713N_MY2022_Rx" SG_ 1438 GWM_AutoSarNMNodeId 1;
BA_ "U_V713AV_MY2022_Rx" SG_ 1438 GWM_AutoSarNMNodeId 1;
BA_ "U_P708_MY2023_Rx" SG_ 1438 GWM_AutoSarNMNodeId 1;
BA_ "U_CDX74X_MY2024_Rx" SG_ 1438 GWM_AutoSarNMNodeId 1;
BA_ "U_V710_MY2023_Rx" SG_ 1438 GWM_AutoSarNMNodeId 1;
BA_ "ECGUsedTxSignal" SG_ 1438 GWM_AutoSarNMNodeId 1;
BA_ "U_V713N_MY2022_Tx" SG_ 1438 GWM_AutoSarNMNodeId 1;
BA_ "U_V713AV_MY2022_Tx" SG_ 1438 GWM_AutoSarNMNodeId 1;
BA_ "U_P708_MY2023_Tx" SG_ 1438 GWM_AutoSarNMNodeId 1;
BA_ "U_CDX74X_MY2024_Tx" SG_ 1438 GWM_AutoSarNMNodeId 1;
BA_ "U_V710_MY2023_Tx" SG_ 1438 GWM_AutoSarNMNodeId 1;
BA_ "U_V713N_MY2022_Rx" SG_ 1438 GWM_AutoSarNMControl 1;
BA_ "U_V713AV_MY2022_Rx" SG_ 1438 GWM_AutoSarNMControl 1;
BA_ "U_P708_MY2023_Rx" SG_ 1438 GWM_AutoSarNMControl 1;
BA_ "U_CDX74X_MY2024_Rx" SG_ 1438 GWM_AutoSarNMControl 1;
BA_ "U_V710_MY2023_Rx" SG_ 1438 GWM_AutoSarNMControl 1;
BA_ "ECGUsedTxSignal" SG_ 1438 GWM_AutoSarNMControl 1;
BA_ "U_V713N_MY2022_Tx" SG_ 1438 GWM_AutoSarNMControl 1;
BA_ "U_V713AV_MY2022_Tx" SG_ 1438 GWM_AutoSarNMControl 1;
BA_ "U_P708_MY2023_Tx" SG_ 1438 GWM_AutoSarNMControl 1;
BA_ "U_CDX74X_MY2024_Tx" SG_ 1438 GWM_AutoSarNMControl 1;
BA_ "U_V710_MY2023_Tx" SG_ 1438 GWM_AutoSarNMControl 1;
BA_ "GenSigSendType" SG_ 1814 TesterPhysicalReqGWM_F2 3;
BA_ "ECGUsedRxSignal" SG_ 1814 TesterPhysicalReqGWM_F2 1;
BA_ "U_V713N_MY2022_Rx" SG_ 1814 TesterPhysicalReqGWM_F2 1;
BA_ "U_V713AV_MY2022_Rx" SG_ 1814 TesterPhysicalReqGWM_F2 1;
BA_ "U_P708_MY2023_Rx" SG_ 1814 TesterPhysicalReqGWM_F2 1;
BA_ "U_CDX74X_MY2024_Rx" SG_ 1814 TesterPhysicalReqGWM_F2 1;
BA_ "U_V710_MY2023_Rx" SG_ 1814 TesterPhysicalReqGWM_F2 1;
BA_ "GenSigSendType" SG_ 1822 TesterPhysicalResGWM_F2 3;
BA_ "ECGUsedTxSignal" SG_ 1822 TesterPhysicalResGWM_F2 1;
BA_ "U_V713N_MY2022_Tx" SG_ 1822 TesterPhysicalResGWM_F2 1;
BA_ "U_V713AV_MY2022_Tx" SG_ 1822 TesterPhysicalResGWM_F2 1;
BA_ "U_P708_MY2023_Tx" SG_ 1822 TesterPhysicalResGWM_F2 1;
BA_ "U_CDX74X_MY2024_Tx" SG_ 1822 TesterPhysicalResGWM_F2 1;
BA_ "U_V710_MY2023_Tx" SG_ 1822 TesterPhysicalResGWM_F2 1;
BA_ "U_V713N_MY2022_Rx" SG_ 1085 PwSrcULoFalt_D_Stat 1;
BA_ "U_V713AV_MY2022_Rx" SG_ 1085 PwSrcULoFalt_D_Stat 1;
BA_ "U_P708_MY2023_Rx" SG_ 1085 PwSrcULoFalt_D_Stat 1;
BA_ "U_CDX74X_MY2024_Rx" SG_ 1085 PwSrcULoFalt_D_Stat 1;
BA_ "U_V710_MY2023_Rx" SG_ 1085 PwSrcULoFalt_D_Stat 1;
BA_ "MetaData" SG_ 514 VehVActlEng_No_Cs 1;
BA_ "MetaData" SG_ 514 VehVActlEng_No_Cnt 1;
BA_ "MetaData" SG_ 514 VehVActlEng_D_Qf 1;
BA_ "U_P708_MY2023_Rx" SG_ 514 VehVActlEng_D_Qf 1;
BA_ "U_CDX74X_MY2024_Rx" SG_ 514 VehVActlEng_D_Qf 1;
BA_ "U_V713N_MY2022_Rx" SG_ 514 Veh_V_ActlEng 1;
BA_ "U_V713AV_MY2022_Rx" SG_ 514 Veh_V_ActlEng 1;
BA_ "U_P708_MY2023_Rx" SG_ 514 Veh_V_ActlEng 1;
BA_ "U_CDX74X_MY2024_Rx" SG_ 514 Veh_V_ActlEng 1;
BA_ "U_V710_MY2023_Rx" SG_ 514 Veh_V_ActlEng 1;
BA_ "GenSigStartValue" SG_ 514 GearRvrse_D_Actl 7;
BA_ "U_V713N_MY2022_Rx" SG_ 514 GearRvrse_D_Actl 1;
BA_ "U_V713AV_MY2022_Rx" SG_ 514 GearRvrse_D_Actl 1;
BA_ "U_P708_MY2023_Rx" SG_ 514 GearRvrse_D_Actl 1;
BA_ "U_CDX74X_MY2024_Rx" SG_ 514 GearRvrse_D_Actl 1;
BA_ "U_V710_MY2023_Rx" SG_ 514 GearRvrse_D_Actl 1;
BA_ "MetaData" SG_ 560 GearLvrPosActl_No_Cs 1;
BA_ "MetaData" SG_ 560 GearLvrPosActl_No_Cnt 1;
BA_ "GenSigStartValue" SG_ 560 GearLvrPos_D_Actl 14;
BA_ "U_V713N_MY2022_Rx" SG_ 560 GearLvrPos_D_Actl 1;
BA_ "U_V713AV_MY2022_Rx" SG_ 560 GearLvrPos_D_Actl 1;
BA_ "U_V710_MY2023_Rx" SG_ 560 GearLvrPos_D_Actl 1;
BA_ "GenSigStartValue" SG_ 560 GboxOil_Te_Actl 254;
BA_ "WakeupSignal" SG_ 817 DrTgateOpen_B_Rq 1;
BA_ "WakeupSignal" SG_ 817 DrTgateExtSwMde_B_Stat 1;
BA_ "WakeupSignal" SG_ 817 Remote_Device_Feedback 1;
BA_ "WakeupSignal" SG_ 817 Veh_Lock_Requestor 1;
BA_ "U_V713AV_MY2022_Rx" SG_ 817 Veh_Lock_Requestor 1;
BA_ "U_CDX74X_MY2024_Rx" SG_ 817 Veh_Lock_Requestor 1;
BA_ "WakeupSignal" SG_ 817 R_Pwr_Sliding_Dr_Rqst 1;
BA_ "WakeupSignal" SG_ 817 Power_Liftgate_Rqst 1;
BA_ "WakeupSignal" SG_ 817 Veh_Lock_EvNum 1;
BA_ "U_V713AV_MY2022_Rx" SG_ 817 Veh_Lock_EvNum 1;
BA_ "WakeupSignal" SG_ 817 Power_Decklid_Rqst 1;
BA_ "WakeupSignal" SG_ 817 L_Pwr_Sliding_Dr_Rqst 1;
BA_ "WakeupSignal" SG_ 817 Keyfob_Pad_Msg_Count 1;
BA_ "MetaData" SG_ 817 Keyfob_Pad_Msg_Count 1;
BA_ "WakeupSignal" SG_ 817 Veh_Lock_Status 1;
BA_ "GenSigStartValue" SG_ 817 Veh_Lock_Status 1;
BA_ "U_V713AV_MY2022_Rx" SG_ 817 Veh_Lock_Status 1;
BA_ "U_CDX74X_MY2024_Rx" SG_ 817 Veh_Lock_Status 1;
BA_ "WakeupSignal" SG_ 817 Lockmsgtxt_D_Rq 1;
BA_ "WakeupSignal" SG_ 817 LockInhibit 1;
BA_ "GenSigStartValue" SG_ 1084 BattULoChrg_URate_RqMx 5;
BA_ "GenSigStartValue" SG_ 1084 BattULoChrg_U_RqMx 34;
BA_ "GenSigStartValue" SG_ 1084 BattULo2_Te_Actl 127;
BA_ "U_V713AV_MY2022_Rx" SG_ 1084 BSBattSOC 1;
BA_ "WakeupSignal" SG_ 1068 PwSysULoFalt_D_Stat 1;
BA_ "WakeupSignal" SG_ 1068 Shed_Feature_Group_ID 1;
BA_ "WakeupSignal" SG_ 1068 Shed_Level_Req 1;
BA_ "U_V713AV_MY2022_Rx" SG_ 1068 Batt_Lo_SoC_B 1;
BA_ "GenSigStartValue" SG_ 1144 BattChrgInhbt_D2_Rq 1;
BA_ "WakeupSignal" SG_ 1144 CabnEvapSovFront_B_Rq 1;
BA_ "WakeupSignal" SG_ 1144 HeatCoreSovRear_B_Rq 1;
BA_ "WakeupSignal" SG_ 1144 BattChlrSov_B_Rq 1;
BA_ "WakeupSignal" SG_ 1144 CabnEvapSovRear_B_Rq 1;
BA_ "GenSigStartValue" SG_ 1144 WakeAlarm0_T_Rq 32767;
BA_ "U_V713AV_MY2022_Rx" SG_ 1144 FstChrgCmplt_T_Est 1;
BA_ "GenSigSendType" SG_ 2015 TesterFunctionalReq 3;
BA_ "ECGUsedRxSignal" SG_ 2015 TesterFunctionalReq 1;
BA_ "U_V713N_MY2022_Rx" SG_ 2015 TesterFunctionalReq 1;
BA_ "U_V713AV_MY2022_Rx" SG_ 2015 TesterFunctionalReq 1;
BA_ "U_P708_MY2023_Rx" SG_ 2015 TesterFunctionalReq 1;
BA_ "U_CDX74X_MY2024_Rx" SG_ 2015 TesterFunctionalReq 1;
BA_ "U_V710_MY2023_Rx" SG_ 2015 TesterFunctionalReq 1;
BA_ "U_V713N_MY2022_Rx" SG_ 1034 VehicleGGCCData 1;
BA_ "U_V713AV_MY2022_Rx" SG_ 1034 VehicleGGCCData 1;
BA_ "U_P708_MY2023_Rx" SG_ 1034 VehicleGGCCData 1;
BA_ "U_CDX74X_MY2024_Rx" SG_ 1034 VehicleGGCCData 1;
BA_ "U_V710_MY2023_Rx" SG_ 1034 VehicleGGCCData 1;
BA_ "GenSigStartValue" SG_ 1200 BrkBstrVac_P_Actl 127;
BA_ "U_P708_MY2023_Rx" SG_ 1200 BrkTot_Tq_RqDrv 1;
BA_ "U_CDX74X_MY2024_Rx" SG_ 1200 BrkTot_Tq_RqDrv 1;
BA_ "MetaData" SG_ 1200 BrkTotTqRqDrv_No_Cnt 1;
BA_ "MetaData" SG_ 1200 BrkTotTqRqDrv_No_Cs 1;
BA_ "U_V713AV_MY2022_Rx" SG_ 1200 BrkHold_D_Stat 1;
BA_REL_ "SC_Verification" BU_SG_REL_ RFA_BLEM SG_ 531 TracCtlPtActv_B_Actl 1;
BA_REL_ "SC_Verification" BU_SG_REL_ RFA_BLEM SG_ 531 StabCtlBrkActv_B_Actl 1;
BA_REL_ "SC_Verification" BU_SG_REL_ RFA_BLEM SG_ 894 RmtCtlTrgtBody_D_Stat 1;
BA_REL_ "SC_Verification" BU_SG_REL_ RFA_BLEM SG_ 894 RmtCtlTrgt_D_Rq 1;
BA_REL_ "SC_Verification" BU_SG_REL_ RFA_BLEM SG_ 894 RmtCtlRngSet_D_Stat 1;
BA_REL_ "SC_Verification" BU_SG_REL_ RFA_BLEM SG_ 894 RmtCtlKeySrch_D_Stat 1;
BA_REL_ "SC_Verification" BU_SG_REL_ RFA_BLEM SG_ 894 RmtCtlBody_D_Stat 1;
BA_REL_ "SC_Verification" BU_SG_REL_ RFA_BLEM SG_ 894 RmtCtl_D_RqBody 1;
BA_REL_ "SC_Verification" BU_SG_REL_ RFA_BLEM SG_ 359 PwPckTq_D_Stat 1;
BA_REL_ "SC_Verification" BU_SG_REL_ RFA_BLEM SG_ 514 Veh_V_ActlEng 1;
BA_REL_ "SC_Verification" BU_SG_REL_ RFA_BLEM SG_ 817 Veh_Lock_Requestor 1;
BA_REL_ "SC_Verification" BU_SG_REL_ RFA_BLEM SG_ 817 Veh_Lock_EvNum 1;
BA_REL_ "SC_Verification" BU_SG_REL_ RFA_BLEM SG_ 817 Veh_Lock_Status 1;
BA_REL_ "SC_Verification" BU_SG_REL_ RFA_BLEM SG_ 1200 BrkTotTqRqDrv_No_Cnt 1;
BA_REL_ "SC_Verification" BU_SG_REL_ RFA_BLEM SG_ 1200 BrkHold_D_Stat 1;
VAL_ 1054 SelDrvMdeChassis3_D_Rq 31 "Faulty" 30 "NotUsed17" 29 "NotUsed16" 28 "NotUsed15" 27 "NotUsed14" 26 "NotUsed13" 25 "NotUsed12" 24 "NotUsed11" 23 "NotUsed10" 22 "NotUsed9" 21 "NotUsed8" 20 "NotUsed7" 19 "NotUsed6" 18 "NotUsed5" 17 "NotUsed4" 16 "OnePedalDrive" 15 "DragMode" 14 "RoughRoadMode" 13 "TrackMode" 12 "HighSpeedDesertMode" 11 "TowHaulMode" 10 "RockCrawlMode" 9 "SandMode" 8 "MudAndRutsMode" 7 "LowMuMode" 6 "ComfortAdaptiveMode" 5 "ComfortMode" 4 "SportAdaptiveMode" 3 "SportMode" 2 "EconomyMode" 1 "NormalAdaptiveMode" 0 "NormalMode" ;
VAL_ 1054 RbaBrk_D_Stat 3 "Denied" 2 "Active" 1 "Open" 0 "Closed" ;
VAL_ 1054 SelDrvMdeChassis2_D_Rq 31 "Faulty" 30 "NotUsed17" 29 "NotUsed16" 28 "NotUsed15" 27 "NotUsed14" 26 "NotUsed13" 25 "NotUsed12" 24 "NotUsed11" 23 "NotUsed10" 22 "NotUsed9" 21 "NotUsed8" 20 "NotUsed7" 19 "NotUsed6" 18 "NotUsed5" 17 "NotUsed4" 16 "OnePedalDrive" 15 "DragMode" 14 "RoughRoadMode" 13 "TrackMode" 12 "HighSpeedDesertMode" 11 "TowHaulMode" 10 "RockCrawlMode" 9 "SandMode" 8 "MudAndRutsMode" 7 "LowMuMode" 6 "ComfortAdaptiveMode" 5 "ComfortMode" 4 "SportAdaptiveMode" 3 "SportMode" 2 "EconomyMode" 1 "NormalAdaptiveMode" 0 "NormalMode" ;
VAL_ 1054 BrkBstrLoLampOn_B_Rq 1 "On" 0 "Off" ;
VAL_ 1054 TrailCtl_D_Stat 7 "Faulty" 6 "DescentOnly" 5 "EnabledDeny" 4 "StandbyOverThreshold" 3 "StandbyOverride" 2 "Active" 1 "EnabledDescent" 0 "Off" ;
VAL_ 1054 TrailCtlMsgTxt_D_Rq 15 "Message15" 14 "Message14" 13 "Message13" 12 "Message12" 11 "Message11" 10 "Message10" 9 "Message9" 8 "Message8" 7 "Message7" 6 "Message6" 5 "Message5" 4 "Message4" 3 "Message3" 2 "Message2" 1 "Message1" 0 "NoMessage" ;
VAL_ 1054 BrkPadMsgTxt_D_Rq 3 "Faulty" 2 "PadsOk" 1 "ReplacePads" 0 "Null" ;
VAL_ 1054 BrkBstrVac_D_Stat 3 "NotUsed" 2 "BoosterVacEstimator" 1 "BoosterVacSensor" 0 "NoBoosterVacuumMonitor" ;
VAL_ 1054 DrvSlipCtlOffLamp_D_Rq 3 "Fast_Flash" 2 "Slow_Flash" 1 "On" 0 "Off" ;
VAL_ 1054 DrvSlipCtlMdeMsg_D_Rq 31 "Message31" 30 "Message30" 29 "Message29" 28 "Message28" 27 "Message27" 26 "Message26" 25 "Message25" 24 "Message24" 23 "Message23" 22 "Message22" 21 "Message21" 20 "Message20" 19 "Message19" 18 "Message18" 17 "Message17" 16 "Message16" 15 "Message15" 14 "Message14" 13 "Message13" 12 "Message12" 11 "Message11" 10 "Message10" 9 "Message9" 8 "Message8" 7 "Message7" 6 "Message6" 5 "Message5" 4 "Message4" 3 "Message3" 2 "Message2" 1 "Message1" 0 "NoMessage" ;
VAL_ 1054 HdcOn_B_Ind 1 "On" 0 "Off" ;
VAL_ 1054 AutoHoldMsgTxt_D_Rq 15 "Message15" 14 "Message14" 13 "Message13" 12 "Message12" 11 "Message11" 10 "Message10" 9 "Message9" 8 "Message8" 7 "Message7" 6 "Message6" 5 "Message5" 4 "Message4" 3 "Message3" 2 "Message2" 1 "Message1" 0 "NoMessage" ;
VAL_ 1054 CtaBrk_D_Stat 3 "Denied" 2 "Active" 1 "Open" 0 "Closed" ;
VAL_ 1054 SelDrvMdeAwd_D_Rq 31 "Faulty" 30 "NotUsed_17" 29 "NotUsed_16" 28 "NotUsed_15" 27 "NotUsed_14" 26 "NotUsed_13" 25 "NotUsed_12" 24 "NotUsed_11" 23 "NotUsed_10" 22 "NotUsed_9" 21 "NotUsed_8" 20 "CustomMode" 19 "OnePedalDrive" 18 "DragMode" 17 "EvLaterChargeMode" 16 "EvNowMode" 15 "TrackMode" 14 "RoughRoadMode" 13 "NotAvailable" 12 "HighSpeedDesertMode_Baja" 11 "SportAdaptiveMode" 10 "RockCrawlMode" 9 "MudRutsMode" 8 "SandMode" 7 "EconomyMode" 6 "GrassGravelSnow" 5 "TowHaulMode" 4 "SportMode" 3 "Normal_4L" 2 "Normal_4A" 1 "Normal_2H" 0 "NormalMode" ;
VAL_ 1054 AutoHoldSwMde_B_Ind 1 "On" 0 "Off" ;
VAL_ 1054 AutoHoldMde_D_Ind 3 "Indication_3" 2 "Indication_2" 1 "Indication_1" 0 "Off" ;
VAL_ 1054 BrkMdeInhbt_B_RqDsply 1 "Yes" 0 "No" ;
VAL_ 1054 BrkLineLck_D_Stat 7 "NotUsed_3" 6 "NotUsed_2" 5 "NotUsed_1" 4 "NotAvailable" 3 "Off" 2 "Engaged" 1 "Initiated" 0 "Available" ;
VAL_ 1054 SelDrvMdeChassis_D_Rq 31 "Faulty" 30 "NotUsed17" 29 "NotUsed16" 28 "NotUsed15" 27 "NotUsed14" 26 "NotUsed13" 25 "NotUsed12" 24 "NotUsed11" 23 "NotUsed10" 22 "NotUsed9" 21 "NotUsed8" 20 "NotUsed7" 19 "NotUsed6" 18 "NotUsed5" 17 "NotUsed4" 16 "OnePedalDrive" 15 "DragMode" 14 "RoughRoadMode" 13 "TrackMode" 12 "HighSpeedDesertMode" 11 "TowHaulMode" 10 "RockCrawlMode" 9 "SandMode" 8 "MudAndRutsMode" 7 "LowMuMode" 6 "ComfortAdaptiveMode" 5 "ComfortMode" 4 "SportAdaptiveMode" 3 "SportMode" 2 "EconomyMode" 1 "NormalAdaptiveMode" 0 "NormalMode" ;
VAL_ 1054 ApaBrk_D_Stat 3 "Denied" 2 "Active" 1 "Open" 0 "Closed" ;
VAL_ 1054 FrontDiffElckrOpen_B_Rq 1 "Yes" 0 "No" ;
VAL_ 1054 OnePdlDrvDeny_B_Stat 1 "Yes" 0 "No" ;
VAL_ 1054 BrkDrvMde_D_Stat 7 "Faulty" 6 "RockCrawl" 5 "Baja" 4 "DragOrMudAndSand" 3 "Track" 2 "Snow_Wet" 1 "Sport" 0 "Normal" ;
VAL_ 1054 TrailOnePdlTqLm_B_Actl 1 "Yes" 0 "No" ;
VAL_ 931 VehOnSrc_D_Stat 15 "NotUsed_11" 14 "NotUsed_10" 13 "NotUsed_9" 12 "NotUsed_8" 11 "NotUsed_7" 10 "NotUsed_6" 9 "EsclRssd" 8 "AutonomousVehicle" 7 "SecureIdle" 6 "FleetVehicleInhibit" 5 "StolenVehicleInhibit" 4 "OverTheAir" 3 "RemoteParkAssist" 2 "RemoteStart" 1 "Manual" 0 "Off" ;
VAL_ 931 EngStrtActv_B_Stat 1 "Active" 0 "Inactive" ;
VAL_ 931 EngStrt_B_Rq 1 "Request" 0 "NoRequest" ;
VAL_ 931 DrvInCtl_B_Stat 1 "Yes" 0 "No" ;
VAL_ 931 PtWakeReas_D_Stat 15 "NotUsed_9" 14 "NotUsed_8" 13 "NotUsed_7" 12 "NotUsed_6" 11 "NotUsed_5" 10 "NotUsed_4" 9 "NotUsed_3" 8 "NotUsed_2" 7 "NotUsed_1" 6 "ElapsedTime" 5 "ThirdPartyWakeup" 4 "DoorAjar" 3 "EarlyWake" 2 "NonMotiveStart" 1 "MotiveStart" 0 "Null" ;
VAL_ 931 CrnkInhbt_B_Stat 1 "Inhibit" 0 "NoInhibit" ;
VAL_ 931 IgnPreOffActv_B_Stat 1 "Active" 0 "Inactive" ;
VAL_ 130 TrlrHitchLamp_D_Rqst 1 "On" 0 "Off" ;
VAL_ 130 VehVTrlrAid_B_Rq 1 "Request" 0 "NoRequest" ;
VAL_ 130 SteEffort_D_Stat 7 "NotUsed_3" 6 "NotUsed_2" 5 "NotUsed_1" 4 "SpecialMode_2" 3 "SpecialMode_1" 2 "Comfort" 1 "Sport" 0 "Normal" ;
VAL_ 130 DrvSteActv_B_Stat 1 "Active" 0 "Inactive" ;
VAL_ 130 DrvSte_Tq_Actl 255 "Invalid" 254 "Unknown" ;
VAL_ 130 SteMdule_D_Stat 7 "NotUsed" 6 "EPAS_Failure3" 5 "EPAS_Failure2" 4 "System_Failure" 3 "EPAS_Shutdown" 2 "Normal_Op_Full_Assist" 1 "Normal_Op_Limited_Assist" 0 "EPAS_Initialization" ;
VAL_ 130 SteMdule_U_Meas 255 "Invalid" ;
VAL_ 130 SteMdule_I_Est 4095 "Invalid" ;
VAL_ 130 EPAS_Failure 3 "SERVICE_POWER_STEERING_NOW" 2 "SERVICE_POWER_STEERING" 1 "POWER_STRG_ASSIST_FAULT" 0 "EPAS_OK_NO_MESSAGE" ;
VAL_ 130 SteeringColumnTorque 255 "Invalid" 254 "Unknown" ;
VAL_ 130 SAPPAngleControlStat6 1 "RequestedAngleNotReached" 0 "RequestedAngleCanBeReached" ;
VAL_ 130 SAPPAngleControlStat5 1 "StrgColTorqueExceed_EAROn" 0 "ExternalSigContentOKforEAC" ;
VAL_ 130 SAPPAngleControlStat4 1 "SpeedLimitExceededEAROn" 0 "ExternalSigContentOKforEAC" ;
VAL_ 130 SAPPAngleControlStat3 1 "EARactiveNoReverseEngage" 0 "ExternalSigContentOKforEAC" ;
VAL_ 130 SAPPAngleControlStat2 1 "Rel_ExtSteeringAngleReqx" 0 "NoRel_ExtSteeringAngleReqx" ;
VAL_ 130 SAPPAngleControlStat1 3 "Fault" 2 "Active" 1 "Open" 0 "Closed" ;
VAL_ 1046 PrkBrkDynmc_D_Allw 3 "NotUsed" 2 "EPB_ECD_NotPossible" 1 "EPB_ECD_Possible" 0 "Used_at_Start_Up" ;
VAL_ 1046 BrkPrkBrkDynmc_B_Actl 1 "Active" 0 "Inactive" ;
VAL_ 1046 HsaMde_D_Mem 3 "Undefined" 2 "Manual" 1 "Automatic" 0 "Off" ;
VAL_ 1046 BrkBstrVac_B_Rq 1 "Yes" 0 "No" ;
VAL_ 1046 HdcMde_D_Actl 7 "Fault" 6 "Temporarily_Unavailable" 5 "NotEnabled_WrongGearSel" 4 "NotEnabled_SpdLimitExceed" 3 "Active_Braking" 2 "Not_Active_Braking" 1 "Off" 0 "Undefined" ;
VAL_ 1046 RearDiffLck_Tq2_RqMx 4095 "Faulty" ;
VAL_ 1046 TRLR_SWAY_EVNT_IN_PROG 1 "Yes" 0 "No" ;
VAL_ 1046 TRLR_SWAY_CONFIG_STAT 1 "On" 0 "Off" ;
VAL_ 1046 TCMode 1 "Active" 0 "Inactive" ;
VAL_ 1046 DrvSlipCtlLamp_D_Rq 3 "Fast_Flash" 2 "Slow_Flash" 1 "On" 0 "Off" ;
VAL_ 1046 Abs_B_Falt 1 "Yes" 0 "No" ;
VAL_ 1046 DrvSlipCtlMde_D_Ind 3 "App_Specific_Off_Mode_3" 2 "App_Specific_Off_Mode_2" 1 "App_Specific_Off_Mode_1" 0 "Default_Mode" ;
VAL_ 1046 DrvAntiLckLamp_D_Rq 3 "Fast_Flash" 2 "Slow_Flash" 1 "On" 0 "Off" ;
VAL_ 1046 StabCtlBrk_B_Avail 1 "Yes" 0 "No" ;
VAL_ 1046 DrvHdcWarnInfo_D_Rq 3 "Undefined" 2 "Lamp_On_Continuously" 1 "Lamp_Flashing" 0 "Lamp_Off_Continuously" ;
VAL_ 1046 DrvHdcMsg_D_Rq 7 "Undefined" 6 "Speed_too_High" 5 "Temporarily_Unavailable" 4 "System_Fault" 3 "Select_Gear" 2 "Off" 1 "On" 0 "No_Message" ;
VAL_ 1046 DrvHdcLampInfo_D_Rq 3 "Fast_Flash" 2 "Slow_Flash" 1 "On" 0 "Off" ;
VAL_ 1046 BpedMove_D_Actl 3 "Unknown" 2 "DriverApplyingBrakePedal" 1 "NoAutonomousBrkPdlMovement" 0 "AutonomousBrkPedalMove" ;
VAL_ 1046 ChimeBrk_B_Rq 1 "Yes" 0 "No" ;
VAL_ 1046 BrkLamp_B_Rq 1 "Yes" 0 "No" ;
VAL_ 1046 HILL_DESC_MC 7 "Fault_Detected" 6 "Cooling_Down" 5 "Abort_Apply_Brakes" 4 "Active" 3 "Disabled" 2 "Enabled" 1 "Off_Road" 0 "Normal" ;
VAL_ 1046 RearDiffElckrOpen_B_Rq 1 "Yes" 0 "No" ;
VAL_ 1234 RmtCtlConfgSrc_D_Stat 7 "NotUsed_2" 6 "NotUsed_1" 5 "BPO" 4 "ApaHmi" 3 "FAP_Handover" 2 "User" 1 "None" 0 "NotDetermined" ;
VAL_ 1234 RmtCtlTrjctry_D_Avail 1 "Available" 0 "NotAvailable" ;
VAL_ 1234 RmtCtlSns_D_Err 1 "Yes" 0 "No" ;
VAL_ 1234 RmtCtlPathPlan_D_Stat 7 "NotUsed_3" 6 "NotUsed_2" 5 "NotUsed_1" 4 "FinishedMovesExceeded" 3 "FinishedDistanceExceeded" 2 "Finished" 1 "Ongoing" 0 "None" ;
VAL_ 1234 RmtCtlPathPlan_B_Err 1 "Yes" 0 "No" ;
VAL_ 1234 RmtCtlAdas_D_Stat 7 "Paused" 6 "Abort" 5 "ManeuverFinished" 4 "EndPositionReached" 3 "Backward" 2 "Forward" 1 "ManeuverBegin" 0 "Inactive" ;
VAL_ 1234 RmtCtlAdas_B_Err 1 "Yes" 0 "No" ;
VAL_ 1234 RmtCtlSnsBlckg_B_Stat 1 "Yes" 0 "No" ;
VAL_ 1233 RmtCtlLeft_D_Avail 3 "NotUsed" 2 "Available" 1 "NotAvailable" 0 "Null" ;
VAL_ 1233 RmtCtlFront_D_Avail 3 "NotUsed" 2 "Available" 1 "NotAvailable" 0 "Null" ;
VAL_ 1233 FreeDrvRear_D_Avail 3 "NotUsed" 2 "Available" 1 "NotAvailable" 0 "Null" ;
VAL_ 1233 FreeDrvFwd_D_Avail 3 "NotUsed" 2 "Available" 1 "NotAvailable" 0 "Null" ;
VAL_ 1233 RmtCtlSnsRrCrnr_D_Stat 3 "Zone3" 2 "Zone2" 1 "Zone1" 0 "Off" ;
VAL_ 1233 RmtCtlSnsRlCrnr_D_Stat 3 "Zone3" 2 "Zone2" 1 "Zone1" 0 "Off" ;
VAL_ 1233 RmtCtlSnsRear_D_Stat 3 "Zone3" 2 "Zone2" 1 "Zone1" 0 "Off" ;
VAL_ 1233 RmtCtlSnsFront_D_Stat 3 "Zone3" 2 "Zone2" 1 "Zone1" 0 "Off" ;
VAL_ 1233 RmtCtlSnsFrCrnr_D_Stat 3 "Zone3" 2 "Zone2" 1 "Zone1" 0 "Off" ;
VAL_ 1233 RmtCtlSnsFlCrnr_D_Stat 3 "Zone3" 2 "Zone2" 1 "Zone1" 0 "Off" ;
VAL_ 1233 RmtCtlSideSnsR4_D_Stat 3 "Zone3" 2 "Zone2" 1 "Zone1" 0 "Off" ;
VAL_ 1233 RmtCtlSideSnsR3_D_Stat 3 "Zone3" 2 "Zone2" 1 "Zone1" 0 "Off" ;
VAL_ 1233 RmtCtlSideSnsR2_D_Stat 3 "Zone3" 2 "Zone2" 1 "Zone1" 0 "Off" ;
VAL_ 1233 RmtCtlSideSnsR1_D_Stat 3 "Zone3" 2 "Zone2" 1 "Zone1" 0 "Off" ;
VAL_ 1233 RmtCtlSideSnsL4_D_Stat 3 "Zone3" 2 "Zone2" 1 "Zone1" 0 "Off" ;
VAL_ 1233 RmtCtlSideSnsL3_D_Stat 3 "Zone3" 2 "Zone2" 1 "Zone1" 0 "Off" ;
VAL_ 1233 RmtCtlSideSnsL2_D_Stat 3 "Zone3" 2 "Zone2" 1 "Zone1" 0 "Off" ;
VAL_ 1233 RmtCtlSideSnsL1_D_Stat 3 "Zone3" 2 "Zone2" 1 "Zone1" 0 "Off" ;
VAL_ 1233 RmtCtlRightOrnt_D_Avail 7 "NotUsed_3" 6 "NotUsed_2" 5 "NotUsed_1" 4 "Both" 3 "Backward" 2 "Forward" 1 "None" 0 "NotDetermined" ;
VAL_ 1233 RmtCtlRight_D_Avail 3 "NotUsed" 2 "Available" 1 "NotAvailable" 0 "Null" ;
VAL_ 1233 RmtCtlRear_D_Avail 3 "NotUsed" 2 "Available" 1 "NotAvailable" 0 "Null" ;
VAL_ 1233 RmtCtlPrkMde_D_Stat 3 "NotUsed" 2 "FreeDrive" 1 "ParkIn" 0 "None" ;
VAL_ 1233 RmtCtlPrkInSlot_D_Stat 7 "NotUsed_3" 6 "NotUsed_2" 5 "NotUsed_1" 4 "Right" 3 "Left" 2 "Rear" 1 "Front" 0 "None" ;
VAL_ 1233 RmtCtlObstcl_B_Stat 1 "Yes" 0 "No" ;
VAL_ 1233 RmtCtlNxtMoveDir_D_Stat 3 "NotUsed" 2 "Backward" 1 "Forward" 0 "Null" ;
VAL_ 1233 RmtCtlMoveDir_D_Stat 3 "NotUsed" 2 "Backward" 1 "Forward" 0 "None" ;
VAL_ 1233 RmtCtlLeftOrnt_D_Avail 7 "NotUsed_3" 6 "NotUsed_2" 5 "NotUsed_1" 4 "Both" 3 "Backward" 2 "Forward" 1 "None" 0 "NotDetermined" ;
VAL_ 125 VehRolComp_W_Actl 4094 "NoDataExists" 4095 "Fault" ;
VAL_ 125 VehVertComp_A_Actl 1022 "NoDataExists" 1023 "Fault" ;
VAL_ 125 BrkTot_Tq_RqArb 8191 "Fault" 8190 "Unknown" ;
VAL_ 125 BrkTot_Tq_Actl 8191 "Fault" 8190 "Unknown" ;
VAL_ 125 HsaStat_D_Actl 7 "Faulty" 6 "FaultyWithDriverIndication" 5 "SlowRelease" 4 "FastRelease" 3 "ActiveBrakePedalReleased" 2 "ActiveBrakePedalPressed" 1 "FindingGradient" 0 "Inactive" ;
VAL_ 531 VehStop_D_Stat 3 "Faulty" 2 "NoDataExists" 1 "Yes" 0 "No" ;
VAL_ 531 TracCtlPtActv_B_Actl 1 "Active" 0 "Inactive" ;
VAL_ 531 LscmbbMntr_B_Err 1 "DisplayMessage" 0 "NoMessage" ;
VAL_ 531 LscmbbBrkDis_B_Actl 1 "Yes" 0 "No" ;
VAL_ 531 LscmbbDeny_B_ActlBrk 1 "Yes" 0 "No" ;
VAL_ 531 PrkBrkYwLamp_D_Rq 3 "Fast_Flash" 2 "Slow_Flash" 1 "On" 0 "Off" ;
VAL_ 531 PrkBrkRedLamp_D_Rq 3 "Fast_Flash" 2 "Slow_Flash" 1 "On" 0 "Off" ;
VAL_ 531 VehicleStationary 1 "Yes" 0 "No" ;
VAL_ 531 LscmbbBrkDecel_B_Actl 1 "Yes" 0 "No" ;
VAL_ 531 AbsActv_B_Actl 1 "Yes" 0 "No" ;
VAL_ 531 StabCtlBrkActv_B_Actl 1 "Yes" 0 "No" ;
VAL_ 531 CmbbBrkPrchg_B_Actl 1 "Yes" 0 "No" ;
VAL_ 531 CmbbBrkDecel_B_Actl 1 "Yes" 0 "No" ;
VAL_ 531 CmbbBaSensInc_B_Actl 1 "Yes" 0 "No" ;
VAL_ 531 AccBrkWarm_B_Actl 1 "Yes" 0 "No" ;
VAL_ 531 AccBrkTotTqMn_B_Actl 1 "Yes" 0 "No" ;
VAL_ 531 AccBrkPrchgActv_B_Actl 1 "Yes" 0 "No" ;
VAL_ 531 AccBrkDis_B_Actl 1 "Yes" 0 "No" ;
VAL_ 531 AccBrkDeny_B_Actl 1 "Yes" 0 "No" ;
VAL_ 531 AccBrkActv_B_Actl 1 "Yes" 0 "No" ;
VAL_ 531 PrplDrgCtlActv_B_Actl 1 "Active" 0 "Inactive" ;
VAL_ 531 LscmbbBaSensInc_B_Actl 1 "Yes" 0 "No" ;
VAL_ 531 CmbbBrkDis_B_Actl 1 "Yes" 0 "No" ;
VAL_ 531 CmbbDeny_B_ActlBrk 1 "Yes" 0 "No" ;
VAL_ 531 CcDis_B_Cmd 1 "Yes" 0 "No" ;
VAL_ 531 VehLongOvrGnd_A_Est 1023 "Fault" 1022 "Unknown" ;
VAL_ 531 LscmbBrkPrchg_B_Actl 1 "Active" 0 "Inactive" ;
VAL_ 531 AccStopActv_B_ActlBrk 1 "Yes" 0 "No" ;
VAL_ 531 AccDis_B_ActlEpb 1 "Yes" 0 "No" ;
VAL_ 531 PrkBrkMsgTxt_D_Rq 15 "Message15" 14 "Message14" 13 "Message13" 12 "Message12" 11 "Message11" 10 "Message10" 9 "Message9" 8 "Message8" 7 "Message7" 6 "Message6" 5 "Message5" 4 "Message4" 3 "Message3" 2 "Message2" 1 "Message1" 0 "No_Message" ;
VAL_ 531 PrkBrkStatus 7 "GeneralFault_MaintenceMode" 6 "ECD_by_Brake_ECU_Active" 5 "EPB_Limphome_Active" 4 "Rear_Caliper_Open" 3 "RWU_By_EPB_Active" 2 "Rear_Caliper_Transition" 1 "Rear_Caliper_Closed" 0 "Not_Supported" ;
VAL_ 638 EmgcyCallHmi_D_Stat 15 "NotUsed_1" 14 "Standby" 13 "Disabled" 12 "Malfunction" 11 "CallCompleted" 10 "CallDisconnected" 9 "CallNotPossible" 8 "CallCancelled" 7 "CallRetry" 6 "CallConnected" 5 "CallInProgress" 4 "CallMsdTransfer" 3 "CallDial" 2 "CallCancelTimer" 1 "NoEvent" 0 "Null" ;
VAL_ 638 EmgcyCallFalt_B_Dsply 1 "Yes" 0 "No" ;
VAL_ 638 EmgcyCall_D_Stat 7 "NotUsed_3" 6 "NotUsed_2" 5 "NotUsed_1" 4 "ManualEmergencyCall" 3 "AutoEmergencyCall" 2 "NoEvent" 1 "EmergencyCallNotSupported" 0 "Null" ;
VAL_ 894 RmtCtlTrgt_D_Rq 3 "NotUsed" 2 "Null" 1 "RemoteParkAssist" 0 "ManeuverId" ;
VAL_ 894 RmtCtlRngSet_D_Stat 3 "NotUsed" 2 "RangeSetB" 1 "RangeSetA" 0 "None" ;
VAL_ 894 RmtCtlKeySrch_D_Stat 3 "NotUsed" 2 "Valid" 1 "Invalid" 0 "Null" ;
VAL_ 894 RmtCtlBody_D_Stat 15 "NotUsed_6" 14 "NotUsed_5" 13 "NotUsed_4" 12 "NotUsed_3" 11 "NotUsed_2" 10 "NotUsed_1" 9 "Shutdown" 8 "ManeuverFinished" 7 "ReadyForResume" 6 "Pause" 5 "Maneuvering" 4 "ReadyForManeuvering" 3 "Activation" 2 "Initialize" 1 "Preparation" 0 "Disabled" ;
VAL_ 894 RmtCtl_D_RqBody 7 "NotUsed_2" 6 "NotUsed_1" 5 "Error" 4 "Abort" 3 "PauseKeypad" 2 "PauseHazard" 1 "PauseDoorHandle" 0 "Null" ;
VAL_ 75 VedsPasKneeBag_D_Ltchd 7 "Fault" 6 "NotSupported" 5 "Unused_3" 4 "Unused_2" 3 "Unused_1" 2 "NotDeployed" 1 "Deployed" 0 "NoEvent" ;
VAL_ 75 VedsRw3pRib_D_Ltchd 7 "Fault" 6 "NotSupported" 5 "Unused_3" 4 "Unused_2" 3 "Unused_1" 2 "NotDeployed" 1 "Deployed" 0 "NoEvent" ;
VAL_ 75 VedsRw3dRib_D_Ltchd 7 "Fault" 6 "NotSupported" 5 "Unused_3" 4 "Unused_2" 3 "Unused_1" 2 "NotDeployed" 1 "Deployed" 0 "NoEvent" ;
VAL_ 75 VedsRw1mBckl_D_Ltchd 5 "Unused_3" 4 "Unused_2" 3 "Unused_1" 2 "NotBelted" 1 "Belted" 0 "NoEvent" 7 "Fault" 6 "NotSupported" ;
VAL_ 75 VedsRw1mBelt_D_Ltchd 7 "Fault" 6 "NotSupported" 5 "Unused_3" 4 "Unused_2" 3 "Unused_1" 2 "NotDeployed" 1 "Deployed" 0 "NoEvent" ;
VAL_ 75 VedsRw2pRib_D_Ltchd 7 "Fault" 6 "NotSupported" 5 "Unused_3" 4 "Unused_2" 3 "Unused_1" 2 "NotDeployed" 1 "Deployed" 0 "NoEvent" ;
VAL_ 75 VedsRw2dRib_D_Ltchd 7 "Fault" 6 "NotSupported" 5 "Unused_3" 4 "Unused_2" 3 "Unused_1" 2 "NotDeployed" 1 "Deployed" 0 "NoEvent" ;
VAL_ 75 VedsRw3pBckl_D_Ltchd 5 "Unused_3" 4 "Unused_2" 3 "Unused_1" 2 "NotBelted" 1 "Belted" 0 "NoEvent" 7 "Fault" 6 "NotSupported" ;
VAL_ 75 VedsRw3mBckl_D_Ltchd 5 "Unused_3" 4 "Unused_2" 3 "Unused_1" 2 "NotBelted" 1 "Belted" 0 "NoEvent" 7 "Fault" 6 "NotSupported" ;
VAL_ 75 VedsRw3dBckl_D_Ltchd 5 "Unused_3" 4 "Unused_2" 3 "Unused_1" 2 "NotBelted" 1 "Belted" 0 "NoEvent" 7 "Fault" 6 "NotSupported" ;
VAL_ 75 VedsRw2pBckl_D_Ltchd 5 "Unused_3" 4 "Unused_2" 3 "Unused_1" 2 "NotBelted" 1 "Belted" 0 "NoEvent" 7 "Fault" 6 "NotSupported" ;
VAL_ 75 VedsRw2mBckl_D_Ltchd 5 "Unused_3" 4 "Unused_2" 3 "Unused_1" 2 "NotBelted" 1 "Belted" 0 "NoEvent" 7 "Fault" 6 "NotSupported" ;
VAL_ 75 VedsRw2dBckl_D_Ltchd 5 "Unused_3" 4 "Unused_2" 3 "Unused_1" 2 "NotBelted" 1 "Belted" 0 "NoEvent" 7 "Fault" 6 "NotSupported" ;
VAL_ 75 VedsRw1PasChld_D_Ltchd 7 "Fault" 6 "NotSupported" 5 "Unused_3" 4 "Unused_2" 3 "Unused_1" 2 "ChildNotDetected" 1 "ChildDetected" 0 "NoEvent" ;
VAL_ 75 VedsRw1PasBckl_D_Ltchd 5 "Unused_3" 4 "Unused_2" 3 "Unused_1" 2 "NotBelted" 1 "Belted" 0 "NoEvent" 7 "Fault" 6 "NotSupported" ;
VAL_ 75 VedsRw1DrvBckl_D_Ltchd 5 "Unused_3" 4 "Unused_2" 3 "Unused_1" 2 "NotBelted" 1 "Belted" 0 "NoEvent" 7 "Fault" 6 "NotSupported" ;
VAL_ 74 VedsPasSideBag_D_Ltchd 7 "Fault" 6 "NotSupported" 5 "Unused_3" 4 "Unused_2" 3 "Unused_1" 2 "NotDeployed" 1 "Deployed" 0 "NoEvent" ;
VAL_ 74 VedsPasCrtnBag_D_Ltchd 7 "Fault" 6 "NotSupported" 5 "Unused_3" 4 "Unused_2" 3 "Unused_1" 2 "NotDeployed" 1 "Deployed" 0 "NoEvent" ;
VAL_ 74 VedsPasBelt_D_Ltchd 7 "Fault" 6 "NotSupported" 5 "Unused_3" 4 "Unused_2" 3 "Unused_1" 2 "NotDeployed" 1 "Deployed" 0 "NoEvent" ;
VAL_ 74 VedsPasBag_D_Ltchd 7 "Fault" 6 "NotSupported" 5 "Unused_3" 4 "Unused_2" 3 "Unused_1" 2 "NotDeployed" 1 "Deployed" 0 "NoEvent" ;
VAL_ 74 VedsMultiEvnt_D_Ltchd 7 "Fault" 6 "NotSupported" 5 "Unused_3" 4 "Unused_2" 3 "Unused_1" 2 "Yes" 1 "No" 0 "NoEvent" ;
VAL_ 74 VedsMaxDeltaV_D_Ltchd 0 "NoEvent" 255 "Fault" 254 "NotSupported" ;
VAL_ 74 VedsDrvKneeBag_D_Ltchd 7 "Fault" 6 "NotSupported" 5 "Unused_3" 4 "Unused_2" 3 "Unused_1" 2 "NotDeployed" 1 "Deployed" 0 "NoEvent" ;
VAL_ 74 VedsEvntType_D_Ltchd 7 "Fault" 6 "NotSupported" 5 "Unused" 4 "Rolllover" 3 "Rear" 2 "Side" 1 "Frontal" 0 "NoEvent" ;
VAL_ 74 VedsEvntRoll_D_Ltchd 7 "Fault" 6 "NotSupported" 5 "Unused_3" 4 "Unused_2" 3 "Unused_1" 2 "Yes" 1 "No" 0 "NoEvent" ;
VAL_ 74 VedsDrvSideBag_D_Ltchd 7 "Fault" 6 "NotSupported" 5 "Unused_3" 4 "Unused_2" 3 "Unused_1" 2 "NotDeployed" 1 "Deployed" 0 "NoEvent" ;
VAL_ 74 VedsDrvCrtnBag_D_Ltchd 7 "Fault" 6 "NotSupported" 5 "Unused_3" 4 "Unused_2" 3 "Unused_1" 2 "NotDeployed" 1 "Deployed" 0 "NoEvent" ;
VAL_ 74 VedsDrvBelt_D_Ltchd 7 "Fault" 6 "NotSupported" 5 "Unused_3" 4 "Unused_2" 3 "Unused_1" 2 "NotDeployed" 1 "Deployed" 0 "NoEvent" ;
VAL_ 74 VedsDrvBag_D_Ltchd 7 "Fault" 6 "NotSupported" 5 "Unused_3" 4 "Unused_2" 3 "Unused_1" 2 "NotDeployed" 1 "Deployed" 0 "NoEvent" ;
VAL_ 74 eCallNotification 3 "Not_Used" 2 "Active" 1 "Normal" 0 "Not_Supported" ;
VAL_ 382 EngIdlShutDown_D2_Type 3 "Fleet" 2 "Keyless" 1 "Keyed" 0 "Null" ;
VAL_ 898 VedsRoll_An_Ltchd 8191 "Faulty" 8190 "Not Supported" 0 "No Event" ;
VAL_ 898 VedsPrmDirOfF_An_Ltchd 255 "Faulty" 254 "Not Supported" 0 "No Event" ;
VAL_ 898 SecondRowBcklPsngrMid 3 "Unknown" 2 "Unbelted" 1 "Belted" 0 "Faulty" ;
VAL_ 898 SecondRowBuckleDrvMid 3 "Unknown" 2 "Unbelted" 1 "Belted" 0 "Faulty" ;
VAL_ 898 FourthRowBucklePsngr 3 "Unknown" 2 "Unbelted" 1 "Belted" 0 "Faulty" ;
VAL_ 898 FourthRowBuckleMid 3 "Unknown" 2 "Unbelted" 1 "Belted" 0 "Faulty" ;
VAL_ 898 FourthRowBuckleDriver 3 "Unknown" 2 "Unbelted" 1 "Belted" 0 "Faulty" ;
VAL_ 898 Row3PsngrPrsnc_D_Actl 3 "Unknown" 2 "Empty" 1 "Occupied" 0 "Fault" ;
VAL_ 898 Row3MidPrsnc_D_Actl 3 "Unknown" 2 "Empty" 1 "Occupied" 0 "Fault" ;
VAL_ 898 Row3DrvPrsnc_D_Actl 3 "Unknown" 2 "Empty" 1 "Occupied" 0 "Fault" ;
VAL_ 898 Row2PsngrPrsnc_D_Actl 3 "Unknown" 2 "Empty" 1 "Occupied" 0 "Fault" ;
VAL_ 898 Row2MidPrsnc_D_Actl 3 "Unknown" 2 "Empty" 1 "Occupied" 0 "Fault" ;
VAL_ 898 Row2DrvPrsnc_D_Actl 3 "Unknown" 2 "Empty" 1 "Occupied" 0 "Fault" ;
VAL_ 536 BrkCtlSys_D_Stat 15 "ESCDis_TCSDis" 14 "ESCDis_TCSRed" 13 "ESCDis_TCSFull" 12 "ESCDis_TCSNde" 11 "ESCRed_TCSDis" 10 "ESCRed_TCSRed" 9 "ESCRed_TCSFull" 8 "ESCRed_TCSNde" 7 "ESCFull_TCSDis" 6 "ESCFull_TCSRed" 5 "ESCFull_TCSFull" 4 "ESCFull_TCSNde" 3 "ESCNde_TCSDis" 2 "ESCNde_TCSRed" 1 "ESCNde_TCSFull" 0 "ESCNde_TCSNde" ;
VAL_ 536 BrkWhlFricRr_Tq_Actl 255 "Faulty" 254 "NoDataExists" ;
VAL_ 536 BrkWhlFricRl_Tq_Actl 255 "Faulty" 254 "NoDataExists" ;
VAL_ 536 BrkWhlFricFr_Tq_Actl 255 "Faulty" 254 "NoDataExists" ;
VAL_ 536 BrkWhlFricFl_Tq_Actl 255 "Faulty" 254 "NoDataExists" ;
VAL_ 626 PaakCtlIndx8_D_Stat 15 "NotUsed_9" 14 "NotUsed_8" 13 "NotUsed_7" 12 "NotUsed_6" 11 "NotUsed_5" 10 "NotUsed_4" 9 "NotUsed_3" 8 "NotUsed_2" 7 "NotUsed_1" 6 "Approach" 5 "RearInterior" 4 "RearExterior" 3 "Passenger" 2 "Driver" 1 "Interior" 0 "Null" ;
VAL_ 626 PaakCtlIndx7_D_Stat 15 "NotUsed_9" 14 "NotUsed_8" 13 "NotUsed_7" 12 "NotUsed_6" 11 "NotUsed_5" 10 "NotUsed_4" 9 "NotUsed_3" 8 "NotUsed_2" 7 "NotUsed_1" 6 "Approach" 5 "RearInterior" 4 "RearExterior" 3 "Passenger" 2 "Driver" 1 "Interior" 0 "Null" ;
VAL_ 626 PaakCtlIndx6_D_Stat 15 "NotUsed_9" 14 "NotUsed_8" 13 "NotUsed_7" 12 "NotUsed_6" 11 "NotUsed_5" 10 "NotUsed_4" 9 "NotUsed_3" 8 "NotUsed_2" 7 "NotUsed_1" 6 "Approach" 5 "RearInterior" 4 "RearExterior" 3 "Passenger" 2 "Driver" 1 "Interior" 0 "Null" ;
VAL_ 626 PaakCtlIndx5_D_Stat 15 "NotUsed_9" 14 "NotUsed_8" 13 "NotUsed_7" 12 "NotUsed_6" 11 "NotUsed_5" 10 "NotUsed_4" 9 "NotUsed_3" 8 "NotUsed_2" 7 "NotUsed_1" 6 "Approach" 5 "RearInterior" 4 "RearExterior" 3 "Passenger" 2 "Driver" 1 "Interior" 0 "Null" ;
VAL_ 626 PaakCtlIndx4_D_Stat 15 "NotUsed_9" 14 "NotUsed_8" 13 "NotUsed_7" 12 "NotUsed_6" 11 "NotUsed_5" 10 "NotUsed_4" 9 "NotUsed_3" 8 "NotUsed_2" 7 "NotUsed_1" 6 "Approach" 5 "RearInterior" 4 "RearExterior" 3 "Passenger" 2 "Driver" 1 "Interior" 0 "Null" ;
VAL_ 626 PaakCtlIndx3_D_Stat 15 "NotUsed_9" 14 "NotUsed_8" 13 "NotUsed_7" 12 "NotUsed_6" 11 "NotUsed_5" 10 "NotUsed_4" 9 "NotUsed_3" 8 "NotUsed_2" 7 "NotUsed_1" 6 "Approach" 5 "RearInterior" 4 "RearExterior" 3 "Passenger" 2 "Driver" 1 "Interior" 0 "Null" ;
VAL_ 626 PaakCtlIndx2_D_Stat 15 "NotUsed_9" 14 "NotUsed_8" 13 "NotUsed_7" 12 "NotUsed_6" 11 "NotUsed_5" 10 "NotUsed_4" 9 "NotUsed_3" 8 "NotUsed_2" 7 "NotUsed_1" 6 "Approach" 5 "RearInterior" 4 "RearExterior" 3 "Passenger" 2 "Driver" 1 "Interior" 0 "Null" ;
VAL_ 626 PaakCtlIndx1_D_Stat 15 "NotUsed_9" 14 "NotUsed_8" 13 "NotUsed_7" 12 "NotUsed_6" 11 "NotUsed_5" 10 "NotUsed_4" 9 "NotUsed_3" 8 "NotUsed_2" 7 "NotUsed_1" 6 "Approach" 5 "RearInterior" 4 "RearExterior" 3 "Passenger" 2 "Driver" 1 "Interior" 0 "Null" ;
VAL_ 1012 AirCondRec_B_RqVehEl 1 "Yes" 0 "No" ;
VAL_ 1012 ChrgLocSaved_B_Dsply 1 "Yes" 0 "No" ;
VAL_ 1012 ChrgLocLongPostv_B_Sav 1 "Yes" 0 "No" ;
VAL_ 1012 ChrgLocLattPostv_B_Sav 1 "Yes" 0 "No" ;
VAL_ 1012 ChrgNowCurnt_B_Dsply 1 "On" 0 "Off" ;
VAL_ 516 EngAoutNActl_D_QF 3 "OK" 2 "Not_Within_Specifications" 1 "No_Data_Exists" 0 "Faulty" ;
VAL_ 516 EngAout3_N_Actl 65535 "Invalid" ;
VAL_ 516 ApedPosPcActl_D_Qf 3 "OK" 2 "Not_Within_Specifications" 1 "No_Data_Exists" 0 "Faulty" ;
VAL_ 516 ApedPos_PcRate_ActlArb 255 "Fault" 254 "Unknown" ;
VAL_ 1091 WakeAlarm2_B_Typ 1 "CanAndEcuDriveCircuit" 0 "CanOnly" ;
VAL_ 1091 CamraRearOn_D2_Stat2 7 "Faulty" 6 "NotUsed_3" 5 "NotUsed_2" 4 "NotUsed_1" 3 "Decommission" 2 "Activate" 1 "Deactivate" 0 "Null" ;
VAL_ 1091 PoliceAux4Lamp_B_Rq2 1 "On" 0 "Off" ;
VAL_ 1091 PoliceAux3Lamp_B_Rq2 1 "On" 0 "Off" ;
VAL_ 1091 PoliceAux2Lamp_B_Rq2 1 "On" 0 "Off" ;
VAL_ 1091 PoliceAux1Lamp_B_Rq2 1 "On" 0 "Off" ;
VAL_ 1091 TowBarMsgTxt_D_Rq 7 "NotUsed3" 6 "NotUsed2" 5 "NotUsed1" 4 "TowBar_Ext_No_Trlr" 3 "Error_Dealer_Fix" 2 "Start_Engine_Swivel" 1 "Check_Tow_Bar" 0 "Null" ;
VAL_ 1091 ParkLampTrlrOut_B_Stat 1 "Out" 0 "Null" ;
VAL_ 1091 TrlrLampCtl_D_Stat 3 "NotUsed" 2 "TrlrLampCnnctDrvFailure" 1 "TrlrLampNotCnnctDrvFailure" 0 "Null" ;
VAL_ 1091 TrlrBattChrg_D_Stat 3 "Reverse" 2 "Normal" 1 "Low" 0 "Null" ;
VAL_ 1091 StopLampTrlrOut_B_Stat 1 "Out" 0 "Null" ;
VAL_ 1091 TurnLampTrlrRr_B_Stat 1 "Out" 0 "Null" ;
VAL_ 1091 TrlrAlarmSpprt_D_Stat 3 "SupportedByBrakesAndLights" 2 "SupportedByLights" 1 "SupportedByBrakes" 0 "NotSupported" ;
VAL_ 1091 TurnLampTrlrRl_B_Stat 1 "Out" 0 "Null" ;
VAL_ 1091 TrlrLampCnnct_B_Actl 1 "Yes" 0 "No" ;
VAL_ 359 PrplWhlRgenMn_Tq_Actl 8191 "Faulty" ;
VAL_ 359 ElPw_D_StatStrtStop 15 "NotUsed6" 14 "NotUsed5" 13 "NotUsed4" 12 "NotUsed3" 11 "NotUsed2" 10 "NotUsed1" 9 "Supported_Level_4" 8 "Supported_Level_3" 7 "Supported_Level_2" 6 "Supported_Level_1" 5 "Limited_Support" 4 "Fault_Limited" 3 "LV_Event_in_Progress" 2 "Not_Supported_Imminent" 1 "Supported_All" 0 "Not_Supported" ;
VAL_ 359 PrplWhlTot2_Tq_Actl 65535 "Fault" 65534 "NoDataExists" ;
VAL_ 359 LscmbbDeny_B_ActlPrpl 1 "Denied" 0 "Allowed" ;
VAL_ 359 LscmbbEngTqMn_B_Actl 1 "Engine_Braking_Activated" 0 "Engine_Braking_Off" ;
VAL_ 359 PwPckTq_D_Stat 3 "PwPckOn_TqAvailable" 2 "StartInPrgrss_TqNotAvail" 1 "PwPckOn_TqNotAvailable" 0 "PwPckOff_TqNotAvailable" ;
VAL_ 359 Eng_D_Stat 3 "NotUsed" 2 "EngAutoStopped" 1 "EngOn" 0 "EngOff" ;
VAL_ 359 PlgActvArb_B_Actl 1 "On" 0 "Off" ;
VAL_ 359 ElPw_D_Stat 7 "NotUsed_3" 6 "NotUsed_2" 5 "NotUsed_1" 4 "Fault_Limited" 3 "LV_Event_In_Progress" 2 "Not_Supported_Imminent" 1 "Supported" 0 "Not_Supported" ;
VAL_ 359 TrnAinTq_D_Qf 3 "OK" 2 "Not_Within_Specifications" 1 "No_Data_Exists" 0 "Faulty" ;
VAL_ 374 GearEngag_D_Actl 7 "Undefined" 6 "Fwd_Clutch_Fully_Engaged" 5 "Neutral_Idle" 4 "Disengaged_to_Neutral_Idle" 3 "Disengaged_to_Neutral_Park" 2 "Engagement_in_Progress" 1 "InitializeFwdClutchEngagmt" 0 "Park_Neutral" ;
VAL_ 374 TrnRng_D_Rq 15 "Fault" 14 "Unknown_Position" 13 "NotUsed_2" 12 "NotUsed_1" 11 "Range6" 10 "Range5" 9 "Range4" 8 "Range3_M3_L3" 7 "Range2_M2_L2" 6 "Range1_M1_L1" 5 "Low" 4 "Sport_DriveSport_Mposition" 3 "Drive" 2 "Neutral" 1 "Reverse" 0 "Park" ;
VAL_ 374 TrnPrkSys_D_Actl 15 "Faulty" 14 "NotUsed_5" 13 "NotUsed_4" 12 "NotUsed_3" 11 "NotUsed_2" 10 "NotUsed_1" 9 "FrequencyError" 8 "OutOfRangeHigh" 7 "OutOfRangeLow" 6 "Override" 5 "OutOfPark" 4 "TransitionCloseToOutOfPark" 3 "AtNoSpring" 2 "TransitionCloseToPark" 1 "Park" 0 "NotKnown" ;
VAL_ 374 GearLvr_D_ActlDrv 15 "Fault" 14 "Unknown_Position" 13 "NotUsed_2" 12 "NotUsed_1" 11 "Range6" 10 "Range5" 9 "Range4" 8 "Range3_M3_L3" 7 "Range2_M2_L2" 6 "Range1_M1_L1" 5 "Low" 4 "Sport_DriveSport_Mposition" 3 "Drive" 2 "Neutral" 1 "Reverse" 0 "Park" ;
VAL_ 374 GearPos_D_Trg 15 "Unknown" 14 "Reverse" 13 "Undefined_5" 12 "Undefined_4" 11 "Undefined_3" 10 "Tenth" 9 "Ninth" 8 "Eighth" 7 "Seventh" 6 "Sixth" 5 "Fifth" 4 "Fourth" 3 "Third" 2 "Second" 1 "First" 0 "Neutral" ;
VAL_ 374 GearPos_D_Actl 15 "Unknown" 14 "Reverse" 13 "Undefined_5" 12 "Undefined_4" 11 "Undefined_3" 10 "Tenth" 9 "Ninth" 8 "Eighth" 7 "Seventh" 6 "Sixth" 5 "Fifth" 4 "Fourth" 3 "Third" 2 "Second" 1 "First" 0 "Neutral" ;
VAL_ 479 DISP_SetVol_Source_Rq 5 "SetAudioVolume" 4 "SetVRvolume" 3 "SetPhoneVolume" 2 "SetPromptVolume" 1 "SetTAVolume" 0 "Inactive" ;
VAL_ 479 DISP_Setshaker_Rq 2 "On" 1 "Off" 0 "Inactive" ;
VAL_ 765 BalrSwtch_D_Stat 3 "NotUsed" 2 "Pressed" 1 "NotPressed" 0 "Null" ;
VAL_ 765 BalrMde_D_Rq 3 "High" 2 "Medium" 1 "Low" 0 "Null" ;
VAL_ 765 RstrnOnPsngr_D_RqMnu 15 "Faulty" 14 "NotUsed_11" 13 "NotUsed_10" 12 "ConfiguredOff" 11 "NotUsed_9" 10 "On" 9 "NotUsed_8" 8 "NotUsed_7" 7 "NotUsed_6" 6 "NotUsed_5" 5 "Off" 4 "NotUsed_4" 3 "NotUsed_3" 2 "NotUsed_2" 1 "NotUsed_1" 0 "NoAction" ;
VAL_ 765 WaitToStartLamp_D_Falt 3 "NotUsed" 2 "Wait_to_start_lamp_failed" 1 "Diagnosis_not_ready" 0 "Wait_to_start_lamp_OK" ;
VAL_ 765 EsaOn_B_Rq 1 "On" 0 "Off" ;
VAL_ 765 BttOn_B_Rq 1 "On" 0 "Off" ;
VAL_ 765 Btt_L_Actl 127 "Faulty" 126 "NoDataExists" ;
VAL_ 765 RearDiffLck_D_RqArb 3 "Faulty" 2 "NotUsed" 1 "On" 0 "Off" ;
VAL_ 765 AwdMde_D_RqArb 7 "Faulty" 6 "NotUsed2" 5 "NoRequest" 4 "Neutral" 3 "FourByFourLow" 2 "FourByFourHigh" 1 "FourByFourAuto" 0 "FourByTwo" ;
VAL_ 765 SelDrvMdeTxtReset_B_Rq 1 "Yes" 0 "No" ;
VAL_ 765 AutoTowAllw_D_RqMnu 3 "TowHaulCommandedOn" 2 "AutoTowHaulEnabled" 1 "AutoTowHaulDisabled" 0 "NoSelection" ;
VAL_ 765 DrvInputRequired_B_Rq 1 "Yes" 0 "No" ;
VAL_ 765 SelDrvMdeDsply_B_Avail 1 "Available" 0 "NotAvailable" ;
VAL_ 765 EngExhMdeQuiet_D_Rq 3 "Faulty" 2 "QuietExhaust" 1 "LoudExhaust" 0 "Null" ;
VAL_ 765 AirSusp_D_RqDrv 3 "NotUsed" 2 "On" 1 "Off" 0 "NoModeSelected" ;
VAL_ 765 Mc_VehUntTrpCoUsrSel_St 0 "TripComputer_metric" 1 "TripComputer_imperial" ;
VAL_ 765 Mc_VehUnitTempUsrSel_St 0 "Temperature_deg_c" 1 "Temperature_deg_f" ;
VAL_ 765 Mc_VehDayNightUsrSel_St 2 "Night" 1 "Day" 0 "Invalid" ;
VAL_ 765 Mc_VehTimeFrmtUsrSel_St 2 "24h_mode" 1 "12h_mode" 0 "Invalid" ;
VAL_ 765 Mc_VehThemeUsrSel_St 2 "Theme_2" 1 "Theme_1" 0 "Invalid" ;
VAL_ 765 Mc_VehLangUsrSel_St 33 "Ukrainian" 32 "Indian_English" 31 "Thai" 30 "Slovak" 29 "Arabic" 28 "Taiwanese" 27 "Mandarin_Chinese" 26 "Korean" 25 "AU_English" 24 "Japanese" 23 "Braz_Portuguese" 22 "EU_Portuguese" 21 "Finish" 20 "Norwegian" 19 "Danish" 18 "Swedish" 17 "Hungarian" 16 "Greek" 15 "Czech" 14 "Polish" 13 "Flemish" 12 "Dutch" 11 "Russian" 10 "Turkish" 9 "Mex_Spanish" 8 "EU_Spanish" 7 "Cana_French" 6 "EU_French" 5 "Italian" 4 "German" 3 "NA_English" 2 "UK_English" 1 "Unknown" 0 "Invalid" ;
VAL_ 765 AwdRnge_D_ActlIpc 7 "Unknown" 6 "High_Range_2wd" 5 "High_Range_Auto" 4 "High_Range_Locked" 3 "Neutral" 2 "Low_Range_2wd" 1 "Low_Range_Auto" 0 "Low_Range_Locked" ;
VAL_ 765 AwdDrvMde_D_Rq 7 "Faulty" 6 "NotAvailable" 5 "RockCrawl" 4 "Baja" 3 "MudAndSand" 2 "Weather" 1 "Sport" 0 "Normal" ;
VAL_ 765 EngExhMdeQuiet_D2_Rq 7 "NotUsed_3" 6 "NotUsed_2" 5 "NotUsed_1" 4 "Track" 3 "Sport" 2 "Normal" 1 "Stealth" 0 "Null" ;
VAL_ 765 BrkLineLck_D_Rq 3 "Off" 2 "Engage" 1 "Initiate" 0 "NoRequest" ;
VAL_ 765 EdmSailMde_B_RqDrv 1 "On" 0 "Off" ;
VAL_ 765 Running_Board_Cmd 3 "Unused" 2 "Manually_Deployed" 1 "All_Enabled" 0 "All_Disabled" ;
VAL_ 739 SpeedChngChime_D_Rq 0 "Null" 1 "Off" 2 "On" 3 "NotUsed" ;
VAL_ 739 LostPKChirp_D_RqMnu 0 "Null" 1 "Disabled" 2 "Enabled" 3 "NotConfigured" ;
VAL_ 739 VgfSet_D_Stat 3 "NotUsed" 2 "On" 1 "Off" 0 "Null" ;
VAL_ 739 OnbTrgtSocOvrrd_D_Rq 3 "NotUsed" 2 "Enable" 1 "Disable" 0 "Null" ;
VAL_ 739 BptDly_T_RqMnu 63 "Faulty" 62 "NoDataExists" ;
VAL_ 739 BptMnSoc_L_RqMnu 8191 "Faulty" 8190 "NoDataExists" ;
VAL_ 739 BptStrtStop_D_RqMnu 3 "NotUsed_1" 2 "Start" 1 "Stop" 0 "NoRequest" ;
VAL_ 739 BptMde_D_RqMnu 7 "NotUsed_4" 6 "NotUsed_3" 5 "NotUsed_2" 4 "NotUsed_1" 3 "Automatic" 2 "Manual" 1 "Off" 0 "Null" ;
VAL_ 739 VehHornOccAlrt_D_Stat 3 "NotUsed" 2 "On" 1 "Off" 0 "Null" ;
VAL_ 739 SeatOccRear_D_Stat 3 "NotUsed" 2 "On" 1 "Off" 0 "Null" ;
VAL_ 739 BabySeatInUse_D_Stat 3 "NotUsed" 2 "InUse" 1 "NotInUse" 0 "Null" ;
VAL_ 739 SeatOccChime_B_RqCancl 1 "Cancel" 0 "Null" ;
VAL_ 739 EngExhMdeHrStrt_D_Rq 31 "NotUsed_7" 30 "NotUsed_6" 29 "NotUsed_5" 28 "NotUsed_4" 27 "NotUsed_3" 26 "NotUsed_2" 25 "NotUsed_1" 24 "Hour23_11pm" 23 "Hour22_10pm" 22 "Hour21_9pm" 21 "Hour20_8pm" 20 "Hour19_7pm" 19 "Hour18_6pm" 18 "Hour17_5pm" 17 "Hour16_4pm" 16 "Hour15_3pm" 15 "Hour14_2pm" 14 "Hour13_1pm" 13 "Hour12_12pm" 12 "Hour11_11am" 11 "Hour10_10am" 10 "Hour9_9am" 9 "Hour8_8am" 8 "Hour7_7am" 7 "Hour6_6am" 6 "Hour5_5am" 5 "Hour4_4am" 4 "Hour3_3am" 3 "Hour2_2am" 2 "Hour1_1am" 1 "Hour0_12am" 0 "Null" ;
VAL_ 739 EngExhMdeHrEnd_D_Rq 31 "NotUsed_7" 30 "NotUsed_6" 29 "NotUsed_5" 28 "NotUsed_4" 27 "NotUsed_3" 26 "NotUsed_2" 25 "NotUsed_1" 24 "Hour23_11pm" 23 "Hour22_10pm" 22 "Hour21_9pm" 21 "Hour20_8pm" 20 "Hour19_7pm" 19 "Hour18_6pm" 18 "Hour17_5pm" 17 "Hour16_4pm" 16 "Hour15_3pm" 15 "Hour14_2pm" 14 "Hour13_1pm" 13 "Hour12_12pm" 12 "Hour11_11am" 11 "Hour10_10am" 10 "Hour9_9am" 9 "Hour8_8am" 8 "Hour7_7am" 7 "Hour6_6am" 6 "Hour5_5am" 5 "Hour4_4am" 4 "Hour3_3am" 3 "Hour2_2am" 2 "Hour1_1am" 1 "Hour0_12am" 0 "Null" ;
VAL_ 739 EngExhMdeHrEnbl_D_Rq 3 "NotConfigured" 2 "Enabled" 1 "Disabled" 0 "Null" ;
VAL_ 739 Partial_Amp_Shutdown 1 "Active" 0 "Inactive" ;
VAL_ 739 HMI_HMIMode_St 7 "NotUsed2" 6 "NotUsed1" 5 "Load_Shed_Active" 0 "Invalid" 1 "OffMode" 2 "On" 3 "Phone" 4 "Climate" ;
VAL_ 553 DistToChrgrBynd_L_Actl 511 "Faulty" 510 "NoDataExists" ;
VAL_ 553 CCOI_PolicyClient_St 15 "NotUsed_4" 14 "NotUsed_3" 13 "NotUsed_2" 12 "NotUsed_1" 11 "DataStorageError" 10 "StateMachineInconsistent" 9 "UnrecoverableSyncError" 8 "OnBoardSyncFailed" 7 "OnBoardImplemented" 6 "OnBoardSynchronized" 5 "OnBoardSynchronizing" 4 "OnBoardSyncNeeded" 3 "OffBoardUpdatePending" 2 "OnBoardUpdatePending" 1 "Waiting" 0 "Null" ;
VAL_ 553 ResetAvgFe_B_Rq 1 "Reset" 0 "Null" ;
VAL_ 553 ResetTrip2_B_Rq 1 "Reset" 0 "Null" ;
VAL_ 553 SndImmrsnLvl_D_Rq 255 "NotUsed_127" 254 "NotUsed_126" 253 "NotUsed_125" 252 "NotUsed_124" 251 "NotUsed_123" 250 "NotUsed_122" 249 "NotUsed_121" 248 "NotUsed_120" 247 "NotUsed_119" 246 "NotUsed_118" 245 "NotUsed_117" 244 "NotUsed_116" 243 "NotUsed_115" 242 "NotUsed_114" 241 "NotUsed_113" 240 "NotUsed_112" 239 "NotUsed_111" 238 "NotUsed_110" 237 "NotUsed_109" 236 "NotUsed_108" 235 "NotUsed_107" 234 "NotUsed_106" 233 "NotUsed_105" 232 "NotUsed_104" 231 "NotUsed_103" 230 "NotUsed_102" 229 "NotUsed_101" 228 "NotUsed_100" 227 "NotUsed_99" 226 "NotUsed_98" 225 "NotUsed_97" 224 "NotUsed_96" 223 "NotUsed_95" 222 "NotUsed_94" 221 "NotUsed_93" 220 "NotUsed_92" 219 "NotUsed_91" 218 "NotUsed_90" 217 "NotUsed_89" 216 "NotUsed_88" 215 "NotUsed_87" 214 "NotUsed_86" 213 "NotUsed_85" 212 "NotUsed_84" 211 "NotUsed_83" 210 "NotUsed_82" 209 "NotUsed_81" 208 "NotUsed_80" 207 "NotUsed_79" 206 "NotUsed_78" 205 "NotUsed_77" 204 "NotUsed_76" 203 "NotUsed_75" 202 "NotUsed_74" 201 "NotUsed_73" 200 "NotUsed_72" 199 "NotUsed_71" 198 "NotUsed_70" 197 "NotUsed_69" 196 "NotUsed_68" 195 "NotUsed_67" 194 "NotUsed_66" 193 "NotUsed_65" 192 "NotUsed_64" 191 "NotUsed_63" 190 "NotUsed_62" 189 "NotUsed_61" 188 "NotUsed_60" 187 "NotUsed_59" 186 "NotUsed_58" 185 "NotUsed_57" 184 "NotUsed_56" 183 "NotUsed_55" 182 "NotUsed_54" 181 "NotUsed_53" 180 "NotUsed_52" 179 "NotUsed_51" 178 "NotUsed_50" 177 "NotUsed_49" 176 "NotUsed_48" 175 "NotUsed_47" 174 "NotUsed_46" 173 "NotUsed_45" 172 "NotUsed_44" 171 "NotUsed_43" 170 "NotUsed_42" 169 "NotUsed_41" 168 "NotUsed_40" 167 "NotUsed_39" 166 "NotUsed_38" 165 "NotUsed_37" 164 "NotUsed_36" 163 "NotUsed_35" 162 "NotUsed_34" 161 "NotUsed_33" 160 "NotUsed_32" 159 "NotUsed_31" 158 "NotUsed_30" 157 "NotUsed_29" 156 "NotUsed_28" 155 "NotUsed_27" 154 "NotUsed_26" 153 "NotUsed_25" 152 "NotUsed_24" 151 "NotUsed_23" 150 "NotUsed_22" 149 "NotUsed_21" 148 "NotUsed_20" 147 "NotUsed_19" 146 "NotUsed_18" 145 "NotUsed_17" 144 "NotUsed_16" 143 "NotUsed_15" 142 "NotUsed_14" 141 "NotUsed_13" 140 "NotUsed_12" 139 "NotUsed_11" 138 "NotUsed_10" 137 "NotUsed_9" 136 "NotUsed_8" 135 "NotUsed_7" 134 "NotUsed_6" 133 "NotUsed_5" 132 "NotUsed_4" 131 "NotUsed_3" 130 "NotUsed_2" 129 "NotUsed_1" 128 "Level127" 127 "Level126" 126 "Level125" 125 "Level124" 124 "Level123" 123 "Level122" 122 "Level121" 121 "Level120" 120 "Level119" 119 "Level118" 118 "Level117" 117 "Level116" 116 "Level115" 115 "Level114" 114 "Level113" 113 "Level112" 112 "Level111" 111 "Level110" 110 "Level109" 109 "Level108" 108 "Level107" 107 "Level106" 106 "Level105" 105 "Level104" 104 "Level103" 103 "Level102" 102 "Level101" 101 "Level100" 100 "Level99" 99 "Level98" 98 "Level97" 97 "Level96" 96 "Level95" 95 "Level94" 94 "Level93" 93 "Level92" 92 "Level91" 91 "Level90" 90 "Level89" 89 "Level88" 88 "Level87" 87 "Level86" 86 "Level85" 85 "Level84" 84 "Level83" 83 "Level82" 82 "Level81" 81 "Level80" 80 "Level79" 79 "Level78" 78 "Level77" 77 "Level76" 76 "Level75" 75 "Level74" 74 "Level73" 73 "Level72" 72 "Level71" 71 "Level70" 70 "Level69" 69 "Level68" 68 "Level67" 67 "Level66" 66 "Level65" 65 "Level64" 64 "Level63" 63 "Level62" 62 "Level61" 61 "Level60" 60 "Level59" 59 "Level58" 58 "Level57" 57 "Level56" 56 "Level55" 55 "Level54" 54 "Level53" 53 "Level52" 52 "Level51" 51 "Level50" 50 "Level49" 49 "Level48" 48 "Level47" 47 "Level46" 46 "Level45" 45 "Level44" 44 "Level43" 43 "Level42" 42 "Level41" 41 "Level40" 40 "Level39" 39 "Level38" 38 "Level37" 37 "Level36" 36 "Level35" 35 "Level34" 34 "Level33" 33 "Level32" 32 "Level31" 31 "Level30" 30 "Level29" 29 "Level28" 28 "Level27" 27 "Level26" 26 "Level25" 25 "Level24" 24 "Level23" 23 "Level22" 22 "Level21" 21 "Level20" 20 "Level19" 19 "Level18" 18 "Level17" 17 "Level16" 16 "Level15" 15 "Level14" 14 "Level13" 13 "Level12" 12 "Level11" 11 "Level10" 10 "Level9" 9 "Level8" 8 "Level7" 7 "Level6" 6 "Level5" 5 "Level4" 4 "Level3" 3 "Level2" 2 "Level1" 1 "Level0" 0 "Inactive" ;
VAL_ 553 InfoSysMasterPw_D_Stat 7 "NotUsed_6" 6 "NotUsed_5" 5 "NotUsed_4" 4 "NotUsed_3" 0 "Inactive" 1 "On" 2 "NotUsed_1" 3 "NotUsed_2" ;
VAL_ 553 ResetTrip1_B_Rq 1 "Reset" 0 "Null" ;
VAL_ 553 Disp_LangSel2_St 33 "Ukrainian" 32 "Indian_English" 31 "Thai" 30 "Slovak" 29 "Arabic" 28 "Taiwanese" 27 "Mandarin_Chinese" 26 "Korean" 25 "AU_English" 24 "Japanese" 23 "Braz_Portuguese" 22 "EU_Portuguese" 21 "Finish" 20 "Norwegian" 19 "Danish" 18 "Swedish" 17 "Hungarian" 16 "Greek" 15 "Czech" 14 "Polish" 13 "Flemish" 12 "Dutch" 11 "Russian" 10 "Turkish" 9 "Mex_Spanish" 8 "EU_Spanish" 7 "Cana_French" 6 "EU_French" 5 "Italian" 4 "German" 3 "NA_English" 2 "UK_English" 1 "Unknown" 0 "Invalid" ;
VAL_ 553 Disp_LangSel_St 31 "Thai" 30 "Slovak" 29 "Arabic" 28 "Taiwanese" 27 "Mandarin_Chinese" 26 "Korean" 25 "AU_English" 24 "Japanese" 23 "Braz_Portuguese" 22 "EU_Portuguese" 21 "Finish" 20 "Norwegian" 19 "Danish" 18 "Swedish" 17 "Hungarian" 16 "Greek" 15 "Czech" 14 "Polish" 13 "Flemish" 12 "Dutch" 11 "Russian" 10 "Turkish" 9 "Mex_Spanish" 8 "EU_Spanish" 7 "Cana_French" 6 "EU_French" 5 "Italian" 4 "German" 3 "NA_English" 2 "UK_English" 1 "Unknown" 0 "Invalid" ;
VAL_ 553 Diagnostic_Operation_Rq 7 "SignalStrength" 6 "SDARSESNNumber" 5 "SpeakerWalkAround" 4 "CalibrationPartNumber" 15 "Reserved" 3 "HardwarePartNumber" 2 "SoftwarePartNumber" 1 "GetAllBackgroundDiagRq" 0 "Inactive" ;
VAL_ 553 Bezel_Diag_Module_Rq 15 "Reserved" 3 "EFP" 2 "DSP_AMP" 1 "AHU" 0 "Inactive" ;
VAL_ 553 Audio_Demo_CMND 2 "On" 1 "Off" 0 "Inactive" ;
VAL_ 553 Audio_Visualizer 2 "On" 1 "Off" 0 "Inactive" ;
VAL_ 553 Surround_Sound_Upmix 2 "Surround" 1 "Stereo" 0 "Inactive" ;
VAL_ 553 Bezel_Diag_State_Rq 1 "Active" 0 "Inactive" ;
VAL_ 553 SurndSndUpmix2_D_Rq 4 "Audience" 3 "On_Stage" 2 "Surround" 1 "Stereo" 0 "Inactive" ;
VAL_ 1072 PtDrvMde_D_Rq 15 "Faulty" 14 "NotUsed11" 13 "NotUsed10" 12 "NotUsed9" 11 "NotUsed8" 10 "NotUsed7" 9 "NotUsed6" 8 "Track" 7 "Drag" 6 "Rock" 5 "Baja" 4 "Sand" 3 "TowHaulGradeAssist" 2 "SnowWet" 1 "Sport" 0 "Normal" ;
VAL_ 1072 DrvSlipCtlMde_D_Rq 3 "App_Specific_Off_Mode_3" 2 "App_Specific_Off_Mode_2" 1 "App_Specific_Off_Mode_1" 0 "Default_Mode" ;
VAL_ 1072 EngIdlShutDown_B_RqDrv 1 "Inhibit" 0 "No_Inibit" ;
VAL_ 1072 DrvPerfMde_D_Rq 3 "Sport" 2 "Normal" 1 "NotUsed" 0 "NoModeSelected" ;
VAL_ 1072 HsaMde_D_Rq 3 "Undefined" 2 "Manual" 1 "Automatic" 0 "Off" ;
VAL_ 1072 StopStrtDrvMde_D_RqMnu 3 "NotUsed2" 2 "NotUsed1" 1 "StopStart_Deselected" 0 "StopStart_Selected" ;
VAL_ 1072 NtrlTowMdeEnbl_B_RqDrv 1 "Yes" 0 "No" ;
VAL_ 1072 LscmbbStat_B_Actl 1 "On" 0 "Off" ;
VAL_ 1072 BulbChkActv_B_Stat 1 "Active" 0 "Inactive" ;
VAL_ 1072 ParkDetect_Stat 1 "Park" 0 "Not_Park" ;
VAL_ 1072 ReducedGuard_D_Rq 3 "NotUsed" 2 "On" 1 "Off" 0 "Null" ;
VAL_ 1072 FrostWarn_D_Stat 3 "NotUsed" 2 "On_Amber" 1 "On_Red" 0 "Off" ;
VAL_ 1072 TrlrBrkMde_D_Rq 1 "ElectricOverHydraulic" 0 "Electric" ;
VAL_ 1072 TRLR_SWAY_CONFIG_CMD 1 "On" 0 "Off" ;
VAL_ 1072 TRAILER_BRAKE_CONFIG 1 "Yes" 0 "No" ;
VAL_ 1072 Power_Liftgate_Mode_Cmd 1 "Enable" 0 "Disable" ;
VAL_ 1072 AccEnbl_B_RqDrv 1 "Adaptive_Cruise" 0 "Normal_Cruise" ;
VAL_ 1072 OdometerMasterValue 16777215 "Invalid" ;
VAL_ 1072 EngOilLife_B_RqReset 1 "Yes" 0 "No" ;
VAL_ 1072 MetricActvTe_B_Actl 1 "Active" 0 "Inactive" ;
VAL_ 1072 AccDeny_B_RqIpc 1 "Yes" 0 "No" ;
VAL_ 1072 ePRNDL_MODE 1 "On" 0 "Off" ;
VAL_ 1072 PrkLckCtlEnbl_D_RqIpc 3 "Rq_Towing" 2 "Rq_Enable" 1 "Rq_Disable" 0 "Null" ;
VAL_ 1072 HaDsplyCpblty_B_Stat 1 "Available" 0 "NotAvailable" ;
VAL_ 1072 DrvSlipCtlMde_B_Rq2 1 "Pressed" 0 "Not_Pressed" ;
VAL_ 1072 MetricActv_B_Actl 1 "Active" 0 "Inactive" ;
VAL_ 1072 KeyTypeChngMykey_D_Rq 3 "Search_PE_BackupSlot" 2 "Clear_All_MyKeys" 1 "Request_New_MyKey" 0 "None" ;
VAL_ 1072 ManRgen_D_Rq 3 "NotUsed2" 2 "NotUsed1" 1 "CustInitManExhFilterClean" 0 "No_Customer_Request" ;
VAL_ 1072 Fda_B_Stat 1 "On" 0 "Off" ;
VAL_ 534 WhlDirRr_D_Actl 3 "Faulty" 2 "NoDataExists" 1 "Backward" 0 "Forward" ;
VAL_ 534 WhlDirRl_D_Actl 3 "Faulty" 2 "NoDataExists" 1 "Backward" 0 "Forward" ;
VAL_ 534 WhlDirFr_D_Actl 3 "Faulty" 2 "NoDataExists" 1 "Backward" 0 "Forward" ;
VAL_ 534 WhlDirFl_D_Actl 3 "Faulty" 2 "NoDataExists" 1 "Backward" 0 "Forward" ;
VAL_ 76 AirbagDrv_D_Actv 3 "Faulty" 2 "On" 1 "Off" 0 "NotAvailable" ;
VAL_ 76 RstrnPsngrOn_D_Stat 15 "Faulty" 14 "NotUsed_11" 13 "NotUsed_10" 12 "ConfiguredOff" 11 "NotUsed_9" 10 "On" 9 "NotUsed_8" 8 "NotUsed_7" 7 "NotUsed_6" 6 "NotUsed_5" 5 "Off" 4 "NotUsed_4" 3 "NotUsed_3" 2 "NotUsed_2" 1 "NotUsed_1" 0 "NoAction" ;
VAL_ 76 PsngrFmidDetct_D_Actl 3 "Unknown" 2 "Empty" 1 "Occupied" 0 "Fault" ;
VAL_ 76 FirstRowBuckleMid 3 "Unknown" 2 "Unbelted" 1 "Belted" 0 "Faulty" ;
VAL_ 76 ThirdRowBucklePsngr 3 "Unknown" 2 "Unbelted" 1 "Belted" 0 "Faulty" ;
VAL_ 76 ThirdRowBuckleMid 3 "Unknown" 2 "Unbelted" 1 "Belted" 0 "Faulty" ;
VAL_ 76 ThirdRowBuckleDriver 3 "Unknown" 2 "Unbelted" 1 "Belted" 0 "Faulty" ;
VAL_ 76 SecondRowBucklePsngr 3 "Unknown" 2 "Unbelted" 1 "Belted" 0 "Faulty" ;
VAL_ 76 SecondRowBuckleMid 3 "Unknown" 2 "Unbelted" 1 "Belted" 0 "Faulty" ;
VAL_ 76 SecondRowBuckleDriver 3 "Unknown" 2 "Unbelted" 1 "Belted" 0 "Faulty" ;
VAL_ 76 FirstRowBuckleDriver 3 "Unknown" 2 "Unbelted" 1 "Belted" 0 "Faulty" ;
VAL_ 76 RILReq 3 "Not_Used" 2 "Plant_Mode" 1 "On" 0 "Off" ;
VAL_ 76 FirstRowBucklePsngr 3 "Unknown" 2 "Unbelted" 1 "Belted" 0 "Faulty" ;
VAL_ 76 RstrnImpactEvntStatus 7 "Invalid" 6 "Not_Used_4" 5 "Threshold_2_Exceeded" 4 "Not_Used_3" 3 "Threshold_1_Exceeded" 2 "Not_Used_2" 1 "Not_Used_1" 0 "Normal" ;
VAL_ 76 PsngrFrntDetct_D_Actl 3 "Unknown" 2 "Empty" 0 "Faulty" 1 "Occupied" ;
VAL_ 76 EDRTriggerEvntSync 1 "Threshold_Exceeded" 0 "Normal" ;
VAL_ 76 PassRstrnInd_Req 3 "ABOnNotIllum_OffNotIllum" 2 "AirbagOnNot_Illum_OffIllum" 1 "AirbagOn_Illum_OffNotIllum" 0 "AirbagOn_Illum_Off_Illum" ;
VAL_ 1085 ULoRgenTestMde_B_Stat 1 "Active" 0 "Inactive" ;
VAL_ 1085 PwSrcULoOvrTe_B_Actl 1 "Yes" 0 "No" ;
VAL_ 1085 PwSrcULoOn_B_Actl 1 "Operating" 0 "Not_Operating" ;
VAL_ 1085 PwSrcULoFalt_D_Stat 3 "Fault_No_Output" 2 "Fault_Reduced_Output" 1 "Fault_NonSpecific" 0 "No_Fault" ;
VAL_ 1085 PwSrcULoDcnnt_B_Stat 1 "Loose_or_Disconnected" 0 "Connected" ;
VAL_ 1085 PwSrcULo_Pc_Mx 255 "Fault" ;
VAL_ 1085 BattTracCool_D_RqDcdc 3 "NotUsed" 2 "DCDC_Overtemperature" 1 "CoolingRequiredbyDCDC" 0 "NoCoolingRequiredbyDCDC" ;
VAL_ 1085 PwSrcULoComm_B_Falt 1 "Fault" 0 "No_Fault" ;
VAL_ 1085 DcdcULo_U_Actl 255 "Fault" ;
VAL_ 1085 DcdcUHi_I_Actl 255 "Fault" ;
VAL_ 1085 PwSrcULo_I_Mx 255 "Fault" ;
VAL_ 1085 PwSrcULo_I_Actl 255 "Fault" ;
VAL_ 1085 DcdcUHi_U_Actl 1023 "Fault" 1022 "NoDataExists" ;
VAL_ 514 StrtrMtrDlyStrt_B_Stat 1 "Yes" 0 "No" ;
VAL_ 514 VehVTrlrAid_B_Avail 1 "Yes" 0 "No" ;
VAL_ 514 StrtrMtrCtlMsgTxt_D_Rq 7 "Start_In_Gear_Allowed" 6 "Pending_Start_Cancelled" 5 "Start_Pending_Please_Wait" 4 "Cranking_Limit_Exceeded" 3 "Press_Brk_and_Shift_to_P_N" 2 "Press_Clutch_and_Brake" 1 "Press_Clutch_To_Start" 0 "No_Display" ;
VAL_ 514 VehVActlEng_D_Qf 3 "OK" 2 "Not_Within_Specifications" 1 "No_Data_Exists" 0 "Faulty" ;
VAL_ 514 GearRvrse_D_Actl 7 "Fault" 6 "NotUsed_3" 5 "NotUsed_2" 4 "NotUsed_1" 3 "Active_confirmed" 2 "Active_not_confirmed" 1 "Inactive_confirmed" 0 "Inactive_not_confirmed" ;
VAL_ 514 StrtrMtrCtlMsgTxt_D2_Rq 3 "NoRequestPcmStartingMsgCtl" 2 "ShiftToNeutralToStart" 1 "ShiftToParkToStart" 0 "NoRequestBcmStartingMsgCtl" ;
VAL_ 560 BtsiShifInhbt_B_RqTrn 1 "Yes" 0 "No" ;
VAL_ 560 SelDrvMdeSwtch_D_Stat3 3 "Faulty" 2 "SwitchState2" 1 "SwitchState1" 0 "NotPressed" ;
VAL_ 560 TrnGbox_Rt_Actl 65535 "Fault" 65534 "Unknown" ;
VAL_ 560 TrnSrvcRqd_B_Rq 1 "On" 0 "Off" ;
VAL_ 560 TrnCnvtClu_D_Actl 3 "Transition_or_Micro_Slip" 2 "Lock_Up_Fixed" 1 "Lock_Up_Slip" 0 "No_Lock_Up" ;
VAL_ 560 TrnShifActv_B_Actl 1 "Active" 0 "Inactive" ;
VAL_ 560 RtmTerrMdeChng_D_Rdy 7 "Fault" 6 "Undefined_2" 5 "Undefined_1" 4 "ModeUnavailDrInputRqd" 3 "SpOpModes_NotSupported" 2 "ModeUnavailDynamicCond" 1 "Module_In_Initialization" 0 "Mode_Change_Available" ;
VAL_ 560 RtmTerrMde_D_Actl 7 "Fail_Safe_Default" 6 "Dynamic_Mode" 5 "Rock_Crawl_Mode" 4 "Mud_Ruts_Mode" 3 "Sand_Mode" 2 "Undefined" 1 "Low_Mu_Mode" 0 "Special_Operating_Mode_Off" ;
VAL_ 560 GearLvrPos_D_Actl 15 "Fault" 14 "Unknown_Position" 13 "Undefined_Treat_as__Fault" 12 "Undefined_Treat_as_Fault" 11 "sixth" 10 "fifth" 9 "fourth" 8 "third" 7 "second" 6 "first" 5 "Low" 4 "Sport_DriveSport" 3 "Drive" 2 "Neutral" 1 "Reverse" 0 "Park" ;
VAL_ 560 GboxOil_Te_Actl 255 "Faulty" 254 "NoDataExists" ;
VAL_ 817 ChildLckMde_B_Stat 1 "Enable" 0 "Disable" ;
VAL_ 817 VehLckInd_D_Rq 3 "NotUsed" 2 "On_Day" 1 "On_Night" 0 "Off" ;
VAL_ 817 DrTgateOpen_B_Rq 1 "Open" 0 "Null" ;
VAL_ 817 DrTgateExtSwMde_B_Stat 1 "Enable" 0 "Disable" ;
VAL_ 817 Remote_Device_Feedback 7 "Unused3" 6 "Unused2" 5 "Unused1" 4 "Shutdown" 3 "Running" 2 "Starting" 1 "Acknowledge" 0 "Null" ;
VAL_ 817 Veh_Lock_Requestor 31 "Walk_Away_Locking" 30 "Remote_Park_Assist" 29 "DoorsOffToOn_Smart_Unlock" 28 "Rgtm_Shutlock_Switch" 27 "Boundary_Alert" 26 "Transit_Vehicle_Relock" 25 "Transit_Cargo_Relock" 24 "Transit_Ajar_Lock" 23 "Diagnostics" 22 "Console_Lock" 21 "Child_Lock" 20 "Double_Lock" 19 "Passive_Pasenger" 18 "Passive_Driver" 17 "Slam_Lock_Protect" 16 "SYNC" 15 "Passport" 14 "Passive_Smart_Unlock" 13 "Autorelock" 12 "RemoteStart" 0 "Null" 1 "Autolock" 11 "Smart_Unlock" 10 "Sliding_Door" 9 "Passive" 8 "Remote" 7 "Programming" 6 "Powerslide" 5 "Keypad" 4 "Key_Cylinder" 3 "Interior" 2 "Auto_Unlock" ;
VAL_ 817 R_Pwr_Sliding_Dr_Rqst 1 "Active" 0 "Null" ;
VAL_ 817 Power_Liftgate_Rqst 1 "Active" 0 "Null" ;
VAL_ 817 Power_Decklid_Rqst 1 "Active" 0 "Null" ;
VAL_ 817 L_Pwr_Sliding_Dr_Rqst 1 "Active" 0 "Null" ;
VAL_ 817 Veh_Lock_Sub_Id 15 "Unused7" 14 "Unused6" 13 "Unused5" 12 "Unused4" 11 "Unused3" 10 "Unused2" 9 "Unused1" 8 "Customer_8" 7 "Customer_7" 6 "Customer_6" 5 "Customer_5" 4 "Customer_4" 3 "Customer_3" 2 "Customer_2" 1 "Customer_1" 0 "Null" ;
VAL_ 817 Veh_Lock_Status 3 "UNLOCK_DRV" 2 "UNLOCK_ALL" 1 "LOCK_ALL" 0 "LOCK_DBL" ;
VAL_ 817 WindowLockout_B_Stat 1 "Locked" 0 "Unlock" ;
VAL_ 817 Lockmsgtxt_D_Rq 7 "MSG7" 6 "MSG6" 5 "MSG5" 4 "MSG4" 3 "MSG3" 2 "MSG2" 1 "MSG1" 0 "NO_WARNING" ;
VAL_ 817 FobComm_D_Stat 3 "NotUsed" 2 "RemEngStartOK" 1 "RemEngStartFail" 0 "Null" ;
VAL_ 817 LockInhibit 1 "Inhibit" 0 "No_Inhibit" ;
VAL_ 1084 BattULoState_D_Qlty 3 "OK" 2 "Not_Within_Specifications" 1 "Eval_In_Progress" 0 "Fault" ;
VAL_ 1084 BSFault 1 "Fault" 0 "No_Fault" ;
VAL_ 1084 BattULo2_Te_Actl 127 "Fault" ;
VAL_ 1068 EngStrtInhbt_B_RqBatt 1 "Start_Inhibit" 0 "Dont_Care" ;
VAL_ 1068 BattULoChrg_D_Rq 3 "Low_Battery_Temperature" 2 "Charging_Requested" 1 "Chrg_Requested_HighCurrent" 0 "No_Request" ;
VAL_ 1068 PwSysULoFalt_D_Stat 15 "Not_Used_6" 14 "LowBatterySOC" 13 "PSS_Shed2_Contin" 12 "Not_Used_4" 11 "Not_Used_3" 10 "Not_Used_2" 9 "BattMonitoringSensorFault" 8 "LowBattVoltDuringPwSrcOn" 7 "LowBatt2_PowerSaveMode" 6 "LowBatt1_Warning" 5 "Overvoltage" 4 "Fault_NoOutput" 3 "Fault_ReducedOutput" 2 "Fault_Nonspecific" 1 "Cluster_Proveout" 0 "No_Fault" ;
VAL_ 1068 Shed_T_Eng_Off_B 1 "Active" 0 "Inactive" ;
VAL_ 1068 Shed_Feature_Group_ID 16 "PtcHeater" 30 "NotUsed_7" 29 "NotUsed_6" 28 "NotUsed_5" 27 "NotUsed_4" 26 "NotUsed_3" 25 "NotUsed_2" 24 "NotUsed_1" 23 "Dcac" 22 "UpFitter_6" 21 "UpFitter_5" 20 "UpFitter_4" 19 "UpFitter_3" 18 "UpFitter_2" 17 "UpFitter_1" 14 "HtdMirr" 13 "HvacRearBlwr_Third" 12 "HvacRearBlwr_Second" 11 "HvacRearBlwr_First" 31 "All LSHED1 Features" 10 "Htd_Windscrn" 9 "SpltHtdBcklight_HtdMirr" 8 "HtdBcklight_HtdMirr" 7 "HtdCoolSeat_FrtDriver" 6 "HtdCoolSeat_FrtPass" 5 "HtdCoolSeat_RearPass" 4 "HtdCoolSeat_RearDriver" 3 "SmartTrlrTowBattCharge" 2 "Htd_StrWhl" 1 "Htd_Washer_Fluid" 0 "No_LSHED1_Features" 15 "Engine_Coolant_Fan" ;
VAL_ 1068 Shed_Drain_Eng_Off_B 1 "Active" 0 "Inactive" ;
VAL_ 1068 Shed_Level_Req 7 "SHED3" 6 "Loads_On" 5 "SHED_ENG_OFF" 4 "SOON_ENG_OFF" 3 "SHED2_CONTIN" 2 "SHED2_TRANS" 1 "SHED1" 0 "NO_SHED" ;
VAL_ 1068 ULoRgenTestMde_B_Rq 1 "Request" 0 "NoRequest" ;
VAL_ 1068 ChargeMode 7 "Undefined_2" 6 "Undefined_1" 5 "Battery_Identify" 4 "Battery_Refresh" 3 "SlowRegenAllowNoDischarge" 2 "Fast_Regen_Allowed" 1 "Slow_Regen_Allowed" 0 "Conventional_Charging" ;
VAL_ 1068 IdleSpeedIncrease_El 1 "Yes" 0 "No" ;
VAL_ 1068 Batt_Lo_SoC_B 1 "Active" 0 "Inactive" ;
VAL_ 1068 PeriodicElLoad_B_Stat 1 "Active" 0 "Inactive" ;
VAL_ 1068 Batt_Crit_SoC_B 1 "Active" 0 "Inactive" ;
VAL_ 1144 AwdLckMde_D_Stat 7 "NotUsed_2" 6 "NotUsed_1" 5 "PrimaryAxleSpeedControl" 4 "DualAxleSpeedControl" 3 "EfficiencySplit" 2 "SecondaryAxleTorqueCtrl" 1 "SecondaryAxleSpeedCtrl" 0 "Off" ;
VAL_ 1144 BattTracCool_B_Actl 1 "On" 0 "Off" ;
VAL_ 1144 BattChrgInhbt_D2_Rq 7 "NotUsed_4" 6 "NotUsed_3" 5 "NotUsed_2" 4 "NotUsed_1" 3 "MaintainTargetSoc" 2 "EndAtTarget" 1 "InhibitCharging" 0 "Enable_Charging" ;
VAL_ 1144 BattChrgTrgtSoC_D_Rq 7 "Percent_50" 6 "Percent_60" 5 "Percent_70" 4 "Percent_80" 3 "Percent_85" 2 "Percent_90" 1 "Percent_95" 0 "Percent_100" ;
VAL_ 1144 CabnEvapSovFront_B_Rq 1 "On" 0 "Off" ;
VAL_ 1144 HeatCoreSovRear_B_Rq 1 "On" 0 "Off" ;
VAL_ 1144 BattChlrSov_B_Rq 1 "On" 0 "Off" ;
VAL_ 1144 CabnEvapSovRear_B_Rq 1 "On" 0 "Off" ;
VAL_ 1144 BrkAppl_D_RqPt 3 "BrakesSlowRelease" 2 "BrakesFastRelease" 1 "BrakesEngage" 0 "NotActive" ;
VAL_ 1144 BattClntVlvOvrrd_D_Rq 3 "NotUsed" 2 "OverrideTbcvToChiller" 1 "OverrideTbcvToRadiator" 0 "NoOverrideToTbcvCLogic" ;
VAL_ 1144 BattTracChillerOn_B_Rq 1 "On" 0 "Off" ;
VAL_ 1144 BattTracChiller_D_Stat 3 "NotUsed" 2 "ChillerNotAvailable" 1 "ChillerBrieflyAvailable" 0 "ChillerAvailable" ;
VAL_ 1144 HtrnDcdcDis_B_Rq 1 "Yes" 0 "No" ;
VAL_ 1144 HtrnCnnctPwr_B_Stat 1 "Asserted" 0 "NotAsserted" ;
VAL_ 1144 PtcHtr_D_Stat 3 "Faulty" 2 "NotUsed" 1 "On" 0 "Off" ;
VAL_ 1144 WakeAlarm0_B_Typ 1 "CanAndEcuDriveCircuit" 0 "CanOnly" ;
VAL_ 1144 HtrnClntFlw_D_Rq 3 "High" 2 "Medium" 1 "Low" 0 "Off" ;
VAL_ 1144 BattTracDrvSustn_B_Rq 1 "Active" 0 "Inactive" ;
VAL_ 1144 CabinDrvSustn_B_Rq 1 "Active" 0 "Inactive" ;
VAL_ 1144 ChrgNowEvnt_B_Stat 1 "Active" 0 "Inactive" ;
VAL_ 1144 PreCondBatt_B_Actl 1 "On" 0 "Off" ;
VAL_ 1144 BattTracClntVlv_B_Rq 1 "On" 0 "Off" ;
VAL_ 1144 ULoBattTrnsfrSustn_B_Rq 1 "Active" 0 "Inactive" ;
VAL_ 1144 ULoBattTransfer_D_Stat 7 "NotUsed_2" 6 "NotUsed_1" 5 "TransferError" 4 "TransferComplete" 3 "TransferThroughGridEnergy" 2 "InsufficientEnergyToXfer" 1 "TransferInProgress" 0 "NoTransfer" ;
VAL_ 1144 BattTracClimtDis_B_Stat 1 "Enable" 0 "Disable" ;
VAL_ 1200 BrkRearPCorrltn_B_Stat 1 "Yes" 0 "No" ;
VAL_ 1200 HsaTrnAout_Tq_Rq 65535 "Fault" 65534 "Unknown" ;
VAL_ 1200 BrkBstrVac_P_Actl 127 "Invalid" ;
VAL_ 1200 YawStabilityIndex 511 "Fault" 510 "NoDataExists" ;
VAL_ 1200 BrkTot_Tq_RqDrv 8191 "Fault" ;
VAL_ 1200 HsaStat_D_Dsply 7 "NotUsed3" 6 "NotUsed2" 5 "NotUsed1" 4 "NotAvailable" 3 "SlowReleaseWithChime" 2 "SlowReleaseWithoutChime" 1 "Active" 0 "Inactive" ;
VAL_ 1200 BrkHold_D_Stat 7 "NotUsed_3" 6 "NotUsed_2" 5 "NotUsed_1" 4 "HeldSecondary" 3 "HeldSecure" 2 "Held" 1 "Inactive" 0 "Off" ;
